VERSION "Version"

NS_ :

BS_:

BU_: IID IDC CCU Tester CCURT1 CCURT2 CCU3 CCU4 AVAS LCUFL LCUFR LCURL LCURR ZCUF ZCUL ZCUR ZCUT PADS MFS VDC ITS BCB IPS DCDC PCU EOP DCU BMC SRS EPS RBM IBCS AMP WHUD ADC RADARRR RADARRL RADARFR RADARFL RPC IFC RADARFRT RADARR HDMAP SBM WCM ETC TBOX DSM FLPDM FRPDM RLPDM RRPDM
VAL_TABLE_ BCS_FLWheelSpdEdgesSumVD 1 "Valid" 0 "Not valid" ;
VAL_TABLE_ UINM_PADS_CruSetSpeedRollerDir 3 "Not used" 2 "Backward" 1 "Forward" 0 "Not rotated" ;
VAL_TABLE_ UINM_PADS_CustomSWStVD 1 "valid" 0 "Not valid" ;
VAL_TABLE_ UINM_PADS_OKSWStuckSt 1 "stuck" 0 "Normal" ;
VAL_TABLE_ UINM_PADS_OKSWStVD 1 "valid" 0 "Not valid" ;
VAL_TABLE_ UINM_PADS_OKSWSt 1 "active" 0 "not active" ;
VAL_TABLE_ UINM_PADS_FolDistDecSWStuckSt 1 "stuck" 0 "Normal" ;
VAL_TABLE_ UINM_PADS_FolDistDecSWStVD 1 "valid" 0 "Not valid" ;
VAL_TABLE_ UINM_PADS_FolDistDecSWSt 1 "active" 0 "not active" ;
VAL_TABLE_ UINM_PADS_FolDistIncSWStuckSt 1 "stuck" 0 "Normal" ;
VAL_TABLE_ UINM_PADS_FolDistIncSWStVD 1 "Description for the value '0x1'" 0 "Not valid" ;
VAL_TABLE_ UINM_PADS_FolDistIncSWSt 1 "active" 0 "not active" ;
VAL_TABLE_ UINM_PADS_CruSetSpeedRollerSt 1 "-offset:0" 0 "-resolution: 1 per bit" ;
VAL_TABLE_ UINM_PADS_IDC_PlaySWStuckSt 1 "stuck" 0 "Normal" ;
VAL_TABLE_ UINM_PADS_IDC_PlaySWStVD 1 "valid" 0 "Not valid" ;
VAL_TABLE_ UINM_PADS_IDC_PlaySWSt 1 "active" 0 "not active" ;
VAL_TABLE_ UINM_PADS_IDC_SkipDecSWStuckSt 1 "stuck" 0 "Normal" ;
VAL_TABLE_ UINM_PADS_IDC_SkipDecSWStVD 1 "Description for the value '0x1'" 0 "Not valid" ;
VAL_TABLE_ UINM_PADS_IDC_SkipDecSWSt 1 "active" 0 "not active" ;
VAL_TABLE_ UINM_PADS_IDC_SkipIncSWStuckSt 1 "stuck" 0 "Normal" ;
VAL_TABLE_ UINM_PADS_IDC_SkipIncSWStVD 1 "valid" 0 "Not valid" ;
VAL_TABLE_ UINM_PADS_IDC_SkipIncSWSt 1 "active" 0 "not active" ;
VAL_TABLE_ UINM_PADS_VolRollerRotatedDir 3 "Not used" 2 "Backward" 1 "Forward" 0 "Not rotated" ;
VAL_TABLE_ UINM_PADS_VolRollerSt 1 "-offset:0" 0 "-resolution: 1 per bit" ;
VAL_TABLE_ UINM_PADS_CustomSWstuck 1 "stuck" 0 "Normal" ;
VAL_TABLE_ UINM_PADS_CustomSWSt 1 "active" 0 "not active" ;
VAL_TABLE_ UINM_PADS_IDC_PhoneStuckSt 1 "stuck" 0 "Normal" ;
VAL_TABLE_ UINM_PADS_IDC_PhoneSWStVD 1 "valid" 0 "Not valid" ;
VAL_TABLE_ UINM_PADS_IDC_PhoneSWSt 1 "active" 0 "not active" ;
VAL_TABLE_ UINM_PADS_IDC_VrSWStuckSt 1 "stuck" 0 "Normal" ;
VAL_TABLE_ UINM_PADS_IDC_VrSWStVD 1 "valid" 0 "Not valid" ;
VAL_TABLE_ UINM_PADS_IDC_VrSWSt 1 "active" 0 "not active" ;
VAL_TABLE_ UINM_PADS_IDC_ViewSWStuckSt 1 "stuck" 0 "Normal" ;
VAL_TABLE_ UINM_PADS_IDC_ViewSWVD 1 "Valid" 0 "Not valid" ;
VAL_TABLE_ UINM_PADS_IDC_ViewSWSt 1 "active" 0 "not active" ;

BO_ 3221225472 VECTOR__INDEPENDENT_SIG_MSG: 0 Vector__XXX
 SG_ CCU_1_Dummy6 : 0|8@1- (1,0) [0|0] "" Vector__XXX
 SG_ CCU_1_Dummy5 : 0|8@1- (1,0) [-128|127] "" Vector__XXX
 SG_ CCU_1_Dummy4 : 0|8@1- (1,0) [-128|127] "" Vector__XXX
 SG_ CCU_1_Dummy4 : 0|64@1- (1,0) [0|0] "" Vector__XXX
 SG_ CCU_1_Dummy3 : 0|10@0+ (1,0) [0|0] "" Vector__XXX
 SG_ CCU_1_Dummy2 : 0|48@0+ (1,0) [0|0] "" Vector__XXX
 SG_ CCU_1_Dummy1 : 0|64@0+ (1,0) [0|0] "" Vector__XXX
 SG_ PAA_VideoSt : 0|3@0+ (1,0) [0|7] "" Vector__XXX
 SG_ VCU_3_Dummy10 : 0|18@0+ (1,0) [0|262143] "" Vector__XXX
 SG_ VCU_3_Dummy9 : 0|51@0+ (1,0) [0|1.84467440737096E+019] "" Vector__XXX
 SG_ VCU_3_Dummy8 : 0|40@0+ (1,0) [0|0] "" Vector__XXX
 SG_ VCU_3_Dummy7 : 0|64@0+ (1,0) [0|0] "" Vector__XXX
 SG_ VCU_3_Dummy6 : 0|11@0+ (1,0) [0|0] "" Vector__XXX
 SG_ VCU_3_Dummy5 : 0|3@0+ (1,0) [0|0] "" Vector__XXX
 SG_ VCU_3_Dummy3 : 0|57@0+ (1,0) [0|0] "" Vector__XXX
 SG_ VCU_3_Dummy2 : 0|64@0+ (1,0) [0|0] "" Vector__XXX
 SG_ VCU_3_Dummy1 : 0|64@0+ (1,0) [0|0] "" Vector__XXX
 SG_ EPS_1_C_Dummy9 : 0|32@0+ (1,0) [0|0] "" Vector__XXX
 SG_ EPS_1_C_Dummy8 : 0|63@0+ (1,0) [0|0] "" Vector__XXX
 SG_ EPS_1_C_Dummy7 : 0|49@0+ (1,0) [0|0] "" Vector__XXX
 SG_ EPS_1_C_Dummy6 : 0|64@0+ (1,0) [0|0] "" Vector__XXX
 SG_ EPS_1_C_Dummy5 : 0|9@0+ (1,0) [0|0] "" Vector__XXX
 SG_ EPS_1_C_Dummy4 : 0|56@0+ (1,0) [0|0] "" Vector__XXX
 SG_ EPS_1_C_Dummy3 : 0|64@0+ (1,0) [0|0] "" Vector__XXX
 SG_ EPS_1_C_Dummy2 : 0|64@0+ (1,0) [0|0] "" Vector__XXX
 SG_ EPS_1_C_Dummy1 : 0|64@0+ (1,0) [0|0] "" Vector__XXX

BO_ 165 IDC_7: 64 IDC
 SG_ ACU_RecpLevelCfg : 345|3@0+ (1,0) [0|7] ""  VDC,CCU,CCURT1

BO_ 1045 IDC_6: 64 IDC
 SG_ ACU_NaviDestInformation : 348|3@0+ (1,0) [0|7] ""  CCU,CCURT1,VDC
 SG_ ACU_NaviViapoint_remainingSoc : 345|10@0+ (0.1,0) [0|100] "%"  CCU,CCURT1,VDC
 SG_ ACU_NaviViapointType : 434|3@0+ (1,0) [0|7] ""  CCU,CCURT1,VDC
 SG_ ACU_NaviViapointtime : 429|11@0+ (1,0) [0|2047] "min"  CCU,CCURT1,VDC
 SG_ ACU_NaviViapointDistance : 402|21@0+ (1,0) [0|2097151] "m"  CCU,CCURT1,VDC
 SG_ ACU_NaviDestTime : 399|12@0+ (1,0) [0|4095] "min"  CCU,CCURT1,VDC
 SG_ ACU_NaviDestDistance : 367|32@0+ (1,0) [0|4294967295] "m"  CCU,CCURT1,VDC

BO_ 742 CCU_ZCUT_MCM_1: 64 CCU
 SG_ SSW_RRMassageSt : 103|2@0+ (1,0) [0|3] ""  IDC
 SG_ SSW_RRLumbarModeSt : 101|3@0+ (1,0) [0|7] ""  IDC
 SG_ SSW_RRSPAMode : 98|2@0+ (1,0) [0|3] ""  IDC
 SG_ SSW_RRMassageModeSt : 95|4@0+ (1,0) [0|15] ""  IDC
 SG_ SSW_RRMassageForceSt : 91|4@0+ (1,0) [0|15] ""  IDC
 SG_ SSW_RLMassageSt : 39|2@0+ (1,0) [0|3] ""  IDC
 SG_ SSW_RLLumbarModeSt : 37|3@0+ (1,0) [0|7] ""  IDC
 SG_ SSW_RLSPAMode : 34|2@0+ (1,0) [0|3] ""  IDC
 SG_ SSW_RLMassageModeSt : 31|4@0+ (1,0) [0|15] ""  IDC
 SG_ SSW_RLMassageForceSt : 27|4@0+ (1,0) [0|15] ""  IDC

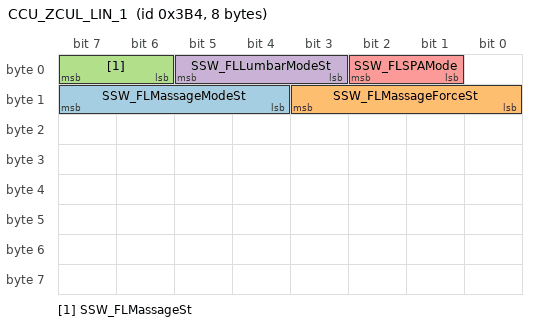
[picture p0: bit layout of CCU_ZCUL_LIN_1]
BO_ 948 CCU_ZCUL_LIN_1: 8 CCU
 SG_ SSW_FLMassageModeSt : 15|4@0+ (1,0) [0|15] ""  IDC
 SG_ SSW_FLMassageForceSt : 11|4@0+ (1,0) [0|15] ""  IDC
 SG_ SSW_FLMassageSt : 7|2@0+ (1,0) [0|3] ""  IDC
 SG_ SSW_FLLumbarModeSt : 5|3@0+ (1,0) [0|7] ""  IDC
 SG_ SSW_FLSPAMode : 2|2@0+ (1,0) [0|3] ""  IDC

BO_ 850 CCU_ZCUT_SCMRR_1: 24 CCU
 SG_ SSW_RRSeatHeatSt : 71|2@0+ (1,0) [0|3] ""  IDC
 SG_ SSW_RRSeatVentSt : 33|2@0+ (1,0) [0|3] ""  IDC

BO_ 849 CCU_ZCUT_SCMRL_1: 24 CCU
 SG_ SSW_RLSeatHeatSt : 71|2@0+ (1,0) [0|3] ""  IDC
 SG_ SSW_RLSeatVentSt : 33|2@0+ (1,0) [0|3] ""  IDC

BO_ 653 VCU_5: 64 CCU
 SG_ VCU_ShootLaunchSt : 34|2@0+ (1,0) [0|3] ""  IBCS,IDC
 SG_ VCU_BrkPedPst : 156|8@0+ (0.392,0) [0|99.96] "%"  ADC,CCURT2,IBCS,IDC,IFC,RBM,SRS
 SG_ VCU_CrntGearLvl : 143|3@0+ (1,0) [0|7] ""  ADC,AMP,CCURT2,EPS,IBCS,IDC,IFC,RBM,SRS,TBOX,ZCUF,ZCUL,ZCUR,ZCUT
 SG_ VCU_BrkPedPstVD : 128|1@0+ (1,0) [0|1] ""  ADC,CCURT2,IBCS,IDC,IFC,RBM,SRS
 SG_ VCU_EMS_BrkPedalSt : 63|1@0+ (1,0) [0|1] ""  ADC,CCURT2,IBCS,IDC,IFC,RBM,SBM,SRS,TBOX,ZCUR
 SG_ VCU_EMS_AccPedalActPst : 40|8@0+ (0.392,0) [0|99.96] "%"  ADC,AMP,CCURT2,IBCS,IDC,IFC,RBM,SRS,TBOX

BO_ 1031 CCU_TBOX_1: 64 CCU
 SG_ TEL_TelematicsModeActSt : 31|3@0+ (1,0) [0|7] ""  IDC
 SG_ TEL_PhoneCallSt : 28|3@0+ (1,0) [0|7] ""  IDC
 SG_ TEL_PhoneNumber : 39|48@0+ (1,0) [0|0] ""  IDC
 SG_ TEL_ResetFailReason : 87|8@0+ (1,0) [0|255] ""  IDC
 SG_ TEL_ModuleResetSt : 95|2@0+ (1,0) [0|3] ""  IDC

BO_ 189 AMP_2: 64 AMP
 SG_ AMP_GetAmpMcuVerInfo : 7|112@0+ (1,0) [0|0] ""  IDC
 SG_ AMP_GetAmpDspVerInfo : 119|112@0+ (1,0) [0|0] ""  IDC
 SG_ AMP_GetAmpHwVerInfo : 231|48@0+ (1,0) [0|0] ""  IDC
 SG_ AMP_GetAmpCfgInfo : 279|128@0+ (1,0) [0|0] ""  IDC

BO_ 363 CCU_EPS_1_C: 64 CCU
 SG_ EPS_1_C_Dummy10 : 247|5@0+ (1,0) [0|0] ""  ADC,CCURT1,CCURT2,IBCS,IDC,IFC,RBM,VDC
 SG_ EPS_1_C_Dummy9 : 31|24@0+ (1,0) [0|0] ""  IDC,ADC,CCU,CCURT1,CCURT2,IBCS,IFC,RBM,VDC
 SG_ EPS_1_C_Dummy8 : 70|63@0+ (1,0) [0|0] ""  IDC,ADC,CCU,CCURT1,CCURT2,IBCS,IFC,RBM,VDC
 SG_ EPS_1_C_Dummy7 : 131|49@0+ (1,0) [0|0] ""  IDC,ADC,CCU,CCURT1,CCURT2,IBCS,IFC,RBM,VDC
 SG_ EPS_1_C_Dummy6 : 178|59@0+ (1,0) [0|5.76460752303423E+017] ""  IDC,ADC,CCU,CCURT1,CCURT2,IBCS,IFC,RBM,VDC
 SG_ EPS_1_C_Dummy5 : 240|9@0+ (1,0) [0|0] ""  IDC,ADC,CCU,CCURT1,CCURT2,IBCS,IFC,RBM,VDC
 SG_ EPS_1_C_Dummy4 : 271|56@0+ (1,0) [0|0] ""  IDC,ADC,CCU,CCURT1,CCURT2,IBCS,IFC,RBM,VDC
 SG_ EPS_1_C_Dummy3 : 327|64@0+ (1,0) [0|0] ""  IDC,ADC,CCU,CCURT1,CCURT2,IBCS,IFC,RBM,VDC
 SG_ EPS_1_C_Dummy2 : 391|64@0+ (1,0) [0|0] ""  IDC,ADC,CCU,CCURT1,CCURT2,IBCS,IFC,RBM,VDC
 SG_ EPS_1_C_Dummy1 : 455|64@0+ (1,0) [0|0] ""  ADC,CCU,CCURT1,CCURT2,IBCS,IFC,RBM,VDC,IDC
 SG_ EPS_1_Counter : 23|8@0+ (1,0) [0|0] ""  IDC,ADC,CCU,CCURT1,CCURT2,IBCS,IFC,RBM,VDC
 SG_ EPS_AssistRatio : 263|8@0+ (1,0) [0|255] ""  IDC
 SG_ EPS_WarnLamp : 242|2@0+ (1,0) [0|3] ""  IDC
 SG_ EPS_SteeringModeSt : 133|2@0+ (1,0) [0|3] ""  IDC
 SG_ EPS_FunctionStyleSt : 135|2@0+ (1,0) [0|3] ""  IDC
 SG_ EPS_SteeringAngleVD : 71|1@0+ (1,0) [0|1] ""  IDC
 SG_ EPS_SteeringAngle : 55|16@0+ (0.1,-780) [-780|779.9] "deg"  IDC
 SG_ EPS_1_CRC : 7|16@0+ (1,0) [0|65535] ""  IDC,ADC,CCU,CCURT1,CCURT2,IBCS,IFC,RBM,VDC

BO_ 430 CCU_SRS_1: 64 CCU
 SG_ SRS_YawRate : 167|16@0+ (0.01,-180) [-180|180] "deg/s"  IDC
 SG_ SRS_VehLatrlAccel : 147|12@0+ (0.001,-2) [2|2] "g"  IDC
 SG_ SRS_VehLongAccel : 143|12@0+ (0.001,2) [2|2] "g"  IDC
 SG_ SRS_NearCrashOutputSt : 34|1@0+ (1,0) [0|1] ""  CCU,CCURT1,CCURT2,IDC,TBOX,VDC
 SG_ SRS_RolloverCrashOutpuSt : 35|1@0+ (1,0) [0|1] ""  CCU,CCURT2,IDC,TBOX
 SG_ SRS_Rear_CrashOutputSt : 36|1@0+ (1,0) [0|1] ""  CCU,CCURT2,IDC,TBOX
 SG_ SRS_RightSide_CrashOutputSt : 37|1@0+ (1,0) [0|1] ""  CCU,CCURT2,IDC,TBOX
 SG_ SRS_LeftSide_CrashOutputSt : 38|1@0+ (1,0) [0|1] ""  CCU,CCURT2,IDC,TBOX
 SG_ SRS_Front_CrashOutputSt : 39|1@0+ (1,0) [0|1] ""  CCU,CCURT2,IDC,TBOX
 SG_ SRS_CrashOutputSt : 31|8@0+ (1,0) [0|160] ""  IDC,CCU,CCURT1,CCURT2,TBOX,VDC

BO_ 334 CCU_15: 64 CCURT1
 SG_ CSM_RC_NextStartTimeCDS : 245|6@0+ (1,0) [0|60] ""  IDC
 SG_ CSM_RC_NextStartTimeCDMi : 235|6@0+ (1,0) [0|60] ""  IDC
 SG_ CSM_RC_NextStartTimeCDH : 224|5@0+ (1,0) [0|24] ""  IDC
 SG_ CSM_RC_NextStartTimeCDD : 229|5@0+ (1,0) [0|31] ""  IDC
 SG_ CSM_RC_NextStartTimeS : 309|6@0+ (1,0) [0|60] ""  IDC
 SG_ CSM_RC_NextStartTimeMi : 299|6@0+ (1,0) [0|60] ""  IDC
 SG_ CSM_RC_NextStartTimeH : 288|5@0+ (1,0) [0|24] ""  IDC
 SG_ CSM_RC_NextStartTimeD : 293|5@0+ (1,0) [0|31] ""  IDC
 SG_ CSM_RC_NextStartTimeMo : 283|4@0+ (1,0) [0|12] ""  IDC
 SG_ CSM_RC_NextStartTimeY : 279|8@0+ (1,2020) [0|2275] ""  IDC

BO_ 348 CCU_SECSYN: 16 CCU
 SG_ CCU_SecSynMAC_Check : 47|88@0+ (1,0) [0|1] ""  ADC,IDC,ZCUF,ZCUL,ZCUR,ZCUT
 SG_ CCU_SecSynResetCounter : 31|16@0+ (1,0) [0|1] ""  ADC,IDC,ZCUF,ZCUL,ZCUR,ZCUT
 SG_ CCU_SecSynCounter : 7|24@0+ (1,0) [0|1] ""  ADC,IDC,ZCUF,ZCUL,ZCUR,ZCUT

BO_ 944 CCU_BMC_3: 64 CCU
 SG_ BMC_3_Dummy8 : 31|48@0+ (1,0) [0|0] ""  DCU,BCB,IDC
 SG_ BMC_3_Dummy7 : 79|64@0+ (1,0) [0|0] ""  DCU,BCB,IDC
 SG_ BMC_3_Dummy6 : 143|64@0+ (1,0) [0|0] ""  DCU,BCB,IDC
 SG_ BMC_3_Dummy5 : 207|64@0+ (1,0) [0|0] ""  DCU,BCB,IDC
 SG_ BMC_3_Dummy4 : 271|64@0+ (1,0) [0|0] ""  DCU,BCB,IDC
 SG_ BMC_3_Dummy3 : 329|50@0+ (1,0) [0|0] ""  DCU,BCB,IDC
 SG_ BMC_3_Dummy2 : 391|64@0+ (1,0) [0|0] ""  DCU,BCB,IDC
 SG_ BMC_3_Dummy1 : 455|64@0+ (1,0) [0|0] ""  DCU,BCB,IDC
 SG_ BMC_LvPwrSysMsgOperationFlag : 330|1@0+ (1,0) [0|1] ""  IDC
 SG_ BMS_Err2NoticeFlag : 331|1@0+ (1,0) [0|1] ""  IDC
 SG_ BMS_ErrNoticeOperationFlag : 332|1@0+ (1,0) [0|1] ""  IDC
 SG_ BMS_ErrNotice : 335|3@0+ (1,0) [0|7] ""  IDC
 SG_ BMC_3_CRC : 7|16@0+ (1,0) [0|65535] ""  BCB,DCU,IDC
 SG_ BMC_3_Counter : 23|8@0+ (1,0) [0|255] ""  DCU,BCB,IDC

BO_ 188 ACU_AMP_1: 64 IDC
 SG_ ACU_MediaPathSet : 247|3@0+ (1,0) [0|7] ""  AMP
 SG_ ACU_NotificationDuckSet : 235|4@0+ (1,0) [0|15] ""  AMP
 SG_ ACU_RingtoneDuckSet : 239|4@0+ (1,0) [0|15] ""  AMP
 SG_ ACU_BTCallDuckSet : 227|4@0+ (1,0) [0|15] ""  AMP
 SG_ ACU_ECallBCallDuckSet : 231|4@0+ (1,0) [0|15] ""  AMP
 SG_ ACU_VRDuckSet : 219|4@0+ (1,0) [0|15] ""  AMP
 SG_ ACU_NaviDuckSet : 223|4@0+ (1,0) [0|15] ""  AMP
 SG_ ACU_AtmosphereMusicDuckSet : 211|4@0+ (1,0) [0|15] ""  AMP
 SG_ ACU_MediaDuckSet : 215|4@0+ (1,0) [0|15] ""  AMP
 SG_ ACU_FamilyCinemaSwitchSts : 201|2@0+ (1,0) [0|3] ""  AMP
 SG_ ACU_A2BSet : 203|2@0+ (1,0) [0|3] ""  AMP
 SG_ ACU_OutcarMediaSwitch : 205|2@0+ (1,0) [0|3] ""  AMP
 SG_ ACU_AVASSwitch : 207|2@0+ (1,0) [0|3] ""  AMP
 SG_ ACU_GetIntVoltReq : 194|2@0+ (1,0) [0|3] ""  AMP
 SG_ ACU_GetTempReq : 196|2@0+ (1,0) [0|3] ""  AMP
 SG_ ACU_AVASMode : 199|3@0+ (1,0) [0|7] ""  AMP
 SG_ ACU_ESEType : 186|3@0+ (1,0) [0|7] ""  AMP
 SG_ ACU_ESESwitchSts : 188|2@0+ (1,0) [0|3] ""  AMP
 SG_ ACU_ESEMode : 191|3@0+ (1,0) [0|7] ""  AMP
 SG_ ACU_AdigoVirtualLiveSetReq : 179|4@0+ (1,0) [0|15] ""  AMP
 SG_ ACU_StrSurSet : 183|4@0+ (1,0) [0|15] ""  AMP
 SG_ ACU_SeatsmodelSet : 170|3@0+ (1,0) [0|7] ""  AMP
 SG_ ACU_Headrest_Mode : 172|2@0+ (1,0) [0|3] ""  AMP
 SG_ ACU_Cabin_ambiencemodeSet : 175|3@0+ (1,0) [0|7] ""  AMP
 SG_ ACU_HeadrestCodriverVolumeSet : 167|8@0+ (1,0) [0|255] ""  AMP
 SG_ ACU_HeadrestDriverVolumeSet : 159|8@0+ (1,0) [0|255] ""  AMP
 SG_ ACU_Headrest_R_PrivateModeVolSet : 151|8@0+ (1,0) [0|255] ""  AMP
 SG_ ACU_Headrest_Left_PrivateModeVol : 143|8@0+ (1,0) [0|255] ""  AMP
 SG_ ACU_OutcarFrontMediaVolSet : 135|8@0+ (1,0) [0|255] ""  AMP
 SG_ ACU_OutcarFrontSPKVolSet : 127|8@0+ (1,0) [0|255] ""  AMP
 SG_ ACU_Cabin_ambienceVolSet : 119|8@0+ (1,0) [0|255] ""  AMP
 SG_ ACU_MainVolSet : 111|8@0+ (1,0) [0|255] ""  AMP
 SG_ ACU_PhoneRingVolSet : 103|8@0+ (1,0) [0|255] ""  AMP
 SG_ ACU_NaviVolSet : 95|8@0+ (1,0) [0|255] ""  AMP
 SG_ ACU_VRVolSet : 87|8@0+ (1,0) [0|255] ""  AMP
 SG_ ACU_TelVolSet : 79|8@0+ (1,0) [0|255] ""  AMP
 SG_ ACU_SpeakRR : 65|2@0+ (1,0) [0|3] ""  AMP
 SG_ ACU_SpeakRL : 67|2@0+ (1,0) [0|3] ""  AMP
 SG_ ACU_SpeakFR : 69|2@0+ (1,0) [0|3] ""  AMP
 SG_ ACU_SpeakFL : 71|2@0+ (1,0) [0|3] ""  AMP
 SG_ ACU_MuteSet : 57|2@0+ (1,0) [0|1] ""  AMP
 SG_ ACU_MuteRearSet : 59|2@0+ (1,0) [0|3] ""  AMP
 SG_ ACU_VSCModeReq : 48|3@0+ (1,0) [0|7] ""  AMP
 SG_ ACU_HighFrqSet : 53|5@0+ (1,0) [0|31] ""  AMP
 SG_ ACU_MidFrqSet : 42|5@0+ (1,0) [0|31] ""  AMP
 SG_ ACU_LowFrqSet : 47|5@0+ (1,0) [0|31] ""  AMP
 SG_ ACU_FaderSet : 36|5@0+ (1,0) [0|31] ""  AMP
 SG_ ACU_BlcSet : 25|5@0+ (1,0) [0|31] ""  AMP
 SG_ ACU_VRSourceSet : 28|3@0+ (1,0) [0|7] ""  AMP
 SG_ ACU_TelSourceSet : 31|3@0+ (1,0) [0|7] ""  AMP
 SG_ ACU_WarningSourceSet : 11|4@0+ (1,0) [0|15] ""  AMP
 SG_ ACU_MediaSourceSet : 15|4@0+ (1,0) [0|15] ""  AMP
 SG_ ACU_SpeakMid : 1|2@0+ (1,0) [0|3] ""  AMP
 SG_ ACU_NaviSourceSet : 4|3@0+ (1,0) [0|7] ""  AMP
 SG_ ACU_BeepSourceSet : 7|3@0+ (1,0) [0|7] ""  AMP

BO_ 767 AMP_1: 64 AMP
 SG_ AMP_MediaPathSt : 271|3@0+ (1,0) [0|7] ""  IDC
 SG_ AMP_NotificationDuckSet : 259|4@0+ (1,0) [0|15] ""  IDC
 SG_ AMP_RingtoneDuckSet : 263|4@0+ (1,0) [0|15] ""  IDC
 SG_ AMP_BTCallDuckSet : 251|4@0+ (1,0) [0|15] ""  IDC
 SG_ AMP_ECallBCallDuckSet : 255|4@0+ (1,0) [0|15] ""  IDC
 SG_ AMP_VRDuckSet : 243|4@0+ (1,0) [0|15] ""  IDC
 SG_ AMP_NaviDuckSet : 247|4@0+ (1,0) [0|15] ""  IDC
 SG_ AMP_AtmosphereMusicDuckSet : 235|4@0+ (1,0) [0|15] ""  IDC
 SG_ AMP_MediaDuckSet : 239|4@0+ (1,0) [0|15] ""  IDC
 SG_ AMP_BeepSourceSts : 7|3@0+ (1,0) [0|7] ""  IDC
 SG_ AMP_NaviSourceSt : 4|3@0+ (1,0) [0|7] ""  IDC
 SG_ AMP_SpeakMid : 1|2@0+ (1,0) [0|3] ""  IDC
 SG_ AMP_MediaSourceSt : 15|4@0+ (1,0) [0|15] ""  IDC
 SG_ AMP_WarningSourceSts : 11|4@0+ (1,0) [0|15] ""  IDC
 SG_ AMP_TelSourceSts : 31|3@0+ (1,0) [0|7] ""  IDC
 SG_ AMP_VRSourceSts : 28|3@0+ (1,0) [0|7] ""  IDC
 SG_ AMP_BlcSetSt : 25|5@0+ (1,0) [0|31] ""  IDC
 SG_ AMP_FadeSetSt : 36|5@0+ (1,0) [0|31] ""  IDC
 SG_ AMP_LowFrqSet : 47|5@0+ (1,0) [0|31] ""  IDC
 SG_ AMP_MidFrqSet : 42|5@0+ (1,0) [0|31] ""  IDC
 SG_ AMP_HighFrqSet : 53|5@0+ (1,0) [0|31] ""  IDC
 SG_ AMP_VSCModeSt : 48|3@0+ (1,0) [0|7] ""  IDC
 SG_ AMP_DriveSideSt : 61|2@0+ (1,0) [0|3] ""  IDC
 SG_ AMP_MuteRearSet : 59|2@0+ (1,0) [0|3] ""  IDC
 SG_ AMP_MuteSt : 57|2@0+ (1,0) [0|3] ""  IDC
 SG_ AMP_SpeakFL : 71|2@0+ (1,0) [0|3] ""  IDC
 SG_ AMP_SpeakrFR : 69|2@0+ (1,0) [0|3] ""  IDC
 SG_ AMP_SpeakrRL : 67|2@0+ (1,0) [0|3] ""  IDC
 SG_ AMP_SpeakrRR : 65|2@0+ (1,0) [0|3] ""  IDC
 SG_ AMP_TelVolSetSts : 79|8@0+ (1,0) [0|255] ""  IDC
 SG_ AMP_VRVolSetSts : 87|8@0+ (1,0) [0|255] ""  IDC
 SG_ AMP_NaviVolSetSts : 95|8@0+ (1,0) [0|255] ""  IDC
 SG_ AMP_PhoneRingVolSetSts : 103|8@0+ (1,0) [0|255] ""  IDC
 SG_ AMP_MainVolSetSts : 111|8@0+ (1,0) [0|255] ""  IDC
 SG_ AMP_Cabin_ambienceVolSetSts : 119|8@0+ (1,0) [0|255] ""  IDC
 SG_ AMP_OutcarFrontSPKVolSetSts : 127|8@0+ (1,0) [0|255] ""  IDC
 SG_ AMP_OutcarFrontMediaVolSetSts : 135|8@0+ (1,0) [0|255] ""  IDC
 SG_ AMP_Headrest_Left_PrivateModeVol : 143|8@0+ (1,0) [0|255] ""  IDC
 SG_ AMP_Headrest_Right_PrivateModeVo : 151|8@0+ (1,0) [0|255] ""  IDC
 SG_ AMP_HeadrestDriverVolumeSt : 159|8@0+ (1,0) [0|255] ""  IDC
 SG_ AMP_Cabin_ambiencemodeSet : 175|3@0+ (1,0) [0|7] ""  IDC
 SG_ AMP_Headrest_Mode : 172|2@0+ (1,0) [0|3] ""  IDC
 SG_ AMP_SeatsmodeSet : 170|3@0+ (1,0) [0|7] ""  IDC
 SG_ AMP_StrSurSet : 183|4@0+ (1,0) [0|15] ""  IDC
 SG_ AMP_AdigoVirtualLiveSeSts : 179|4@0+ (1,0) [0|15] ""  IDC
 SG_ AMP_ESEMode : 191|3@0+ (1,0) [0|7] ""  IDC
 SG_ AMP_ESESwitchSts : 188|2@0+ (1,0) [0|3] ""  IDC
 SG_ AMP_ESEType : 186|3@0+ (1,0) [0|7] ""  IDC
 SG_ AMP_AVASMode : 199|3@0+ (1,0) [0|7] ""  IDC
 SG_ AMP_AVASSwitch : 207|2@0+ (1,0) [0|3] ""  IDC
 SG_ AMP_OutcarMediaSwitch : 205|2@0+ (1,0) [0|3] ""  IDC
 SG_ AMP_A2BSet : 203|2@0+ (1,0) [0|3] ""  IDC
 SG_ AMP_FamilyCinemaSwitchSts : 201|2@0+ (1,0) [0|3] ""  IDC
 SG_ AMP_TempValue : 215|8@0+ (1,0) [0|255] ""  IDC
 SG_ AMP_VolValue : 223|8@0+ (1,0) [0|255] ""  IDC
 SG_ AMP_GetHUTInfoSts : 231|2@0+ (1,0) [0|3] ""  IDC
 SG_ AMP_HeadrestCodriverVolumeSt : 167|8@0+ (1,0) [0|255] ""  IDC

BO_ 873 CCU_DCDC_2: 32 CCU
 SG_ DCDC_FaultLampInd : 53|1@0+ (1,0) [0|1] ""  IDC
 SG_ DCDC_FaultLampIndOperationFlag : 48|1@0+ (1,0) [0|1] ""  IDC

BO_ 163 IDC_11: 64 IDC
 SG_ ACU_DPMessageSt : 79|3@0+ (1,0) [0|7] ""  CCU
 SG_ ACU_RAEBcfg : 2|2@0+ (1,0) [0|2] ""  ADC,CCU
 SG_ ACU_ParkingBoxAngle : 111|12@0+ (0.1,-180) [-180|180] ""  ADC,CCU
 SG_ ACU_ParkingBoxMidY : 91|12@0+ (1,0) [0|1079] ""  ADC,CCU
 SG_ ACU_ParkingBoxMidX : 87|12@0+ (1,0) [0|1919] ""  ADC,CCU
 SG_ ACU_AVPMessageSt : 52|3@0+ (1,0) [0|7] ""  ADC,CCU
 SG_ ACU_HPAMessageSt : 55|3@0+ (1,0) [0|7] ""  ADC,CCU
 SG_ ACU_APAMessageSt : 43|3@0+ (1,0) [0|7] ""  ADC,CCU
 SG_ ACU_NDAVoicePromptTypeCfg : 127|2@0+ (1,0) [0|3] ""  ADC,CCU
 SG_ ACU_LowPowerConfig : 114|3@0+ (1,0) [0|7] ""  ADC,CCU
 SG_ ACU_PCSModeSt : 115|1@0+ (1,0) [0|1] ""  ADC,CCU
 SG_ ACU_PCS_MirrorpagedownButtonST : 0|1@0+ (1,0) [0|1] ""  ADC,CCU
 SG_ ACU_DisplayReq : 71|2@0+ (1,0) [0|3] ""  ADC,CCU
 SG_ ACU_PCS_ScreenCoordX : 39|12@0+ (1,0) [0|2559] ""  ADC,CCU
 SG_ ACU_PCS_ScreenCoordY : 19|12@0+ (1,0) [0|1439] ""  ADC,CCU
 SG_ ACU_PCS_ScreenTouchSignal : 66|2@0+ (1,0) [0|3] ""  CCU
 SG_ ACU_PCS_ER_QuitConfirm : 56|1@0+ (1,0) [0|1] ""  ADC,CCU
 SG_ ACU_PCS_ER_EnterCmd : 67|1@0+ (1,0) [0|1] ""  ADC,CCU
 SG_ ACU_ER_FuncCfg : 69|2@0+ (1,0) [0|3] ""  ADC,CCU
 SG_ ACU_PCS_SVM_FunctionCmd : 23|4@0+ (1,0) [0|15] ""  ADC,CCU
 SG_ ACU_LanguageTypeSet : 13|6@0+ (1,0) [0|63] ""  ADC,CCU
 SG_ ACU_PCS_ScreenTouchSt : 15|2@0+ (1,0) [0|3] ""  ADC,CCU
 SG_ ACU_SVM_Button : 3|1@0+ (1,0) [0|1] ""  ADC,CCU
 SG_ ACU_PAAMode : 7|4@0+ (1,0) [0|15] ""  CCU,ADC

BO_ 739 IDC_IID_1: 64 IDC
 SG_ IDC_ICM_2_Dummy6 : 487|32@0+ (1,0) [0|4294967295] "" Vector__XXX
 SG_ IDC_ICM_2_Dummy5 : 423|64@0+ (1,0) [0|0] "" Vector__XXX
 SG_ IDC_ICM_2_Dummy4 : 359|64@0+ (1,0) [0|0] "" Vector__XXX
 SG_ IDC_ICM_2_Dummy3 : 295|64@0+ (1,0) [0|0] "" Vector__XXX
 SG_ IDC_ICM_2_Dummy2 : 231|64@0+ (1,0) [0|0] "" Vector__XXX
 SG_ Reserve : 63|24@0+ (1,0) [0|0] "" Vector__XXX
 SG_ ICM_VehicleSpeed : 55|8@0+ (1,0) [0|254] "km/h"  IID
 SG_ ICM_FS_Enable : 31|8@0+ (1,0) [0|255] ""  IID
 SG_ IDC_IID_1_CRC : 7|16@0+ (1,0) [0|65535] ""  IID
 SG_ ICM_ADAS4Lamp : 223|8@0+ (1,0) [0|255] ""  IID
 SG_ ICM_ADAS3Lamp : 215|8@0+ (1,0) [0|255] ""  IID
 SG_ ICM_ADAS2Lamp : 207|8@0+ (1,0) [0|255] ""  IID
 SG_ ICM_ADAS1Lamp : 199|8@0+ (1,0) [0|255] ""  IID
 SG_ ICM_HandsOffLamp : 191|8@0+ (1,0) [0|255] ""  IID
 SG_ ICM_BrakeLamp : 183|8@0+ (1,0) [0|255] ""  IID
 SG_ ICM_EPBLamp : 175|8@0+ (1,0) [0|255] ""  IID
 SG_ ICM_PlugConnectLamp : 167|8@0+ (1,0) [0|255] ""  IID
 SG_ ICM_DCDCFailLamp : 159|8@0+ (1,0) [0|255] ""  IID
 SG_ ICM_DynamicalsystemFailLamp : 151|8@0+ (1,0) [0|255] ""  IID
 SG_ ICM_SRSLamp : 143|8@0+ (1,0) [0|255] ""  IID
 SG_ ICM_EPSLamp : 135|8@0+ (1,0) [0|255] ""  IID
 SG_ ICM_EPBFailLamp : 127|8@0+ (1,0) [0|255] ""  IID
 SG_ ICM_ESPOFFLamp : 119|8@0+ (1,0) [0|255] ""  IID
 SG_ ICM_ESPLamp : 111|8@0+ (1,0) [0|255] ""  IID
 SG_ ICM_ABSLamp : 103|8@0+ (1,0) [0|255] ""  IID
 SG_ DataLength : 95|8@0+ (1,0) [0|255] ""  IID
 SG_ SID : 87|8@0+ (1,0) [0|255] ""  IID
 SG_ ICM_GearInfo : 47|8@0+ (1,0) [0|255] ""  IID
 SG_ ICM_Theme : 39|8@0+ (1,0) [0|255] ""  IID
 SG_ IDC_IID_1_Counter : 23|8@0+ (1,0) [0|255] ""  IID

BO_ 918 CCU_PADS_1: 32 CCU
 SG_ UINM_PADS_VolRollerVD : 62|1@0+ (1,0) [0|1] ""  IDC
 SG_ UINM_PADS_VolRollerSt : 37|6@0+ (1,0) [0|63] ""  IDC
 SG_ UINM_PADS_VolRollerRotatedDir : 29|2@0+ (1,0) [0|3] ""  IDC
 SG_ UINM_PADS_R_UpSWStVD : 167|1@0+ (1,0) [0|1] ""  IDC
 SG_ UINM_PADS_R_UpSWSt : 166|1@0+ (1,0) [0|1] ""  IDC
 SG_ UINM_PADS_R_UDRollerVD : 182|1@0+ (1,0) [0|1] ""  IDC
 SG_ UINM_PADS_R_UDRollerRSt : 181|6@0+ (1,0) [0|63] ""  IDC
 SG_ UINM_PADS_R_UDRollerRotatedDir : 175|2@0+ (1,0) [0|3] ""  IDC
 SG_ UINM_PADS_R_RightSWStVD : 173|1@0+ (1,0) [0|1] ""  IDC
 SG_ UINM_PADS_R_RightSWSt : 172|1@0+ (1,0) [0|1] ""  IDC
 SG_ UINM_PADS_R_LRRollerVD : 183|1@0+ (1,0) [0|1] ""  IDC
 SG_ UINM_PADS_R_LRRollerRSt : 191|6@0+ (1,0) [0|63] ""  IDC
 SG_ UINM_PADS_R_LRRollerRotatedDir : 185|2@0+ (1,0) [0|3] ""  IDC
 SG_ UINM_PADS_R_LeftSWStVD : 171|1@0+ (1,0) [0|1] ""  IDC
 SG_ UINM_PADS_R_leftSWSt : 170|1@0+ (1,0) [0|1] ""  IDC
 SG_ UINM_PADS_R_DownSWStVD : 169|1@0+ (1,0) [0|1] ""  IDC
 SG_ UINM_PADS_R_DownSWSt : 168|1@0+ (1,0) [0|1] ""  IDC
 SG_ UINM_PADS_L_UpSWStVD : 141|1@0+ (1,0) [0|1] ""  IDC
 SG_ UINM_PADS_L_UpSWSt : 140|1@0+ (1,0) [0|1] ""  IDC
 SG_ UINM_PADS_L_UDRollerRSt : 157|6@0+ (1,0) [0|63] ""  IDC
 SG_ UINM_PADS_L_UDRollerRotatedDir : 149|2@0+ (1,0) [0|3] ""  IDC
 SG_ UINM_PADS_L_RightSWStVD : 147|1@0+ (1,0) [0|1] ""  IDC
 SG_ UINM_PADS_L_RightSWSt : 146|1@0+ (1,0) [0|1] ""  IDC
 SG_ UINM_PADS_L_LRRollerVD : 159|1@0+ (1,0) [0|1] ""  IDC
 SG_ UINM_PADS_L_LRRollerRSt : 165|6@0+ (1,0) [0|63] ""  IDC
 SG_ UINM_PADS_L_LRRollerRotatedDir : 151|2@0+ (1,0) [0|3] ""  IDC
 SG_ UINM_PADS_L_LeftSWStVD : 145|1@0+ (1,0) [0|1] ""  IDC
 SG_ UINM_PADS_L_leftSWSt : 144|1@0+ (1,0) [0|1] ""  IDC
 SG_ UINM_PADS_L_DownSWStVD : 143|1@0+ (1,0) [0|1] ""  IDC
 SG_ UINM_PADS_L_DownSWSt : 142|1@0+ (1,0) [0|1] ""  IDC
 SG_ UINM_PADS_Custom2SWStVD : 110|1@0+ (1,0) [0|1] ""  IDC
 SG_ UINM_PADS_Custom2SWSt : 109|1@0+ (1,0) [0|1] ""  IDC
 SG_ UINM_PADS_CruSetSpeedRollerVD : 63|1@0+ (1,0) [0|1] ""  IDC
 SG_ UINM_PADS_Custom2SWStuckSt : 111|1@0+ (1,0) [0|1] ""  IDC
 SG_ UINM_PADS_CruSetSpeedRollerRotat : 46|2@0+ (1,0) [0|3] ""  ADC,IDC
 SG_ UINM_PADS_OKSWStuckSt : 61|1@0+ (1,0) [0|1] ""  ADC,IDC
 SG_ UINM_PADS_OKSWStVD : 60|1@0+ (1,0) [0|1] ""  ADC,IDC
 SG_ UINM_PADS_OKSWSt : 59|1@0+ (1,0) [0|1] ""  ADC,IDC
 SG_ UINM_PADS_FolDistDecSWStuckSt : 58|1@0+ (1,0) [0|1] ""  ADC,IDC
 SG_ UINM_PADS_FolDistDecSWStVD : 57|1@0+ (1,0) [0|1] ""  ADC,IDC
 SG_ UINM_PADS_FolDistDecSWSt : 56|1@0+ (1,0) [0|1] ""  ADC,IDC
 SG_ UINM_PADS_FolDistIncSWStuckSt : 55|1@0+ (1,0) [0|1] ""  ADC,IDC
 SG_ UINM_PADS_FolDistIncSWStVD : 54|1@0+ (1,0) [0|1] ""  ADC,IDC
 SG_ UINM_PADS_FolDistIncSWSt : 47|1@0+ (1,0) [0|1] ""  ADC,IDC
 SG_ UINM_PADS_CruSetSpeedRollerSt : 53|6@0+ (1,0) [0|63] ""  ADC,IDC
 SG_ UINM_PADS_IDC_PlaySWStuckSt : 44|1@0+ (1,0) [0|1] ""  ADC,IDC
 SG_ UINM_PADS_IDC_PlaySWStVD : 43|1@0+ (1,0) [0|1] ""  ADC,IDC
 SG_ UINM_PADS_IDC_PlaySWSt : 42|1@0+ (1,0) [0|1] ""  ADC,IDC
 SG_ UINM_PADS_IDC_SkipDecSWStuckSt : 41|1@0+ (1,0) [0|1] ""  ADC,IDC
 SG_ UINM_PADS_IDC_SkipDecSWStVD : 40|1@0+ (1,0) [0|1] ""  ADC,IDC
 SG_ UINM_PADS_IDC_SkipDecSWSt : 39|1@0+ (1,0) [0|1] ""  ADC,IDC
 SG_ UINM_PADS_IDC_SkipIncSWStuckSt : 38|1@0+ (1,0) [0|1] ""  ADC,IDC
 SG_ UINM_PADS_IDC_SkipIncSWStVD : 31|1@0+ (1,0) [0|1] ""  ADC,IDC
 SG_ UINM_PADS_IDC_SkipIncSWSt : 30|1@0+ (1,0) [0|1] ""  ADC,IDC
 SG_ UINM_PADS_CustomSWstuck : 27|1@0+ (1,0) [0|1] ""  ADC,IDC
 SG_ UINM_PADS_CustomSWStVD : 26|1@0+ (1,0) [0|1] ""  ADC,IDC
 SG_ UINM_PADS_CustomSWSt : 25|1@0+ (1,0) [0|1] ""  ADC,IDC
 SG_ UINM_PADS_IDC_PhoneStuckSt : 24|1@0+ (1,0) [0|1] ""  ADC,IDC
 SG_ UINM_PADS_IDC_PhoneSWStVD : 23|1@0+ (1,0) [0|1] ""  ADC,IDC
 SG_ UINM_PADS_IDC_PhoneSWSt : 22|1@0+ (1,0) [0|1] ""  ADC,IDC
 SG_ UINM_PADS_IDC_VrSWStuckSt : 21|1@0+ (1,0) [0|1] ""  ADC,IDC
 SG_ UINM_PADS_IDC_VrSWStVD : 20|1@0+ (1,0) [0|1] ""  ADC,IDC
 SG_ UINM_PADS_IDC_VrSWSt : 19|1@0+ (1,0) [0|1] ""  ADC,IDC
 SG_ UINM_PADS_IDC_ViewSWStuckSt : 18|1@0+ (1,0) [0|1] ""  ADC,IDC
 SG_ UINM_PADS_IDC_ViewSWVD : 17|1@0+ (1,0) [0|1] ""  ADC,IDC
 SG_ UINM_PADS_IDC_ViewSWSt : 16|1@0+ (1,0) [0|1] ""  ADC,IDC

BO_ 905 IDC_ICM_1: 64 IDC
 SG_ ICM_SoundWarnSilenceReq : 169|1@0+ (1,0) [0|1] ""  CCU,CCURT1,CCURT2
 SG_ ICM_DispTheme : 183|3@0+ (1,0) [0|7] ""  CCU,CCURT2
 SG_ ICM_DisplayID : 268|4@0+ (1,0) [0|15] ""  CCU
 SG_ ICM_VehInsSpd_accurate : 272|11@0+ (0.1,0) [0|204] "km/h"  CCURT1,VDC,CCU,CCURT2
 SG_ ICM_VehRunningOdometer : 356|17@0+ (1,0) [0|99999] "km"  CCU,CCURT2
 SG_ ICM_VehRunningOdometerTemp : 341|17@0+ (1,0) [0|9999] "km"  CCU,CCURT2
 SG_ ICM_VehRunningTimeTemp : 321|12@0+ (1,0) [0|4095] "min"  CCU,CCURT2
 SG_ ICM_TotalAvaibleDriveDistance : 316|11@0+ (1,0) [0|2047] "km"  CCU,CCURT2
 SG_ ICM_FuelAvaibleDriveDistance : 311|11@0+ (1,0) [0|2047] "km"  CCU,CCURT2
 SG_ ICM_FuelLevelValue : 303|8@0+ (0.3,0) [0|75] "L"  CCU,CCURT2
 SG_ ICM_BackLightLevel_accurate : 279|7@0+ (1,0) [0|100] "%"  CCU,CCURT2
 SG_ ICM_MFSButtonSt : 31|4@0+ (1,0) [0|15] ""  CCU,CCURT2
 SG_ ICM_SetIACCSt : 27|1@0+ (1,0) [0|1] ""  CCU,CCURT2
 SG_ ICM_VehicleBrakeSt : 26|1@0+ (1,0) [0|1] ""  CCU,CCURT2
 SG_ ICM_AirbagLampFaultSt : 25|1@0+ (1,0) [0|1] ""  CCU,CCURT2
 SG_ ICM_ChargingSt : 24|1@0+ (1,0) [0|1] ""  CCU,CCURT2
 SG_ ICM_BackLightLevel : 39|4@0+ (1,0) [0|15] ""  CCU,CCURT2
 SG_ ICM_TotalOdometer : 35|20@0+ (1,0) [0|999999] "km"  CCU,CCURT2
 SG_ ICM_VehAverageSpd : 63|8@0+ (1,0) [0|254] "km/h"  CCU,CCURT2
 SG_ ICM_BFLWarning : 71|1@0+ (1,0) [0|1] ""  CCU,CCURT2
 SG_ ICM_TripAVD : 70|1@0+ (1,0) [0|1] ""  CCU,CCURT2
 SG_ ICM_TripA : 69|14@0+ (0.1,0) [0|999.9] "km"  CCU,CCURT2
 SG_ ICM_ElcConspAccumAvgClnCmd : 87|1@0+ (1,0) [0|1] ""  CCU,CCURT2
 SG_ ICM_TripBVD : 86|1@0+ (1,0) [0|1] ""  CCU,CCURT2
 SG_ ICM_TripB : 85|14@0+ (1,0) [0|9999] "km"  CCU,CCURT2
 SG_ ICM_VehInsSpd : 103|8@0+ (1,0) [0|254] "km/h"  CCU,CCURT2
 SG_ ICM_BattVolt : 111|8@0+ (0.1,0) [0|25.4] "V"  CCU,CCURT2
 SG_ ICM_BattVoltVD : 119|1@0+ (1,0) [0|1] ""  CCU,CCURT2
 SG_ ICM_DisFail : 118|1@0+ (1,0) [0|1] ""  CCU,CCURT2
 SG_ ICM_QDashACCFail : 117|2@0+ (1,0) [0|3] ""  CCU,CCURT2
 SG_ ICM_TempUnitDisp : 115|1@0+ (1,0) [0|1] ""  CCU,CCURT2
 SG_ ICM_PrUnitDisp : 114|2@0+ (1,0) [0|3] ""  CCU,CCURT2
 SG_ ICM_TimeModeCfgSt : 112|1@0+ (1,0) [0|1] ""  CCU,CCURT2
 SG_ ICM_VehRunningTime : 127|16@0+ (1,0) [0|59999] "min"  CCU,CCURT2
 SG_ ICM_SpdWarnCfgSt : 143|5@0+ (10,0) [0|200] "km/h"  CCU,CCURT2
 SG_ ICM_LanguageCfgSt : 138|3@0+ (1,0) [0|7] ""  CCU,CCURT2
 SG_ ICM_TotalOdometer_accurate : 151|24@0+ (0.1,0) [0|999999.9] "km"  CCU,CCURT2
 SG_ ICM_WarnSoundVolCfgSt : 175|2@0+ (1,0) [0|3] ""  CCU,CCURT2
 SG_ IDC_ICM_1_FreshnessValue : 455|16@0+ (1,0) [0|255] ""  CCU,CCURT2
 SG_ IDC_ICM_1_MAC_Check : 471|48@0+ (1,0) [0|255] ""  CCU,CCURT2

BO_ 161 IDC_1: 64 IDC
 SG_ ACU_AccurHMIModeReq : 240|2@0+ (1,0) [0|3] ""  CCU,CCURT1,VDC
 SG_ ACU_RecpLevelCfgL : 254|7@0+ (1,0) [0|127] "%"  CCU,CCURT1,VDC
 SG_ ACU_BrkPedalModsetting : 78|7@0+ (1,0) [0|100] "%"  CCU,IBCS,TBOX
 SG_ ACU_AccPdlLvlCfg : 247|7@0+ (1,0) [0|101] "%"  CCU,CCURT1,VDC
 SG_ ACU_AccurRngReq : 233|2@0+ (1,0) [0|3] ""  CCU,CCURT1,VDC
 SG_ ACU_EPSSteeringassistRatio : 271|8@0+ (1,0) [0|255] ""  CCU,CCURT1
 SG_ ACU_RecpLevelCfg : 2|3@0+ (1,0) [0|7] ""  CCU,CCURT1,CCURT2,VDC
 SG_ ACU_IpedalCreepCfg : 5|3@0+ (1,0) [0|7] ""  CCU,CCURT1,CCURT2,VDC
 SG_ ACU_DischgSt : 7|2@0+ (1,0) [0|3] ""  CCU,CCURT1,CCURT2,VDC
 SG_ ACU_EpedalCfg : 10|3@0+ (1,0) [0|7] ""  CCU,CCURT1,CCURT2,VDC
 SG_ ACU_ESPST : 15|2@0+ (1,0) [0|3] ""  CCU,IBCS
 SG_ ACU_WarmTimeCfg : 19|4@0+ (1,0) [0|15] ""  CCU,CCURT1,CCURT2,VDC
 SG_ ACU_DrvModCfg : 22|3@0+ (1,0) [0|7] ""  CCU,CCURT1,CCURT2,VDC
 SG_ ACU_DischgSocCfg : 30|7@0+ (1,0) [0|100] "%"  CCU,CCURT1,CCURT2,VDC
 SG_ ACU_EcoPlusModeCfg : 37|2@0+ (1,0) [0|3] ""  CCU,CCURT1,CCURT2,VDC
 SG_ ACU_LongDistCfg : 39|2@0+ (1,0) [0|3] ""  CCU,CCURT1,CCURT2,VDC
 SG_ ACU_ChgSOCCfg : 45|4@0+ (1,0) [0|15] ""  CCU,CCURT1,CCURT2,VDC
 SG_ ACU_ChgPlugRelReq : 41|2@0+ (1,0) [0|3] ""  CCU,CCURT1,CCURT2,VDC
 SG_ ACU_EPBSwitchSt : 55|2@0+ (1,0) [0|3] ""  CCU,CCURT2
 SG_ ACU_DragModeReq : 53|2@0+ (1,0) [0|2] ""  CCU,CCURT2
 SG_ ACU_AVHSoftSwitchst : 51|2@0+ (1,0) [0|2] ""  CCU,CCURT2
 SG_ ACU_CST_OFFSwitch : 49|2@0+ (1,0) [0|3] ""  CCU,CCURT2
 SG_ ACU_EPSStyleCfg : 63|2@0+ (1,0) [0|3] ""  CCU,CCURT2
 SG_ ACU_EPSCoupleFunctionSt : 61|1@0+ (1,0) [0|1] ""  CCU
 SG_ ACU_ESPFuncSwCfg : 60|2@0+ (1,0) [0|3] ""  CCU,CCURT2
 SG_ ACU_BrkPedalModeCfg : 58|2@0+ (1,0) [0|3] ""  CCU
 SG_ IDC_DrvSwapModCfg : 71|2@0+ (1,0) [0|3] ""  CCU,CCURT1,VDC
 SG_ ACU_ChgmodeReq : 69|2@0+ (1,0) [0|3] ""  CCU,CCURT1,VDC
 SG_ ACU_TELInComingCallAnswerReq : 67|1@0+ (1,0) [0|1] "-"  CCU,CCURT2
 SG_ ACU_TELCallHangUpReq : 66|1@0+ (1,0) [0|1] "-"  CCU,CCURT2
 SG_ ACU_TELBcallReq : 65|1@0+ (1,0) [0|1] "-"  CCU,CCURT2
 SG_ ACU_TELEcallReq : 64|1@0+ (1,0) [0|1] "-"  CCU
 SG_ ACU_TelModuleResetReq : 79|1@0+ (1,0) [0|1] "-"  CCU,CCURT2
 SG_ ACU_AuthRand : 87|16@0+ (1,0) [0|65535] "-"  CCU,CCURT1,VDC
 SG_ ACU_AuthKey : 103|16@0+ (1,0) [0|65535] "-"  CCU,CCURT1,VDC

BO_ 351 IDC_2: 64 IDC
 SG_ IDC_2_Dummy17 : 61|2@0+ (1,0) [0|0] ""  CCU,CCURT2
 SG_ IDC_2_Dummy16 : 57|9@0+ (1,0) [0|0] ""  CCU,CCURT2
 SG_ IDC_2_Dummy15 : 103|2@0+ (1,0) [0|0] ""  CCU,CCURT2
 SG_ IDC_2_Dummy14 : 105|8@0+ (1,0) [0|0] ""  CCU,CCURT2
 SG_ IDC_2_Dummy13 : 121|23@0+ (1,0) [0|0] ""  CCU,CCURT2
 SG_ IDC_2_Dummy12 : 165|8@0+ (1,0) [0|0] ""  CCU,CCURT2
 SG_ IDC_2_Dummy11 : 217|2@0+ (1,0) [0|0] ""  CCU,CCURT2
 SG_ IDC_2_Dummy10 : 235|2@0+ (1,0) [0|0] ""  CCU,CCURT2
 SG_ IDC_2_Dummy9 : 255|1@0+ (1,0) [0|0] ""  CCU,CCURT2
 SG_ IDC_2_Dummy8 : 311|4@0+ (1,0) [0|0] ""  CCU,CCURT2
 SG_ IDC_2_Dummy7 : 343|2@0+ (1,0) [0|0] ""  CCU,CCURT2
 SG_ IDC_2_Dummy6 : 351|2@0+ (1,0) [0|0] ""  CCU,CCURT2
 SG_ IDC_2_Dummy5 : 359|56@0+ (1,0) [0|0] ""  CCU,CCURT2
 SG_ IDC_2_Dummy4 : 417|23@0+ (1,0) [0|0] ""  CCU,CCURT2
 SG_ IDC_2_Dummy3 : 455|3@0+ (1,0) [0|0] ""  CCU,CCURT2
 SG_ IDC_2_Dummy2 : 458|12@0+ (1,0) [0|0] ""  CCU,CCURT2
 SG_ IDC_2_Dummy1 : 472|33@0+ (1,0) [0|0] ""  CCU,CCURT2
 SG_ IDC_2_Counter : 23|8@0+ (1,0) [0|255] ""  CCU,CCURT2
 SG_ IDC_2_CRC : 7|16@0+ (1,0) [0|65535] ""  CCU,CCURT2
 SG_ ACU_RLSeatHeatLevelReq : 478|3@0+ (1,0) [0|7] ""  CCU,CCURT2
 SG_ ACU_RRSeatHeatLevelReq : 475|3@0+ (1,0) [0|7] ""  CCU,CCURT2
 SG_ ACU_RRSeatVentLevelReq : 346|3@0+ (0.5,0) [0|7] ""  CCU,CCURT2
 SG_ ACU_RLSeatVentLevelReq : 349|3@0+ (0.5,0) [0|7] ""  CCU,CCURT2
 SG_ ACU_RRSeatAutoModeCfgReq : 254|3@0+ (1,0) [0|7] ""  CCU,CCURT2
 SG_ ACU_RLSeatAutoModeCfgReq : 251|3@0+ (1,0) [0|7] ""  CCU,CCURT2
 SG_ ACU_RearCamWasherVRReq : 193|2@0+ (1,0) [0|3] ""  CCU,CCURT2
 SG_ ACU_RearCamWasherVKReq : 195|2@0+ (1,0) [0|3] ""  CCU,CCURT2
 SG_ ACU_Account_Uld : 171|4@0+ (1,0) [0|15] ""  CCU,CCURT2
 SG_ ACU_FRSeatSaveRecallReq : 261|3@0+ (1,0) [0|7] ""  CCU,CCURT2
 SG_ ACU_FRSeatSaveRecallPstReq : 258|3@0+ (1,0) [0|7] ""  CCU,CCURT2
 SG_ ACU_FLLumbarReq : 248|3@0+ (1,0) [0|7] ""  CCU,CCURT2
 SG_ ACU_HVACF_CO2LifeAlarmModeCfg : 59|2@0+ (1,0) [0|3] ""  CCU,CCURT2
 SG_ ACU_HVACFInCarAutoVentilationCfg : 63|2@0+ (1,0) [0|3] ""  CCU,CCURT2
 SG_ ACU_HVACF_CO2CleanReqFb : 49|2@0+ (1,0) [0|3] ""  CCURT2,CCU
 SG_ ACU_EEM_LoadControl : 113|2@0+ (1,0) [0|3] ""  CCU,CCURT1
 SG_ ACU_ETC_SysCfg : 127|2@0+ (1,0) [0|3] ""  CCU,CCURT2
 SG_ ACU_ETC_ICMDisplayCfg : 125|2@0+ (1,0) [0|3] ""  CCU,CCURT2
 SG_ ACU_ETC_BLEenableCfg : 123|2@0+ (1,0) [0|3] ""  CCU,CCURT2
 SG_ ACU_VirtualPowerOFFReq : 31|1@0+ (1,0) [0|1] ""  CCU,CCURT2
 SG_ ACU_VirtualPowerOFFReqVd : 30|1@0+ (1,0) [0|1] ""  CCU,CCURT2
 SG_ ACU_VirtualPowerKeepReq : 29|2@0+ (1,0) [0|3] ""  CCU,CCURT2
 SG_ ACU_VirtualPowerKeepReqVd : 27|1@0+ (1,0) [0|1] ""  CCU,CCURT2
 SG_ ACU_WALCfg : 26|2@0+ (1,0) [0|3] ""  CCU,CCURT2
 SG_ ACU_SeatNapPopUpReq : 24|1@0+ (1,0) [0|1] ""  CCU,CCURT2
 SG_ ACU_APUCfg : 39|2@0+ (1,0) [0|3] ""  CCU,CCURT2
 SG_ ACU_SATOCfg : 37|2@0+ (1,0) [0|3] ""  CCU,CCURT2
 SG_ ACU_HVAC_AirCirCfg : 35|2@0+ (1,0) [0|3] ""  CCU,CCURT2
 SG_ ACU_HVAC_ComfortCfg : 33|2@0+ (1,0) [0|3] ""  CCU,CCURT2
 SG_ ACU_HVACF_AQSCfg : 47|2@0+ (1,0) [0|3] ""  CCU,CCURT2
 SG_ ACU_HVACF_FanspeedCfg : 45|2@0+ (1,0) [0|3] ""  CCU,CCURT2
 SG_ ACU_HVACF_EvapratorSelfCleanCfg : 43|2@0+ (1,0) [0|3] ""  CCU,CCURT2
 SG_ ACU_HVACF_UnlockVentilationCfg : 41|2@0+ (1,0) [0|3] ""  CCU,CCURT2
 SG_ ACU_HVACF_PM25CleanReqFb : 55|2@0+ (1,0) [0|3] ""  CCU,CCURT2
 SG_ ACU_MultiIDManageReq : 53|4@0+ (1,0) [0|15] ""  CCU,CCURT2
 SG_ ACU_HVAC_FraganceConcentrationSt : 64|3@0+ (1,0) [0|7] ""  CCU,CCURT2
 SG_ ACU_HVACFR_DrTempSetting : 77|6@0+ (0.5,18) [0|32] "degC"  CCU,CCURT2
 SG_ ACU_HVAC_FraganceTasteSt : 87|2@0+ (1,0) [0|3] ""  CCU,CCURT2
 SG_ ACU_WCM_SwitchStCfg : 85|2@0+ (1,0) [0|3] ""  CCU,CCURT2,ZCUR,WCM
 SG_ ACU_HVACFR_ModeSetting : 83|3@0+ (1,0) [0|7] ""  CCU,CCURT2
 SG_ ACU_HVAC_RearMODESetting : 80|3@0+ (1,0) [0|7] ""  CCU,CCURT2
 SG_ ACU_HVACFR_PsnTempSetting : 93|6@0+ (0.5,18) [0|32] "degC"  CCU,CCURT2
 SG_ ACU_HVACFR_RrTempSetting : 101|6@0+ (0.5,18) [0|32] "degC"  CCU,CCURT2
 SG_ ACU_HVACF_VR_HVACONOFF : 111|2@0+ (1,0) [0|3] ""  CCU,CCURT2
 SG_ ACU_HVAC_RearWindSpdSet : 109|4@0+ (1,0) [0|15] ""  CCU,CCURT2
 SG_ ACU_VehicleSearchHornCfg : 146|3@0+ (1,0) [0|7] ""  CCU,CCURT2,ZCUL
 SG_ ACU_MirrorAutoFoldFuncCfg : 159|2@0+ (1,0) [0|3] ""  CCU,CCURT2,ZCUL
 SG_ ACU_MirrorAngleDipFuncCfg : 157|3@0+ (1,0) [0|7] ""  CCU,CCURT2,ZCUL
 SG_ ACU_EasyEntryExitFuncCfg : 154|2@0+ (1,0) [0|3] ""  CCU,CCURT2,ZCUL
 SG_ ACU_ShortcutMode : 152|3@0+ (1,0) [0|7] ""  CCU,CCURT2,ZCUL
 SG_ ACU_SeatNapSettingSaveCmd : 173|2@0+ (1,0) [0|3] ""  CCU,CCURT2
 SG_ ACU_Account_Delete : 183|8@0+ (1,0) [0|255] ""  CCU,CCURT2
 SG_ ACU_FrontWiperIntCfgVkReq : 191|4@0+ (1,0) [0|15] ""  CCU,CCURT2
 SG_ ACU_FrontWiperAutoCfgVkReq : 187|4@0+ (1,0) [0|15] ""  CCU,CCURT2
 SG_ ACU_FrontWasherVRReq : 199|2@0+ (1,0) [0|3] ""  CCU,CCURT2
 SG_ ACU_FrontWasherVKReq : 197|2@0+ (1,0) [0|3] ""  CCU,CCURT2
 SG_ ACU_FrontWiperVKReq : 207|3@0+ (1,0) [0|7] ""  CCU,CCURT2
 SG_ ACU_FrontWiperVRReq : 204|3@0+ (1,0) [0|7] ""  CCU,CCURT2
 SG_ ACU_RearWiperVRReq : 201|2@0+ (1,0) [0|3] ""  CCU,CCURT2
 SG_ ACU_RearWasherVRReq : 215|2@0+ (1,0) [0|2] ""  CCU,CCURT2
 SG_ ACU_RWPServiceModeVKReq : 213|2@0+ (1,0) [0|2] ""  CCU,CCURT2
 SG_ ACU_RWPServiceModeVRReq : 211|2@0+ (1,0) [0|2] ""  CCU,CCURT2
 SG_ ACU_RearWasherVKReq : 209|2@0+ (1,0) [0|2] ""  CCU,CCURT2
 SG_ ACU_FWPServiceModeVKReq : 223|2@0+ (1,0) [0|2] ""  CCU,CCURT2
 SG_ ACU_FWPServiceModeVRReq : 221|2@0+ (1,0) [0|2] ""  CCU,CCURT2
 SG_ ACU_FrontAutoWiperEnableCfg : 219|2@0+ (1,0) [0|3] ""  CCU,CCURT2
 SG_ ACU_HeadLightLevelingVirtualSwSt : 231|4@0+ (1,0) [0|15] ""  CCU,CCURT2
 SG_ ACU_WelcomeLightMode : 227|4@0+ (1,0) [0|15] ""  CCU,CCURT2
 SG_ ACU_LightShowMode : 239|4@0+ (1,0) [0|15] ""  CCU,CCURT2
 SG_ ACU_LightShowFunCmd : 233|2@0+ (1,0) [0|3] ""  CCU,CCURT2
 SG_ ACU_LightShowTimeFlag : 247|8@0+ (1,0) [0|255] "s"  CCU,CCURT2
 SG_ ACU_FLSeatVentModeReq : 271|2@0+ (1,0) [0|3] ""  CCU,CCURT2
 SG_ ACU_FLSeatHeatLevelReq : 269|3@0+ (1,0) [0|7] ""  CCU,CCURT2
 SG_ ACU_FLSeatVentLevelReq : 266|3@0+ (1,0) [0|7] ""  CCU,CCURT2
 SG_ ACU_FRSeatHeatVentModeReq : 279|2@0+ (1,0) [0|3] ""  CCU,CCURT2
 SG_ ACU_FRSeatHeatLevelReq : 277|3@0+ (1,0) [0|7] ""  CCU,CCURT2
 SG_ ACU_FRSeatVentLevelReq : 274|3@0+ (1,0) [0|7] ""  CCU,CCURT2
 SG_ ACU_PosSaveRecallCmd : 287|2@0+ (1,0) [0|3] ""  CCU,CCURT2
 SG_ ACU_FLSeatAutoModeCfgReq : 285|3@0+ (1,0) [0|7] ""  CCU,CCURT2
 SG_ ACU_FRSeatAutoModeCfgReq : 282|3@0+ (1,0) [0|7] ""  CCU,CCURT2
 SG_ ACU_FoldUnfoldCtlReq : 295|2@0+ (1,0) [0|3] ""  CCU,CCURT2,ZCUL
 SG_ ACU_LockAutoWinCloseFunCfgReq : 293|3@0+ (1,0) [0|7] ""  CCU,CCURT2
 SG_ ACU_VRPLGOpenReq : 290|1@0+ (1,0) [0|1] ""  CCU,CCURT2
 SG_ ACU_VRPLGOpenReqVD : 289|1@0+ (1,0) [0|1] ""  CCU,CCURT2
 SG_ ACU_ClearSetPositionReq : 288|1@0+ (1,0) [0|1] ""  CCU,CCURT2
 SG_ ACU_PLGControlReq : 303|4@0+ (1,0) [0|15] ""  CCU,CCURT2
 SG_ ACU_VRPLGCloseReq : 299|1@0+ (1,0) [0|1] ""  CCU,CCURT2
 SG_ ACU_VRPLGCloseReqVD : 298|1@0+ (1,0) [0|1] ""  CCU,CCURT2
 SG_ ACU_ALSCfg : 297|2@0+ (1,0) [0|3] ""  CCU,CCURT2
 SG_ ACU_HeadLightDelayCfg : 307|2@0+ (1,0) [0|3] ""  CCU,CCURT2
 SG_ ACU_IALFunctionCfg : 305|2@0+ (1,0) [0|3] ""  CCU,CCURT2
 SG_ ACU_IALColorSetReq : 319|8@0+ (1,0) [0|255] ""  CCU,CCURT2
 SG_ ACU_IALBrightnessSetReq : 327|4@0+ (1,0) [0|15] ""  CCU,CCURT2
 SG_ ACU_IALDriverModeCfg : 323|2@0+ (1,0) [0|3] ""  CCU,CCURT2
 SG_ ACU_IALMusicModeCfg : 321|2@0+ (1,0) [0|3] ""  CCU,CCURT2
 SG_ ACU_IALVoiceModeCfg : 335|2@0+ (1,0) [0|3] ""  CCU,CCURT2
 SG_ ACU_AutoDomeLightCfg : 333|2@0+ (1,0) [0|3] ""  CCU,CCURT2
 SG_ ACU_HVAC_SolarFeaturesCfg : 331|2@0+ (1,0) [0|3] ""  CCU,CCURT2
 SG_ ACU_DoorLookHornCfg : 329|2@0+ (1,0) [0|3] ""  CCU,CCURT2
 SG_ ACU_FLSeatHeatModeReq : 341|2@0+ (1,0) [0|3] ""  CCU,CCURT2
 SG_ ACU_FRSeatVentModeReq : 339|2@0+ (1,0) [0|3] ""  CCU,CCURT2
 SG_ ACU_FRSeatHeatModeReq : 337|2@0+ (1,0) [0|3] ""  CCU,CCURT2
 SG_ ACU_HVACF_CirculationChangeReqFb : 415|2@0+ (1,0) [0|3] ""  CCU,CCURT2
 SG_ ACU_HVACFR_WindSpeedSetting : 413|7@0+ (1,0) [0|100] "%"  CCU,CCURT2
 SG_ ACU_HVACF_AutoDefCfg : 422|3@0+ (1,0) [0|7] ""  CCU,CCURT2
 SG_ ACU_HVACF_TimedVentilationCfg : 419|2@0+ (1,0) [0|3] ""  CCU,CCURT2
 SG_ ACU_SteeringHeatReq : 442|3@0+ (1,0) [0|7] ""  CCU,CCURT2
 SG_ ACU_PLGCtrl : 452|1@0+ (1,0) [0|1] ""  CCU,CCURT2
 SG_ ACU_PLGOpenReq : 451|1@0+ (1,0) [0|1] ""  CCU,CCURT2
 SG_ ACU_PLGOpenReqVD : 450|1@0+ (1,0) [0|1] ""  CCU,CCURT2
 SG_ ACU_PLGCloseReq : 449|1@0+ (1,0) [0|1] ""  CCU,CCURT2
 SG_ ACU_PLGCloseReqVD : 448|1@0+ (1,0) [0|1] ""  CCU,CCURT2
 SG_ ACU_PLGSetPstClearReq : 463|1@0+ (1,0) [0|1] ""  CCU,CCURT2
 SG_ ACU_PLGMaxPstReq : 462|1@0+ (1,0) [0|1] ""  CCU,CCURT2
 SG_ ACU_PLGTrunkReleaseReq : 461|1@0+ (1,0) [0|1] ""  CCU,CCURT2
 SG_ ACU_PLGFuncCfg : 460|2@0+ (1,0) [0|3] ""  CCU,CCURT2

BO_ 879 IDC_3: 64 IDC
 SG_ ACU_SteeringPrkgButton : 371|4@0+ (1,0) [0|15] ""  ADC,CCU
 SG_ ACU_VR_APAControl : 343|4@0+ (1,0) [0|15] ""  ADC,CCU
 SG_ ACU_DVR_Switch : 398|1@0+ (1,0) [0|1] ""  ADC,CCU
 SG_ ACU_PCS_SVM_MODCmd : 38|1@0+ (1,0) [0|1] ""  ADC,CCU
 SG_ IDC_3_Dummy11 : 31|8@0+ (1,0) [0|0] ""  ADC,CCU,CCURT2
 SG_ ACU_PAS_ButtonPress : 39|1@0+ (1,0) [0|1] ""  CCU,CCURT2
 SG_ ACU_ThemeType : 337|1@0+ (1,0) [0|1] ""  ADC,CCU
 SG_ IDC_3_Dummy10 : 463|56@0+ (1,0) [0|7.20575940379279E+016] ""  ADC,CCU,CCURT2
 SG_ IDC_3_Dummy9 : 407|48@0+ (1,0) [0|281474976710655] ""  ADC,CCU,CCURT2
 SG_ IDC_3_Dummy7 : 361|2@0+ (1,0) [0|0] ""  ADC,CCU,CCURT2
 SG_ IDC_3_Dummy6 : 336|1@0+ (1,0) [0|1] ""  ADC,CCU,CCURT2
 SG_ IDC_3_Dummy5 : 391|8@0+ (1,0) [0|255] ""  ADC,CCU,CCURT2
 SG_ IDC_3_Dummy4 : 198|59@0+ (1,0) [0|5.76460752303423E+017] ""  ADC,CCU,CCURT2
 SG_ IDC_3_Dummy3 : 153|35@0+ (1,0) [0|0] ""  ADC,CCU,CCURT2
 SG_ IDC_3_Dummy2 : 95|64@0+ (1,0) [0|0] ""  ADC,CCU,CCURT2
 SG_ IDC_3_Dummy1 : 37|54@0+ (1,0) [0|1.8014398509482E+016] ""  ADC,CCU,CCURT2
 SG_ IDC_3_Checksum : 7|16@0+ (1,0) [0|65535] ""  CCU,CCURT2
 SG_ IDC_3_RollingCounter : 23|8@0+ (1,0) [0|255] ""  CCU,CCURT2
 SG_ ACU_HeadLightVirtualSwSt : 159|3@0+ (1,0) [0|7] ""  CCU,CCURT2
 SG_ ACU_FrontFogLightVirtualSwSt : 156|1@0+ (1,0) [0|1] ""  CCU,CCURT2
 SG_ ACU_RearFogLightVirtualSwSt : 155|1@0+ (1,0) [0|1] ""  CCU,CCURT2
 SG_ ACU_HighBeamVirtualSwSt : 154|1@0+ (1,0) [0|1] ""  CCU,CCURT2
 SG_ ACU_Account_Uid : 251|4@0+ (1,0) [0|15] ""  CCU,CCURT2
 SG_ ACU_FCWWarnDistanceCfg : 263|2@0+ (1,0) [0|3] ""  CCU,ADC
 SG_ ACU_FCWCfg : 261|2@0+ (1,0) [0|3] ""  CCU,ADC
 SG_ ACU_AEBOff : 259|2@0+ (1,0) [0|3] ""  CCU,ADC
 SG_ ACU_LDW_LKACfg : 257|2@0+ (1,0) [0|3] "" Vector__XXX
 SG_ ACU_TSR_SwitchReq : 271|2@0+ (1,0) [0|3] ""  CCU,ADC
 SG_ ACU_IHBC_SwitchReq : 269|2@0+ (1,0) [0|3] ""  CCU,ADC
 SG_ ACU_LDS_TypeReq : 267|2@0+ (1,0) [0|3] ""  CCU,ADC
 SG_ ACU_BSDCfg : 265|2@0+ (1,0) [0|3] ""  CCU,ADC
 SG_ ACU_RCTACfg : 279|2@0+ (1,0) [0|3] ""  CCU,ADC
 SG_ ACU_DOWCfg : 277|2@0+ (1,0) [0|3] ""  CCU,ADC
 SG_ ACU_iACC_SwitchReq : 275|2@0+ (1,0) [0|3] ""  CCU,ADC
 SG_ ACU_TSR_AudioWarnReq : 273|2@0+ (1,0) [0|3] ""  CCU,ADC
 SG_ ACU_HWAHFCfg : 287|2@0+ (1,0) [0|3] ""  CCU,ADC
 SG_ ACU_HWAHF_AudioWarningTypeCfg : 285|2@0+ (1,0) [0|3] ""  CCU,ADC
 SG_ ACU_HWA_SwitchReq : 283|2@0+ (1,0) [0|3] ""  CCU,ADC
 SG_ ACU_ELKCfg : 281|2@0+ (1,0) [0|3] ""  CCU,ADC
 SG_ ACU_FCTACfg : 295|2@0+ (1,0) [0|3] ""  CCU,ADC
 SG_ ACU_RAWCfg : 293|2@0+ (1,0) [0|3] ""  CCU,ADC
 SG_ ACU_RCTA_TypeReqCfg : 291|2@0+ (1,0) [0|3] ""  CCU,ADC
 SG_ ACU_FCTA_TypeReqCfg : 289|2@0+ (1,0) [0|3] ""  CCU,ADC
 SG_ ACU_NDASwitchReq : 303|2@0+ (1,0) [0|3] ""  CCU,ADC
 SG_ ACU_NDALCConSwitchReq : 301|2@0+ (1,0) [0|3] ""  CCU,ADC
 SG_ ACU_NDALCStySwitchReq : 299|2@0+ (1,0) [0|3] ""  CCU,ADC
 SG_ ACU_ADASWarnTypeSwitch : 297|2@0+ (1,0) [0|3] ""  CCU,ADC
 SG_ ACU_ESACfg : 311|2@0+ (1,0) [0|3] ""  CCU,ADC
 SG_ ACU_ILCCfg : 309|2@0+ (1,0) [0|3] ""  CCU,ADC
 SG_ ACU_AESCfg : 307|2@0+ (1,0) [0|3] ""  CCU,ADC
 SG_ ACU_ILOACfg : 305|2@0+ (1,0) [0|3] ""  CCU,ADC
 SG_ ACU_iACC_StyleConfirmSwitchReq : 319|2@0+ (1,0) [0|3] ""  CCU,ADC
 SG_ ACU_IFC_SpeedLimit : 327|8@0+ (1,0) [0|255] "km/h"  CCU,ADC
 SG_ ACU_IFC_ISDRestOfdis : 335|8@0+ (1,0) [0|70] "km"  CCU,ADC
 SG_ ACU_IFC_OfframpDis : 455|8@0+ (100,0) [0|25500] "m"  CCU,ADC
 SG_ ACU_IFC_SpeedLimitUnit : 339|2@0+ (1,0) [0|3] ""  CCU,ADC
 SG_ ACU_IFC_SpeedLimtType : 351|4@0+ (1,0) [0|15] ""  CCU,ADC
 SG_ ACU_IFC_RoadType : 347|4@0+ (1,0) [0|15] ""  CCU,ADC
 SG_ ACU_IFC_ZoneCode : 359|3@0+ (1,0) [0|7] ""  CCU,ADC
 SG_ ACU_IFC_NaviSt : 356|2@0+ (1,0) [0|3] ""  CCU,ADC
 SG_ ACU_IFC_NaviCorp : 354|3@0+ (1,0) [0|7] ""  CCU,ADC
 SG_ ACU_IFC_NaviNewIconDis : 367|5@0+ (0.1,0) [0|2] "km"  CCU,ADC
 SG_ ACU_IFC_OfframpSt : 362|1@0+ (1,0) [0|1] ""  CCU,ADC
 SG_ ACU_IFC_NaviNewIcon : 375|4@0+ (1,0) [0|15] ""  CCU,ADC
 SG_ ACU_IFC_SLCAheadDis : 383|8@0+ (5,0) [0|1250] "m"  CCU,ADC
 SG_ ACU_ActiveNDAMessageSt : 317|3@0+ (1,0) [0|7] ""  CCU,ADC
 SG_ ACU_ActiveAVPMessageSt : 314|3@0+ (1,0) [0|7] ""  CCU,ADC
 SG_ ACU_LeftLaneChangeMessageSt : 397|3@0+ (1,0) [0|7] ""  CCU,ADC
 SG_ ACU_RigthLaneChangeMessageSt : 394|3@0+ (1,0) [0|7] ""  CCU,ADC
 SG_ ACU_ICANDAIconMessageSt : 399|1@0+ (1,0) [0|1] ""  CCU,ADC

CM_ BU_ IID "Display";
CM_ BO_ 3221225472 "This is a message for not used signals, created by Vector CANdb++ DBC OLE DB Provider.";
CM_ SG_ 3221225472 PAA_VideoSt "FAPA video status";
CM_ SG_ 165 ACU_RecpLevelCfg "Recuperation level";
CM_ SG_ 1045 ACU_NaviDestInformation "the information about navigation destination";
CM_ SG_ 1045 ACU_NaviViapoint_remainingSoc "Navigation via nearest charging station remaining SOC";
CM_ SG_ 1045 ACU_NaviViapointType "the information about navigation via  nearest charging station point";
CM_ SG_ 1045 ACU_NaviViapointtime "Navigation via nearest charging station point  time";
CM_ SG_ 1045 ACU_NaviViapointDistance "Navigation via nearest charging station point distance";
CM_ SG_ 1045 ACU_NaviDestTime "Navigation destination time";
CM_ SG_ 1045 ACU_NaviDestDistance "Navigation destination distance";
CM_ SG_ 742 SSW_RRMassageSt "Rear Right massage status";
CM_ SG_ 742 SSW_RRLumbarModeSt "Rear Right lumbar mode";
CM_ SG_ 742 SSW_RRSPAMode "Rear Right SPA Mode status";
CM_ SG_ 742 SSW_RRMassageModeSt "Rear Right massage mode";
CM_ SG_ 742 SSW_RRMassageForceSt "Rear Right massage intensity";
CM_ SG_ 742 SSW_RLMassageSt "Rear left massage status";
CM_ SG_ 742 SSW_RLLumbarModeSt "Rear left lumbar mode";
CM_ SG_ 742 SSW_RLSPAMode "Rear Left SPA Mode status";
CM_ SG_ 742 SSW_RLMassageModeSt "Rear left massage mode";
CM_ SG_ 742 SSW_RLMassageForceSt "Rear left massage intensity";
CM_ SG_ 948 SSW_FLMassageModeSt "Front left massage mode";
CM_ SG_ 948 SSW_FLMassageForceSt "Front left massage intensity";
CM_ SG_ 948 SSW_FLMassageSt "Front left Massage status";
CM_ SG_ 948 SSW_FLLumbarModeSt "Front left lumbar mode";
CM_ SG_ 948 SSW_FLSPAMode "Front Left SPA Mode status";
CM_ SG_ 850 SSW_RRSeatHeatSt "Rear Right Seat Heat State";
CM_ SG_ 850 SSW_RRSeatVentSt "Rear Right Seat Vent State";
CM_ SG_ 849 SSW_RLSeatHeatSt "Rear Left Seat HeatState";
CM_ SG_ 849 SSW_RLSeatVentSt "Rear Left Seat Vent State";
CM_ SG_ 653 VCU_ShootLaunchSt "State of shoot launch";
CM_ SG_ 653 VCU_BrkPedPst "Current brake pedal position";
CM_ SG_ 653 VCU_CrntGearLvl "VCU current carry out gear level";
CM_ SG_ 653 VCU_BrkPedPstVD "Current brake pedal position valid data";
CM_ SG_ 653 VCU_EMS_BrkPedalSt "Brake pedal status";
CM_ SG_ 653 VCU_EMS_AccPedalActPst "Current accelerate pedal actual position";
CM_ SG_ 1031 TEL_TelematicsModeActSt "Telematics Mode Active Status";
CM_ SG_ 1031 TEL_PhoneCallSt "The phone call status of Ecall or Bcall or CallBack mode";
CM_ SG_ 1031 TEL_PhoneNumber "The phone number of InComing Call ";
CM_ SG_ 1031 TEL_ResetFailReason "TBOx Reset Fail Reason";
CM_ SG_ 1031 TEL_ModuleResetSt "TBOx Module Reset Status";
CM_ SG_ 363 EPS_AssistRatio "feedback to IDC the assist ratio ";
CM_ SG_ 363 EPS_WarnLamp "Streering Warning Lamp";
CM_ SG_ 363 EPS_SteeringModeSt "EPS steering mode status";
CM_ SG_ 363 EPS_FunctionStyleSt "EPS function style state";
CM_ SG_ 363 EPS_SteeringAngleVD "indicate that Angle VD";
CM_ SG_ 363 EPS_SteeringAngle "steering wheel angle";
CM_ SG_ 363 EPS_1_CRC "E2E Profile 5 CRC";
CM_ SG_ 430 SRS_YawRate "Indicates vehicle yaw rate";
CM_ SG_ 430 SRS_VehLatrlAccel "Indicates vehicle lateral acceleration";
CM_ SG_ 430 SRS_VehLongAccel "Indicates vehicle longitudinal acceleration";
CM_ SG_ 430 SRS_NearCrashOutputSt "To inform there's near crash event happen in last 2sec. After 2 sec, the signal will turn to 0 ";
CM_ SG_ 430 SRS_RolloverCrashOutpuSt "Rollover  CrashOutput Status. To inform there's crash event happen in last 2 sec. After 2 sec, the signal will turn to 0.";
CM_ SG_ 430 SRS_Rear_CrashOutputSt "Rear  CrashOutput Status. To inform there's crash event happen in last 2 sec. After 2 sec, the signal will turn to 0.";
CM_ SG_ 430 SRS_RightSide_CrashOutputSt "Right Side  CrashOutput Status. To inform there's crash event happen in last 2 sec. After 2 sec, the signal will turn to 0.";
CM_ SG_ 430 SRS_LeftSide_CrashOutputSt "Left Side  CrashOutput Status. To inform there's crash event happen in last 2 sec. After 2 sec, the signal will turn to 0.";
CM_ SG_ 430 SRS_Front_CrashOutputSt "Front  CrashOutput Status. To inform there's crash event happen in last 2 sec. After 2 sec, the signal will turn to 0.";
CM_ SG_ 430 SRS_CrashOutputSt "To inform there's crash event happen in last 2sec.
After 2 sec, the signal will turn to 0
£¨crash here means any one of the 5 status defined
below£©";
CM_ SG_ 334 CSM_RC_NextStartTimeCDS "ÏÂÒ»´Î³äµç¿ªÊ¼Ê±¼ä_Ãë(µ¹¼ÆÊ±)";
CM_ SG_ 334 CSM_RC_NextStartTimeCDMi "ÏÂÒ»´Î³äµç¿ªÊ¼Ê±¼ä_·Ö(µ¹¼ÆÊ±)";
CM_ SG_ 334 CSM_RC_NextStartTimeCDH "ÏÂÒ»´Î³äµç¿ªÊ¼Ê±¼ä_Ê±(µ¹¼ÆÊ±)";
CM_ SG_ 334 CSM_RC_NextStartTimeCDD "ÏÂÒ»´Î³äµç¿ªÊ¼Ê±¼ä_ÈÕ(µ¹¼ÆÊ±)";
CM_ SG_ 334 CSM_RC_NextStartTimeS "ÏÂÒ»´Î³äµç¿ªÊ¼Ê±¼ä_Ãë";
CM_ SG_ 334 CSM_RC_NextStartTimeMi "ÏÂÒ»´Î³äµç¿ªÊ¼Ê±¼ä_·Ö";
CM_ SG_ 334 CSM_RC_NextStartTimeH "ÏÂÒ»´Î³äµç¿ªÊ¼Ê±¼ä_Ê±";
CM_ SG_ 334 CSM_RC_NextStartTimeD "ÏÂÒ»´Î³äµç¿ªÊ¼Ê±¼ä_ÈÕ ";
CM_ SG_ 334 CSM_RC_NextStartTimeMo "ÏÂÒ»´Î³äµç¿ªÊ¼Ê±¼ä_ÔÂ";
CM_ SG_ 334 CSM_RC_NextStartTimeY "ÏÂÒ»´Î³äµç¿ªÊ¼Ê±¼ä_Äê";
CM_ SG_ 348 CCU_SecSynMAC_Check "nan";
CM_ SG_ 348 CCU_SecSynResetCounter "nan";
CM_ SG_ 348 CCU_SecSynCounter "nan";
CM_ SG_ 944 BMC_LvPwrSysMsgOperationFlag "Operation flag for  BMC_LvPwrSysMsg";
CM_ SG_ 944 BMS_Err2NoticeFlag "Lever2 Error for BMS Popup flag";
CM_ SG_ 944 BMS_ErrNoticeOperationFlag "Operation flag for BMS error notice";
CM_ SG_ 944 BMS_ErrNotice "BMS error notice";
CM_ SG_ 944 BMC_3_CRC "Message checksum CRC in accordance with J1850";
CM_ SG_ 944 BMC_3_Counter "The MessageCounter is a 0 ~ 15 counter, increased of one unit on every message transmission";
CM_ SG_ 188 ACU_MediaPathSet "Media Path Set";
CM_ SG_ 188 ACU_NotificationDuckSet "NotificationDuckSet";
CM_ SG_ 188 ACU_RingtoneDuckSet "RingtoneDuckSet";
CM_ SG_ 188 ACU_BTCallDuckSet "BTCallDuckSet";
CM_ SG_ 188 ACU_ECallBCallDuckSet "ECallBCallDuckSet";
CM_ SG_ 188 ACU_VRDuckSet "VRDuckSet";
CM_ SG_ 188 ACU_NaviDuckSet "NaviDuckSet";
CM_ SG_ 188 ACU_AtmosphereMusicDuckSet "AtmosphereMusicDuckSet";
CM_ SG_ 188 ACU_MediaDuckSet "MediaDuckSet";
CM_ SG_ 188 ACU_FamilyCinemaSwitchSts "FamilyCinema Switch Status ";
CM_ SG_ 188 ACU_A2BSet "ACU_A2BSet";
CM_ SG_ 188 ACU_OutcarMediaSwitch "OutcarMediaSwitch";
CM_ SG_ 188 ACU_AVASSwitch "AVAS_Switch";
CM_ SG_ 188 ACU_GetIntVoltReq "Get internal working voltage of AMP";
CM_ SG_ 188 ACU_GetTempReq "Get internal temperature of AMP ";
CM_ SG_ 188 ACU_AVASMode "AVASMode";
CM_ SG_ 188 ACU_ESEType "ESE Type";
CM_ SG_ 188 ACU_ESESwitchSts "ESE Switch Status";
CM_ SG_ 188 ACU_ESEMode "ESE Mode";
CM_ SG_ 188 ACU_AdigoVirtualLiveSetReq "Adigo_VirtualLiveSet_Request";
CM_ SG_ 188 ACU_StrSurSet "Stereo or surround set. ";
CM_ SG_ 188 ACU_SeatsmodelSet "SeatsmodeSet";
CM_ SG_ 188 ACU_Headrest_Mode "Headrest_Mode";
CM_ SG_ 188 ACU_Cabin_ambiencemodeSet "Cabin_ambiencemodeSet";
CM_ SG_ 188 ACU_HeadrestCodriverVolumeSet "Headrest Co-driver Private Mode Volume Status";
CM_ SG_ 188 ACU_HeadrestDriverVolumeSet "Headrest Driver Private Mode Volume Status";
CM_ SG_ 188 ACU_Headrest_R_PrivateModeVolSet "HeadrestRight_Volume_Request";
CM_ SG_ 188 ACU_Headrest_Left_PrivateModeVol "HeadrestLeft_Volume_Request";
CM_ SG_ 188 ACU_OutcarFrontMediaVolSet "Outcar Front media Volume Set";
CM_ SG_ 188 ACU_OutcarFrontSPKVolSet "Outcar Front SPK Volume Set";
CM_ SG_ 188 ACU_Cabin_ambienceVolSet "Cabin_ambience volume adjustment";
CM_ SG_ 188 ACU_MainVolSet "Main volume adjustment";
CM_ SG_ 188 ACU_PhoneRingVolSet "PhoneRing volume adjustment";
CM_ SG_ 188 ACU_NaviVolSet "Navi volume adjustment";
CM_ SG_ 188 ACU_VRVolSet "VR/TTS(text to sound).";
CM_ SG_ 188 ACU_TelVolSet "HFM(hand free mode), RT(ring tone) and Tbox-I/B call volume set.";
CM_ SG_ 188 ACU_SpeakRR "RR speaker";
CM_ SG_ 188 ACU_SpeakRL "RL speaker";
CM_ SG_ 188 ACU_SpeakFR "FR speaker";
CM_ SG_ 188 ACU_SpeakFL "FL speaker";
CM_ SG_ 188 ACU_MuteSet "Mute all speakers";
CM_ SG_ 188 ACU_MuteRearSet "Mute rear speakers";
CM_ SG_ 188 ACU_VSCModeReq "Vehicle Speed Compensation mode(on/off) request.";
CM_ SG_ 188 ACU_HighFrqSet "High frequency audio set";
CM_ SG_ 188 ACU_MidFrqSet "Mid frequency audio set";
CM_ SG_ 188 ACU_LowFrqSet "Low frequency audio set";
CM_ SG_ 188 ACU_FaderSet "Front/rear audio fader set";
CM_ SG_ 188 ACU_BlcSet "Left/Right Audio Balance set";
CM_ SG_ 188 ACU_VRSourceSet "VR source set.";
CM_ SG_ 188 ACU_TelSourceSet "Telephone source set.";
CM_ SG_ 188 ACU_WarningSourceSet "Warningsource set.";
CM_ SG_ 188 ACU_MediaSourceSet "Media Source Set";
CM_ SG_ 188 ACU_SpeakMid "Mid speaker";
CM_ SG_ 188 ACU_NaviSourceSet "Navi source set.";
CM_ SG_ 188 ACU_BeepSourceSet "Beep source set.";
CM_ SG_ 767 AMP_MediaPathSt "Media Path State";
CM_ SG_ 767 AMP_NotificationDuckSet "NotificationDuckSet";
CM_ SG_ 767 AMP_RingtoneDuckSet "RingtoneDuckSet";
CM_ SG_ 767 AMP_BTCallDuckSet "BTCallDuckSet";
CM_ SG_ 767 AMP_ECallBCallDuckSet "ECallBCallDuckSet";
CM_ SG_ 767 AMP_VRDuckSet "VRDuckSet";
CM_ SG_ 767 AMP_NaviDuckSet "NaviDuckSet";
CM_ SG_ 767 AMP_AtmosphereMusicDuckSet "AtmosphereMusicDuckSet";
CM_ SG_ 767 AMP_MediaDuckSet "MediaDuckSet";
CM_ SG_ 767 AMP_FamilyCinemaSwitchSts "FamilyCinema Switch Status";
CM_ SG_ 767 AMP_GetHUTInfoSts "Get HUT Information.";
CM_ SG_ 767 AMP_HeadrestCodriverVolumeSt "Headrest Co-driver Private Mode Volume Status 0x00-0x64= Navi volume step 0-100 0x65-0xFE= Reserved 0xFF= No Command";
CM_ SG_ 873 DCDC_FaultLampIndOperationFlag "Operation flag for DCDCFaultLampInd";
CM_ SG_ 163 ACU_DPMessageSt "The State of DP Message";
CM_ SG_ 163 ACU_RAEBcfg "RAEB Configuration";
CM_ SG_ 163 ACU_ParkingBoxAngle "Angle of parking space frame";
CM_ SG_ 163 ACU_ParkingBoxMidX "X coordinate pixel value of  parking space frame handle";
CM_ SG_ 163 ACU_AVPMessageSt "The State of AVP Message";
CM_ SG_ 163 ACU_HPAMessageSt "The State of HPA Message";
CM_ SG_ 163 ACU_APAMessageSt "The State of APA Message";
CM_ SG_ 163 ACU_NDAVoicePromptTypeCfg "NDA Voice mode switch";
CM_ SG_ 163 ACU_LowPowerConfig "ACU_LowPowerMode Config";
CM_ SG_ 163 ACU_PCSModeSt "The mode of the host request panorama display";
CM_ SG_ 163 ACU_PCS_MirrorpagedownButtonST "Mirror Pagedown Button Status";
CM_ SG_ 163 ACU_PCS_ScreenCoordX "Screen touched in ER coordinate X";
CM_ SG_ 163 ACU_PCS_ScreenCoordY "Screen touched in ER coordinate Y";
CM_ SG_ 163 ACU_PCS_ScreenTouchSignal "ACU screen touch status";
CM_ SG_ 163 ACU_PCS_ER_QuitConfirm "Event record quit confirm ";
CM_ SG_ 163 ACU_PCS_ER_EnterCmd "Event record enter command";
CM_ SG_ 163 ACU_ER_FuncCfg "Event record funtion configuration";
CM_ SG_ 163 ACU_LanguageTypeSet "language type set";
CM_ SG_ 163 ACU_PCS_ScreenTouchSt "ACU screen touch status";
CM_ SG_ 163 ACU_SVM_Button "SVM button press status";
CM_ SG_ 163 ACU_PAAMode "The Mode of PAA which ACU request for";
CM_ BO_ 739 " Send Funtion Safety  signals";
CM_ SG_ 739 ICM_VehicleSpeed "Vehicle speed display for Functional Safety";
CM_ SG_ 739 ICM_FS_Enable "Functional Safety status";
CM_ SG_ 739 IDC_IID_1_CRC "E2E Profile 5 CRC";
CM_ SG_ 739 ICM_ADAS4Lamp "ADAS3 Lamp  status for fusa";
CM_ SG_ 739 ICM_ADAS3Lamp "ADAS3 Lamp status for fusa";
CM_ SG_ 739 ICM_ADAS2Lamp "ADAS2 Lamp status for fusa";
CM_ SG_ 739 ICM_ADAS1Lamp "ADAS1 Lamp  status for fusa";
CM_ SG_ 739 ICM_HandsOffLamp "Hands Off Lamp status for fusa";
CM_ SG_ 739 ICM_BrakeLamp "Brake Lamp status for fusa";
CM_ SG_ 739 ICM_EPBLamp "EPB Lamp status for fusa";
CM_ SG_ 739 ICM_PlugConnectLamp "Plug Connect Lamp status for fusa";
CM_ SG_ 739 ICM_DCDCFailLamp "DCDC Fail Lamp status for fusa";
CM_ SG_ 739 ICM_DynamicalsystemFailLamp "Dynamical system Fail Lamp status for fusa";
CM_ SG_ 739 ICM_SRSLamp "SRS Lamp status for fusa";
CM_ SG_ 739 ICM_EPSLamp "EPS Lamp status for fusa";
CM_ SG_ 739 ICM_EPBFailLamp "EPB Fail Lamp status for fusa";
CM_ SG_ 739 ICM_ESPOFFLamp "ESP OFF Lamp status for fusa";
CM_ SG_ 739 ICM_ESPLamp "ESP Lamp status for fusa";
CM_ SG_ 739 ICM_ABSLamp "ABS Lamp status for fusa
";
CM_ SG_ 739 DataLength "Data Length status";
CM_ SG_ 739 SID "SID status";
CM_ SG_ 739 ICM_GearInfo "Gear Info for fusa";
CM_ SG_ 739 ICM_Theme "ICM Theme status";
CM_ SG_ 739 IDC_IID_1_Counter "E2E Profile 5 Counter";
CM_ BO_ 918 "CCU_PADS_1(0x396)";
CM_ SG_ 918 UINM_PADS_VolRollerVD "Indicates PADS's VolRoller singal  validity";
CM_ SG_ 918 UINM_PADS_VolRollerSt "indicate PADS volume  roller rotating steps";
CM_ SG_ 918 UINM_PADS_VolRollerRotatedDir "indicate PADS volume  roller rotating direction";
CM_ SG_ 918 UINM_PADS_R_UpSWStVD "Indicates PADS_R_UpSWSt validity";
CM_ SG_ 918 UINM_PADS_R_UpSWSt "Indicates Right PADS's Up swtich state";
CM_ SG_ 918 UINM_PADS_R_UDRollerVD "Indicates Right PADS's Up-Down Roller singal validity ";
CM_ SG_ 918 UINM_PADS_R_UDRollerRSt "Indicates Right PADS's Up-Down Roller steps";
CM_ SG_ 918 UINM_PADS_R_UDRollerRotatedDir "Indicates Right PADS's Up-Down Roller direction";
CM_ SG_ 918 UINM_PADS_R_RightSWStVD "Indicates PADS_R_RightSWSt validity";
CM_ SG_ 918 UINM_PADS_R_RightSWSt "Indicates Right PADS's Right swtich state";
CM_ SG_ 918 UINM_PADS_R_LRRollerVD "Indicates Right PADS's Left-Right Roller singal validity";
CM_ SG_ 918 UINM_PADS_R_LRRollerRSt "Indicates Right PADS's Left-Right Roller steps";
CM_ SG_ 918 UINM_PADS_R_LRRollerRotatedDir "Indicates Right PADS's Left-Right Roller direction";
CM_ SG_ 918 UINM_PADS_R_LeftSWStVD "Indicates PADS_R_leftSWSt validity";
CM_ SG_ 918 UINM_PADS_R_leftSWSt "Indicates Right PADS's Left swtich state";
CM_ SG_ 918 UINM_PADS_R_DownSWStVD "Indicates PADS_R_DownSWSt validity";
CM_ SG_ 918 UINM_PADS_R_DownSWSt "Indicates Right PADS's Down swtich state";
CM_ SG_ 918 UINM_PADS_L_UpSWStVD "Indicates PADS_L_UpSWSt validity";
CM_ SG_ 918 UINM_PADS_L_UpSWSt "Indicates left PADS's Up swtich state";
CM_ SG_ 918 UINM_PADS_L_UDRollerRSt "Indicates left PADS's Up-Down Roller steps";
CM_ SG_ 918 UINM_PADS_L_UDRollerRotatedDir "Indicates left PADS's Up-Down Roller direction";
CM_ SG_ 918 UINM_PADS_L_RightSWStVD "Indicates PADS_L_RightSWSt validity";
CM_ SG_ 918 UINM_PADS_L_RightSWSt "Indicates left PADS's Right swtich state";
CM_ SG_ 918 UINM_PADS_L_LRRollerVD "Indicates left PADS's Left-Right Roller singal validity ";
CM_ SG_ 918 UINM_PADS_L_LRRollerRSt "Indicates left PADS's Left-Right Roller steps";
CM_ SG_ 918 UINM_PADS_L_LRRollerRotatedDir "Indicates left PADS's Left-Right Roller direction";
CM_ SG_ 918 UINM_PADS_L_LeftSWStVD "Indicates PADS_L_leftSWSt validity";
CM_ SG_ 918 UINM_PADS_L_leftSWSt "Indicates left PADS's Left swtich state";
CM_ SG_ 918 UINM_PADS_L_DownSWStVD "Indicates PADS_L_DownSWSt validity";
CM_ SG_ 918 UINM_PADS_L_DownSWSt "Indicates left PADS's Down swtich state";
CM_ SG_ 918 UINM_PADS_Custom2SWStVD "PADS_Custom2SWSt validity";
CM_ SG_ 918 UINM_PADS_Custom2SWSt "PADS Custom2  swtich state";
CM_ SG_ 918 UINM_PADS_CruSetSpeedRollerVD "Indicates PADS's CruSetSpeed singal  validity";
CM_ SG_ 918 UINM_PADS_Custom2SWStuckSt "PADS Custom2  swtich stuck state";
CM_ SG_ 918 UINM_PADS_CruSetSpeedRollerRotat "indicate PADS curise roller rotating direction";
CM_ SG_ 918 UINM_PADS_OKSWStuckSt "PADS OK swtich Stuck state";
CM_ SG_ 918 UINM_PADS_OKSWStVD "Indicates PADS_OKSWSt validity";
CM_ SG_ 918 UINM_PADS_OKSWSt "PADS OK swtich state";
CM_ SG_ 918 UINM_PADS_FolDistDecSWStuckSt " Indicates PADS's distance level decrease swtich
stuck state";
CM_ SG_ 918 UINM_PADS_FolDistDecSWStVD " Indicates PADS_FolDistDecSWSt validity";
CM_ SG_ 918 UINM_PADS_FolDistDecSWSt " PADS Following distance level decrease swtich
state";
CM_ SG_ 918 UINM_PADS_FolDistIncSWStuckSt "Indicates PADS's distance level increase swtich
stuck state";
CM_ SG_ 918 UINM_PADS_FolDistIncSWStVD "Indicates PADS_FolDistIncSWSt validity";
CM_ SG_ 918 UINM_PADS_FolDistIncSWSt "PADS Following distance level increase swtich
state";
CM_ SG_ 918 UINM_PADS_CruSetSpeedRollerSt "indicate PADS curise roller rotating steps";
CM_ SG_ 918 UINM_PADS_IDC_PlaySWStuckSt "Indicates PADS's Play swtich stuck state";
CM_ SG_ 918 UINM_PADS_IDC_PlaySWStVD "Indicates PADS_IDC_PlaySWSt validity";
CM_ SG_ 918 UINM_PADS_IDC_PlaySWSt "Indicates PADS Play swtich state";
CM_ SG_ 918 UINM_PADS_IDC_SkipDecSWStuckSt "PADS Skip decrease swtich stuck state";
CM_ SG_ 918 UINM_PADS_IDC_SkipDecSWStVD "Indicates PADS_IDC_SkipDecSWSt validity";
CM_ SG_ 918 UINM_PADS_IDC_SkipDecSWSt "Indicates PADS's SKIP decrease swtich state";
CM_ SG_ 918 UINM_PADS_IDC_SkipIncSWStuckSt " PADS Skip increase swtich stuck state";
CM_ SG_ 918 UINM_PADS_IDC_SkipIncSWStVD "Indicates PADS_IDC_SkipIncSWSt validity";
CM_ SG_ 918 UINM_PADS_IDC_SkipIncSWSt "Indicates PADS SKIP increase swtich state";
CM_ SG_ 918 UINM_PADS_CustomSWstuck "PADS Custom swtich stuck state";
CM_ SG_ 918 UINM_PADS_CustomSWStVD "PADS_CustomSWSt validity";
CM_ SG_ 918 UINM_PADS_CustomSWSt "PADS Custom swtich state";
CM_ SG_ 918 UINM_PADS_IDC_PhoneStuckSt "PADS Phone swtich stuck state";
CM_ SG_ 918 UINM_PADS_IDC_PhoneSWStVD "PADS_IDC_PhoneSWSt validity";
CM_ SG_ 918 UINM_PADS_IDC_PhoneSWSt "PADS Phone swtich state";
CM_ SG_ 918 UINM_PADS_IDC_VrSWStuckSt "PADS Voice Recognition swtich stuck state";
CM_ SG_ 918 UINM_PADS_IDC_VrSWStVD "PADS_IDC_VrSWSt validity";
CM_ SG_ 918 UINM_PADS_IDC_VrSWSt "PADS Voice Recognition swtich state";
CM_ SG_ 918 UINM_PADS_IDC_ViewSWStuckSt " PADS VIEW swtich stuck state";
CM_ SG_ 918 UINM_PADS_IDC_ViewSWVD "PADS_IDC_ViewSWSt validity";
CM_ SG_ 918 UINM_PADS_IDC_ViewSWSt "PADS VIEW swtich state";
CM_ SG_ 905 ICM_SoundWarnSilenceReq "ICM have some important sound warning,need ACU keep mute";
CM_ SG_ 905 ICM_DispTheme "Theme of ICM's current display";
CM_ SG_ 905 ICM_DisplayID "Main interface of ICM's current display";
CM_ SG_ 905 ICM_VehInsSpd_accurate "Vehicle instantaneous speed";
CM_ SG_ 905 ICM_VehRunningOdometer "Vehicle running odometer";
CM_ SG_ 905 ICM_VehRunningOdometerTemp "Vehicle running odometer Temp";
CM_ SG_ 905 ICM_VehRunningTimeTemp "Vehicle running time Temp";
CM_ SG_ 905 ICM_TotalAvaibleDriveDistance "The available driving distance according to the total";
CM_ SG_ 905 ICM_FuelAvaibleDriveDistance "The available driving distance according to the fuel";
CM_ SG_ 905 ICM_FuelLevelValue "The ramaining amount of fuel (L)";
CM_ SG_ 905 ICM_BackLightLevel_accurate "Back light level for 100";
CM_ SG_ 905 ICM_MFSButtonSt "The button's status of ICM operated by user";
CM_ SG_ 905 ICM_SetIACCSt "ICM set IACC status";
CM_ SG_ 905 ICM_VehicleBrakeSt "Indicate the vehicle brake status,ICM judge from the Hand brake status or the EPB brake status";
CM_ SG_ 905 ICM_AirbagLampFaultSt "Airbag warning lamp fault status";
CM_ SG_ 905 ICM_ChargingSt "Battery charging status";
CM_ SG_ 905 ICM_BackLightLevel "Back light level";
CM_ SG_ 905 ICM_TotalOdometer "Total odometer";
CM_ SG_ 905 ICM_VehAverageSpd "Vehicle average speed";
CM_ SG_ 905 ICM_BFLWarning "Brake fluid level low warning";
CM_ SG_ 905 ICM_TripAVD "ICM_TripA valid value";
CM_ SG_ 905 ICM_TripA "Trip odometer one";
CM_ SG_ 905 ICM_ElcConspAccumAvgClnCmd "Accumulated average electric consumption clean command";
CM_ SG_ 905 ICM_TripBVD "ICM_TripB valid value";
CM_ SG_ 905 ICM_TripB "Trip odometer second";
CM_ SG_ 905 ICM_VehInsSpd "Vehicle instantaneous speed";
CM_ SG_ 905 ICM_BattVolt "Battery voltage";
CM_ SG_ 905 ICM_BattVoltVD "Battery voltage valid data";
CM_ SG_ 905 ICM_DisFail "Error in the display";
CM_ SG_ 905 ICM_QDashACCFail "Error in the ACC message detected by the ICM, like timeout or alivecounter error. The error should distinguish reversible and irreversible errors.";
CM_ SG_ 905 ICM_TempUnitDisp "Unit of temperature display";
CM_ SG_ 905 ICM_PrUnitDisp "Unit of pressure display";
CM_ SG_ 905 ICM_TimeModeCfgSt "ICM time mode configuration status";
CM_ SG_ 905 ICM_VehRunningTime "Vehicle running time";
CM_ SG_ 905 ICM_SpdWarnCfgSt "Speed warning configuration status";
CM_ SG_ 905 ICM_LanguageCfgSt "ICM language configuration status";
CM_ SG_ 905 ICM_TotalOdometer_accurate "ODO value as accuracy of 0.1 km";
CM_ SG_ 905 ICM_WarnSoundVolCfgSt "Warning sound volume configuration status";
CM_ SG_ 905 IDC_ICM_1_FreshnessValue "nan";
CM_ SG_ 905 IDC_ICM_1_MAC_Check "nan";
CM_ SG_ 161 ACU_AccurHMIModeReq "Accurate range HMI mode display request";
CM_ SG_ 161 ACU_RecpLevelCfgL "Recuperation level configurationRecuperation level configuration";
CM_ SG_ 161 ACU_BrkPedalModsetting "Brake Pedal feeling Mode configuration status10x01~0x64:?1%~100%?Linear:-?resolution:?1%?per?bit-?offset:0?0x65~0x7E=Reserved";
CM_ SG_ 161 ACU_AccPdlLvlCfg "Acceleration Pedal Level selected by driver";
CM_ SG_ 161 ACU_AccurRngReq "Accurate range  request";
CM_ SG_ 161 ACU_EPSSteeringassistRatio "driver¡®s adjust assist ratio";
CM_ SG_ 161 ACU_IpedalCreepCfg "Creep function configuration when Ipedal on";
CM_ SG_ 161 ACU_DischgSt "State of Discharge button(on av/avnt) request";
CM_ SG_ 161 ACU_EpedalCfg "Epadel configuration";
CM_ SG_ 161 ACU_ESPST "set the ESP mode";
CM_ SG_ 161 ACU_WarmTimeCfg "Warm time configuration";
CM_ SG_ 161 ACU_DrvModCfg "Driving mode function configuration on AVNT screen";
CM_ SG_ 161 ACU_DischgSocCfg "Discharge SOC configuration";
CM_ SG_ 161 ACU_EcoPlusModeCfg "ECO+ mode configuration";
CM_ SG_ 161 ACU_LongDistCfg "Long Distance configuration";
CM_ SG_ 161 ACU_ChgSOCCfg "Charge SOC setting of HV battery to VCU";
CM_ SG_ 161 ACU_ChgPlugRelReq "Send to VCU from ACU to request to unlock charge outlet";
CM_ SG_ 161 ACU_EPBSwitchSt "Indication the EPBswitch status";
CM_ SG_ 161 ACU_DragModeReq "ACU Drag Mode Reqest Status";
CM_ SG_ 161 ACU_AVHSoftSwitchst "Indication the AVHSoftSwitch status";
CM_ SG_ 161 ACU_CST_OFFSwitch "nan";
CM_ SG_ 161 ACU_EPSStyleCfg "Configurates the style of EPS";
CM_ SG_ 161 ACU_EPSCoupleFunctionSt "nan";
CM_ SG_ 161 ACU_ESPFuncSwCfg "ESP function switch configuration";
CM_ SG_ 161 ACU_BrkPedalModeCfg "Brake Pedal feeling Mode configuration";
CM_ SG_ 161 IDC_DrvSwapModCfg "Swap function configuration when vcu request";
CM_ SG_ 161 ACU_ChgmodeReq "nan";
CM_ SG_ 161 ACU_TELInComingCallAnswerReq "IDC InComing Call Answer Request";
CM_ SG_ 161 ACU_TELCallHangUpReq "IDC Call HangUp Request";
CM_ SG_ 161 ACU_TELBcallReq "TEL Bcall request";
CM_ SG_ 161 ACU_TELEcallReq "TEL Ecall request";
CM_ SG_ 161 ACU_TelModuleResetReq "TBOx Module Reset Request";
CM_ SG_ 161 ACU_AuthRand "ACU Authentication Random Number";
CM_ SG_ 161 ACU_AuthKey "ACU Authentication Key";
CM_ SG_ 351 IDC_2_Counter "E2E Profile 5 Counter";
CM_ SG_ 351 IDC_2_CRC "E2E Profile 5 CRC";
CM_ SG_ 351 ACU_RLSeatHeatLevelReq "Rear Left Seat Heat Level Request";
CM_ SG_ 351 ACU_RRSeatHeatLevelReq "Rear Right Seat Heat Level Request";
CM_ SG_ 351 ACU_RRSeatVentLevelReq "Rear Right Seat Vent Level Request";
CM_ SG_ 351 ACU_RLSeatVentLevelReq "Rear Left Seat Vent Level Request";
CM_ SG_ 351 ACU_RRSeatAutoModeCfgReq "Rear Right Seat Auto Mode Configuration Request";
CM_ SG_ 351 ACU_RLSeatAutoModeCfgReq "Rear Left Seat Auto Mode Configuration Request";
CM_ SG_ 351 ACU_RearCamWasherVRReq "Rear Camera Washer Request";
CM_ SG_ 351 ACU_RearCamWasherVKReq "Rear Camera Washer Request";
CM_ SG_ 351 ACU_Account_Uld "Account_Uid";
CM_ SG_ 351 ACU_FRSeatSaveRecallReq "Front Right Seat Position Save and Recall Request";
CM_ SG_ 351 ACU_FRSeatSaveRecallPstReq "Front Right Seat Save Recall Request";
CM_ SG_ 351 ACU_FLLumbarReq "Front Left Lumbar request";
CM_ SG_ 351 ACU_HVACF_CO2LifeAlarmModeCfg "ACU HVACF CO Life Alarm Mode Configure";
CM_ SG_ 351 ACU_HVACFInCarAutoVentilationCfg "Configurates In Car AutoVentilation function";
CM_ SG_ 351 ACU_HVACF_CO2CleanReqFb "CO2 Clean Req Feedback from the ACU";
CM_ SG_ 351 ACU_EEM_LoadControl "Electrical Energy Management LoadControll";
CM_ SG_ 351 ACU_ETC_SysCfg "configurates ETC System Enable & Disable ";
CM_ SG_ 351 ACU_ETC_ICMDisplayCfg "configurates ETC infomation display on ICM function Enable & Disable";
CM_ SG_ 351 ACU_ETC_BLEenableCfg "configurates ETC Bluetooth function Enable & Disable ";
CM_ SG_ 351 ACU_VirtualPowerOFFReq "Virtual Power OFF Request";
CM_ SG_ 351 ACU_VirtualPowerOFFReqVd "Virtual Power OFF Request Valid Status";
CM_ SG_ 351 ACU_VirtualPowerKeepReq "Virtual Power Keep Request";
CM_ SG_ 351 ACU_VirtualPowerKeepReqVd "Virtual Power Keep Request Valid Status";
CM_ SG_ 351 ACU_WALCfg "WAL Configuration";
CM_ SG_ 351 ACU_SeatNapPopUpReq "Seat Nap Mode Pop-Up Request";
CM_ SG_ 351 ACU_APUCfg "APU Configuration";
CM_ SG_ 351 ACU_SATOCfg "SATO Configuration";
CM_ SG_ 351 ACU_HVAC_AirCirCfg "Configurates the air circulation control mode when HVACF  in auto mode";
CM_ SG_ 351 ACU_HVAC_ComfortCfg "Configurates HVACF Comfort curve";
CM_ SG_ 351 ACU_HVACF_AQSCfg "Configurates AQS(Air Quality Sensor) sensitivity";
CM_ SG_ 351 ACU_HVACF_FanspeedCfg "Configurates HVAC Fan speed of AUTO  mode";
CM_ SG_ 351 ACU_HVACF_EvapratorSelfCleanCfg "Configurates Evaprator Self Clean function";
CM_ SG_ 351 ACU_HVACF_UnlockVentilationCfg "Configurates Unlock Ventilation function";
CM_ SG_ 351 ACU_HVACF_PM25CleanReqFb "PM2.5 Clean Req Feedback from the ACU";
CM_ SG_ 351 ACU_MultiIDManageReq "Multi_ID management request";
CM_ SG_ 351 ACU_HVAC_FraganceConcentrationSt "Air Fragance Concentration";
CM_ SG_ 351 ACU_HVACFR_DrTempSetting "Turn to DrTemp xxx Celsius to HVAC";
CM_ SG_ 351 ACU_HVAC_FraganceTasteSt "Air Fragance Taste choose";
CM_ SG_ 351 ACU_WCM_SwitchStCfg "Configurates WCM switch status";
CM_ SG_ 351 ACU_HVACFR_ModeSetting "The wind exit mode setting";
CM_ SG_ 351 ACU_HVAC_RearMODESetting "The Rear wind exit mode setting";
CM_ SG_ 351 ACU_HVACFR_PsnTempSetting "Turn to PaTemp xxx Celsius to HVAC";
CM_ SG_ 351 ACU_HVACFR_RrTempSetting "Turn to RrTemp xxx Celsius to HVAC";
CM_ SG_ 351 ACU_HVACF_VR_HVACONOFF "Turn on or turn off HVAC by VR";
CM_ SG_ 351 ACU_HVAC_RearWindSpdSet "Setting Rear Wind Speed to HVAC";
CM_ SG_ 351 ACU_VehicleSearchHornCfg "Horn Beep Enable when vehicle search";
CM_ SG_ 351 ACU_MirrorAutoFoldFuncCfg "Mirror Auto Fold Function Configuration";
CM_ SG_ 351 ACU_MirrorAngleDipFuncCfg "Mirror Angle Dip Function Configuration";
CM_ SG_ 351 ACU_EasyEntryExitFuncCfg "Easy Entry-Exit Function Configuration";
CM_ SG_ 351 ACU_ShortcutMode "Shortcut Mode";
CM_ SG_ 351 ACU_SeatNapSettingSaveCmd "Seat Nap Mode Setting And Save Command";
CM_ SG_ 351 ACU_Account_Delete "Account Delete";
CM_ SG_ 351 ACU_FrontWiperIntCfgVkReq "Front wiper interval Softkey status";
CM_ SG_ 351 ACU_FrontWiperAutoCfgVkReq "Front wiper RLS  sensitivity status";
CM_ SG_ 351 ACU_FrontWasherVRReq "Front washer speech control command";
CM_ SG_ 351 ACU_FrontWasherVKReq "Front washer softkey status";
CM_ SG_ 351 ACU_FrontWiperVKReq "Front wiper softkey status";
CM_ SG_ 351 ACU_FrontWiperVRReq "Front wiper speech control command";
CM_ SG_ 351 ACU_RearWiperVRReq "Rear wiper speech control command";
CM_ SG_ 351 ACU_RearWasherVRReq "Rear washer speech control command";
CM_ SG_ 351 ACU_RWPServiceModeVKReq "Rear wiper service mode softkey command";
CM_ SG_ 351 ACU_RWPServiceModeVRReq "Rear wiper service mode speech control command";
CM_ SG_ 351 ACU_RearWasherVKReq "Rear washer softkey status";
CM_ SG_ 351 ACU_FWPServiceModeVKReq "Front wiper service mode  softkey command";
CM_ SG_ 351 ACU_FWPServiceModeVRReq "Front wiper service mode speech control command";
CM_ SG_ 351 ACU_FrontAutoWiperEnableCfg "Front Wiper Auto Enable Configuration";
CM_ SG_ 351 ACU_HeadLightLevelingVirtualSwSt "Head light leveling manul adjust virtual switch status";
CM_ SG_ 351 ACU_WelcomeLightMode "welcome light mode configuration";
CM_ SG_ 351 ACU_LightShowMode "light show mode ";
CM_ SG_ 351 ACU_LightShowFunCmd "Light show function command";
CM_ SG_ 351 ACU_LightShowTimeFlag "Light show synchronizing signal";
CM_ SG_ 351 ACU_FLSeatVentModeReq "Front Left Seat Ventilation Mode Request";
CM_ SG_ 351 ACU_FLSeatHeatLevelReq "Front Left Seat Heat Level Request";
CM_ SG_ 351 ACU_FLSeatVentLevelReq "Front Left Seat Ventilation Level Request";
CM_ SG_ 351 ACU_FRSeatHeatVentModeReq "Front Right Seat Heating-Ventilation Mode Request";
CM_ SG_ 351 ACU_FRSeatHeatLevelReq "Front Right Seat Heat Level Request";
CM_ SG_ 351 ACU_FRSeatVentLevelReq "Front Right Seat Ventilation Level Request";
CM_ SG_ 351 ACU_PosSaveRecallCmd "Position Save And Recall Command ";
CM_ SG_ 351 ACU_FLSeatAutoModeCfgReq "Front Left Seat Auto mode configuration request";
CM_ SG_ 351 ACU_FRSeatAutoModeCfgReq "Front Right Seat Auto mode configuration request";
CM_ SG_ 351 ACU_FoldUnfoldCtlReq "Mirror Fold Unfold Control Request";
CM_ SG_ 351 ACU_LockAutoWinCloseFunCfgReq "Lock Auto Window Close Function Configuration Request";
CM_ SG_ 351 ACU_VRPLGOpenReq "nan";
CM_ SG_ 351 ACU_VRPLGOpenReqVD "nan";
CM_ SG_ 351 ACU_ClearSetPositionReq "nan";
CM_ SG_ 351 ACU_PLGControlReq "nan";
CM_ SG_ 351 ACU_VRPLGCloseReq "nan";
CM_ SG_ 351 ACU_VRPLGCloseReqVD "nan";
CM_ SG_ 351 ACU_ALSCfg "Head light leveling auto adjust configuration";
CM_ SG_ 351 ACU_HeadLightDelayCfg "Head light delay configuration";
CM_ SG_ 351 ACU_IALFunctionCfg "IALFunctionConfiguration";
CM_ SG_ 351 ACU_IALColorSetReq "IALColorSetRequest";
CM_ SG_ 351 ACU_IALBrightnessSetReq "IALBrightnessSetRequest";
CM_ SG_ 351 ACU_IALDriverModeCfg "IALDriverModeConfiguration";
CM_ SG_ 351 ACU_IALMusicModeCfg "IALMusicModeConfiguration";
CM_ SG_ 351 ACU_IALVoiceModeCfg "IALVoiceModeConfiguration";
CM_ SG_ 351 ACU_AutoDomeLightCfg "AutoDomeLightConfiguration";
CM_ SG_ 351 ACU_HVAC_SolarFeaturesCfg "Solar features configuration";
CM_ SG_ 351 ACU_DoorLookHornCfg "Horn Beep Enable when DoorLock";
CM_ SG_ 351 ACU_FLSeatHeatModeReq "Front Left Seat Heating Mode Request";
CM_ SG_ 351 ACU_FRSeatVentModeReq "Front Right Seat Ventilation Mode Request";
CM_ SG_ 351 ACU_FRSeatHeatModeReq "Front Right Seat Heating Mode Request";
CM_ SG_ 351 ACU_HVACF_CirculationChangeReqFb "Circulation Change Request Feedback From ACU";
CM_ SG_ 351 ACU_HVACFR_WindSpeedSetting "Setting FrW ind Speed to HVAC";
CM_ SG_ 351 ACU_HVACF_AutoDefCfg "Configurates auto deforst status";
CM_ SG_ 351 ACU_HVACF_TimedVentilationCfg "ConfiguratesTimed Ventilation status";
CM_ SG_ 351 ACU_SteeringHeatReq "Steering Wheel Heat Request";
CM_ SG_ 351 ACU_PLGCtrl "Power lift gate position control";
CM_ SG_ 351 ACU_PLGOpenReq "PLG open request";
CM_ SG_ 351 ACU_PLGOpenReqVD "AVNT_PLGOpenReq valid value";
CM_ SG_ 351 ACU_PLGCloseReq "PLG close request";
CM_ SG_ 351 ACU_PLGCloseReqVD "AVNT_PLGCloseReq valid value";
CM_ SG_ 351 ACU_PLGSetPstClearReq "PLG set position clear requset(clear = set to 100%)";
CM_ SG_ 351 ACU_PLGMaxPstReq "Power lift gate Maximum position setting request";
CM_ SG_ 351 ACU_PLGTrunkReleaseReq "Power lift gate release request";
CM_ SG_ 351 ACU_PLGFuncCfg "Configurates power lift gate function";
CM_ SG_ 879 ACU_SteeringPrkgButton "Steering Parking Button";
CM_ SG_ 879 ACU_VR_APAControl "Parking voice wake up";
CM_ SG_ 879 ACU_DVR_Switch "DVR Function Switch";
CM_ SG_ 879 ACU_PCS_SVM_MODCmd "Panorama function setting option MOD function switch";
CM_ SG_ 879 ACU_PAS_ButtonPress "PAS button press state";
CM_ SG_ 879 ACU_ThemeType "AVNT theme type";
CM_ SG_ 879 IDC_3_Checksum "E2E Profile 5 CRC";
CM_ SG_ 879 IDC_3_RollingCounter "E2E Profile 5 Counter";
CM_ SG_ 879 ACU_HeadLightVirtualSwSt "HeadLight virtual switch status";
CM_ SG_ 879 ACU_FrontFogLightVirtualSwSt "Front fog light virtual switch status";
CM_ SG_ 879 ACU_RearFogLightVirtualSwSt "Rear fog light virtual switch status";
CM_ SG_ 879 ACU_HighBeamVirtualSwSt "High beam virtual switch status";
CM_ SG_ 879 ACU_Account_Uid "Account_Uid";
CM_ SG_ 879 ACU_FCWWarnDistanceCfg "Configurates FCW(Front Collision Warning) warning distance";
CM_ SG_ 879 ACU_FCWCfg "Configurates FCW (front collision warning assist)";
CM_ SG_ 879 ACU_AEBOff "AEB is turned off";
CM_ SG_ 879 ACU_LDW_LKACfg "Configurates LDW lane keeping assist";
CM_ SG_ 879 ACU_TSR_SwitchReq "TSR(Traffic Sign Recognition) switch signal";
CM_ SG_ 879 ACU_IHBC_SwitchReq "IHBC(Intelligent High Beam Control) switch signal";
CM_ SG_ 879 ACU_LDS_TypeReq "LDS lane aid type request";
CM_ SG_ 879 ACU_BSDCfg "Configurates BSD Switch Signal";
CM_ SG_ 879 ACU_RCTACfg "Configurates RCTA Switch Signal";
CM_ SG_ 879 ACU_DOWCfg "Configurates DOW Switch Signal";
CM_ SG_ 879 ACU_iACC_SwitchReq "iACC(TSR information fusion with ACC) switch signal";
CM_ SG_ 879 ACU_TSR_AudioWarnReq "TSR(Traffic Sign Recognition) audio warning on off signal";
CM_ SG_ 879 ACU_HWAHFCfg "HWAHF on/off request";
CM_ SG_ 879 ACU_HWAHF_AudioWarningTypeCfg "HWAHF audio warning type request";
CM_ SG_ 879 ACU_HWA_SwitchReq "HWA(High Way Assist)  on/off switch";
CM_ SG_ 879 ACU_ELKCfg "Configurates ELKA function";
CM_ SG_ 879 ACU_FCTACfg "Configurates FCTA function";
CM_ SG_ 879 ACU_RAWCfg "Configurates RAW function";
CM_ SG_ 879 ACU_RCTA_TypeReqCfg "RCTA assist type request";
CM_ SG_ 879 ACU_FCTA_TypeReqCfg "FCTA assist type request";
CM_ SG_ 879 ACU_NDASwitchReq "NDA main switch request";
CM_ SG_ 879 ACU_NDALCConSwitchReq "NDA lane change driver confirm switch request";
CM_ SG_ 879 ACU_NDALCStySwitchReq "NDA lane change style switch request";
CM_ SG_ 879 ACU_ADASWarnTypeSwitch "ADAS warning type switch signal";
CM_ SG_ 879 ACU_ESACfg "Configurates ESA function";
CM_ SG_ 879 ACU_ILCCfg "Configurates ILC function";
CM_ SG_ 879 ACU_AESCfg "Configurates AES function";
CM_ SG_ 879 ACU_ILOACfg "Configurates ILOA function";
CM_ SG_ 879 ACU_iACC_StyleConfirmSwitchReq "iACC Style confirm switch";
CM_ SG_ 879 ACU_IFC_SpeedLimit "Speed limit value from navigation map data and GPS location.";
CM_ SG_ 879 ACU_IFC_ISDRestOfdis "Interval speed detection rest of distacne. Once navigation jduge vehicle run in an interval speed detection area of road, this signal begin to send specific value, otherwise keep sending 0x0.";
CM_ SG_ 879 ACU_IFC_OfframpDis "The distance to front off-ramp ";
CM_ SG_ 879 ACU_IFC_SpeedLimitUnit "Speed limit unit ";
CM_ SG_ 879 ACU_IFC_SpeedLimtType "speed limit type from navigation map data and GPS location.";
CM_ SG_ 879 ACU_IFC_RoadType "Road type from navigation map data and GPS location.";
CM_ SG_ 879 ACU_IFC_ZoneCode "Zone code ";
CM_ SG_ 879 ACU_IFC_NaviSt "Navigation state ";
CM_ SG_ 879 ACU_IFC_NaviCorp "the working navigation map corporation ";
CM_ SG_ 879 ACU_IFC_NaviNewIconDis "the remain distances of navigation newIcon ";
CM_ SG_ 879 ACU_IFC_OfframpSt "The front is off-ramp or not when navigation";
CM_ SG_ 879 ACU_IFC_NaviNewIcon "indication the navigation newIcon ";
CM_ SG_ 879 ACU_IFC_SLCAheadDis "speed limit camera ahead distacne. Once navigation jduge there is a speed limit camera ahead that the vehicle will pass by, this signal begin to send specific value, otherwise keep sending 0x0.";
CM_ SG_ 879 ACU_ActiveNDAMessageSt "'recommend switch to NDA' card state";
CM_ SG_ 879 ACU_ActiveAVPMessageSt "'recommend switch to AVP' card state";
CM_ SG_ 879 ACU_LeftLaneChangeMessageSt "'recommed LeftLane Change' card state";
CM_ SG_ 879 ACU_RigthLaneChangeMessageSt "'recommed RighLane Change' card state";
CM_ SG_ 879 ACU_ICANDAIconMessageSt "driver click ICON button state";
BA_DEF_ BO_  "E2EProfile" STRING ;
BA_DEF_  "E2EP05WindowSize" INT 0 255;
BA_DEF_  "E2EP05ProfileName" STRING ;
BA_DEF_  "E2EP05MinOkStateValid" INT 0 255;
BA_DEF_  "E2EP05MinOkStateInValid" INT 0 255;
BA_DEF_  "E2EP05MinOkStateInit" INT 0 255;
BA_DEF_  "E2EP05MaxErrorStateValid" INT 0 255;
BA_DEF_  "E2EP05MaxErrorStateInValid" INT 0 255;
BA_DEF_  "E2EP05MaxErrorStateInit" INT 0 255;
BA_DEF_  "E2EP05MaxDeltaCounter" INT 0 255;
BA_DEF_ BO_  "E2EDataLength" INT 0 65535;
BA_DEF_ BO_  "E2EDataId" INT 0 65535;
BA_DEF_ SG_  "Remark" STRING ;
BA_DEF_ SG_  "EventCommandSignal" ENUM  "No","Yes";
BA_DEF_ SG_  "GatewayedSignals" ENUM  "No","Yes";
BA_DEF_ SG_  "GenSigTimeoutValue" HEX 0 0;
BA_DEF_ SG_  "GenSigStartValue" HEX 0 0;
BA_DEF_ SG_  "GenSigInvalidValue" HEX 0 0;
BA_DEF_ SG_  "GenSigInactiveValue" HEX 0 0;
BA_DEF_ SG_  "GenSigSendType" ENUM  "Trigger","Passive","Cyclic","OnWrite","OnWriteWithRepetition","OnChange","OnChangeWithRepetition","IfActive","IfActiveWithRepetition","NoSigSendType";
BA_DEF_ BO_  "GenMsgCycleTimeFast" INT 0 0;
BA_DEF_ BO_  "GenMsgCycleTime" INT 0 0;
BA_DEF_ BO_  "GenMsgSendType" ENUM  "Periodic","Event","IfActive","POE","PA","FixedPeriodic","Event","EnabledPeriodic","NotUsed","NotUsed","EventPeriodic","NotUsed","NotUsed","NoMsgSendType";
BA_DEF_ BO_  "VFrameFormat" ENUM  "StandardCAN","ExtendedCAN","reserved","reserved","reserved","reserved","reserved","reserved","reserved","reserved","reserved","reserved","reserved","reserved","StandardCAN_FD","ExtendedCAN_FD";
BA_DEF_ BO_  "CANFD_BRS" ENUM  "0","1";
BA_DEF_  "Manufacturer" STRING ;
BA_DEF_  "Project" STRING ;
BA_DEF_  "Version" STRING ;
BA_DEF_  "Date" STRING ;
BA_DEF_  "Author" STRING ;
BA_DEF_  "DBName" STRING ;
BA_DEF_  "BusType" STRING ;
BA_DEF_  "Checker" STRING ;
BA_DEF_  "Approver" STRING ;
BA_DEF_ SG_  "SystemSignalLongSymbol" STRING ;
BA_DEF_DEF_  "E2EProfile" "";
BA_DEF_DEF_  "E2EP05WindowSize" 3;
BA_DEF_DEF_  "E2EP05ProfileName" "PROFILE_05";
BA_DEF_DEF_  "E2EP05MinOkStateValid" 1;
BA_DEF_DEF_  "E2EP05MinOkStateInValid" 1;
BA_DEF_DEF_  "E2EP05MinOkStateInit" 1;
BA_DEF_DEF_  "E2EP05MaxErrorStateValid" 1;
BA_DEF_DEF_  "E2EP05MaxErrorStateInValid" 1;
BA_DEF_DEF_  "E2EP05MaxErrorStateInit" 1;
BA_DEF_DEF_  "E2EP05MaxDeltaCounter" 5;
BA_DEF_DEF_  "E2EDataLength" 0;
BA_DEF_DEF_  "E2EDataId" 0;
BA_DEF_DEF_  "Remark" "";
BA_DEF_DEF_  "EventCommandSignal" "";
BA_DEF_DEF_  "GatewayedSignals" "";
BA_DEF_DEF_  "GenSigTimeoutValue" 0;
BA_DEF_DEF_  "GenSigStartValue" 0;
BA_DEF_DEF_  "GenSigInvalidValue" 0;
BA_DEF_DEF_  "GenSigInactiveValue" 0;
BA_DEF_DEF_  "GenSigSendType" "";
BA_DEF_DEF_  "GenMsgCycleTimeFast" 0;
BA_DEF_DEF_  "GenMsgCycleTime" 0;
BA_DEF_DEF_  "GenMsgSendType" "";
BA_DEF_DEF_  "VFrameFormat" "";
BA_DEF_DEF_  "CANFD_BRS" "";
BA_DEF_DEF_  "Manufacturer" "";
BA_DEF_DEF_  "Project" "";
BA_DEF_DEF_  "Version" "";
BA_DEF_DEF_  "Date" "";
BA_DEF_DEF_  "Author" "";
BA_DEF_DEF_  "DBName" "";
BA_DEF_DEF_  "BusType" "";
BA_DEF_DEF_  "Checker" "";
BA_DEF_DEF_  "Approver" "";
BA_DEF_DEF_  "SystemSignalLongSymbol" "";
BA_ "BusType" "CAN FD";
BA_ "Approver" "Approver";
BA_ "Checker" "Checker";
BA_ "Author" "Author";
BA_ "Date" "2022-07-27";
BA_ "Version" "Version";
BA_ "Project" "Project";
BA_ "Manufacturer" "GAC R&D";
BA_ "DBName" "Network";
BA_ "CANFD_BRS" BO_ 165 1;
BA_ "GenMsgSendType" BO_ 165 1;
BA_ "VFrameFormat" BO_ 165 14;
BA_ "CANFD_BRS" BO_ 1045 1;
BA_ "GenMsgSendType" BO_ 1045 0;
BA_ "GenMsgCycleTime" BO_ 1045 1000;
BA_ "VFrameFormat" BO_ 1045 14;
BA_ "GenMsgCycleTime" BO_ 742 90;
BA_ "GenMsgSendType" BO_ 742 0;
BA_ "CANFD_BRS" BO_ 742 1;
BA_ "VFrameFormat" BO_ 742 14;
BA_ "GenMsgCycleTime" BO_ 948 90;
BA_ "GenMsgSendType" BO_ 948 0;
BA_ "CANFD_BRS" BO_ 948 1;
BA_ "VFrameFormat" BO_ 948 14;
BA_ "GenMsgCycleTime" BO_ 850 100;
BA_ "GenMsgSendType" BO_ 850 0;
BA_ "CANFD_BRS" BO_ 850 1;
BA_ "VFrameFormat" BO_ 850 14;
BA_ "GenMsgCycleTime" BO_ 849 100;
BA_ "GenMsgSendType" BO_ 849 0;
BA_ "CANFD_BRS" BO_ 849 1;
BA_ "VFrameFormat" BO_ 849 14;
BA_ "CANFD_BRS" BO_ 653 1;
BA_ "GenMsgSendType" BO_ 653 0;
BA_ "GenMsgCycleTime" BO_ 653 20;
BA_ "VFrameFormat" BO_ 653 14;
BA_ "GenMsgCycleTime" BO_ 1031 100;
BA_ "GenMsgSendType" BO_ 1031 0;
BA_ "CANFD_BRS" BO_ 1031 1;
BA_ "VFrameFormat" BO_ 1031 14;
BA_ "GenMsgSendType" BO_ 189 1;
BA_ "CANFD_BRS" BO_ 189 1;
BA_ "VFrameFormat" BO_ 189 14;
BA_ "E2EProfile" BO_ 363 "P05";
BA_ "E2EDataLength" BO_ 363 448;
BA_ "E2EDataId" BO_ 363 1029;
BA_ "CANFD_BRS" BO_ 363 1;
BA_ "GenMsgSendType" BO_ 363 0;
BA_ "GenMsgCycleTime" BO_ 363 100;
BA_ "VFrameFormat" BO_ 363 14;
BA_ "CANFD_BRS" BO_ 430 1;
BA_ "GenMsgSendType" BO_ 430 0;
BA_ "GenMsgCycleTime" BO_ 430 100;
BA_ "VFrameFormat" BO_ 430 14;
BA_ "CANFD_BRS" BO_ 334 1;
BA_ "GenMsgSendType" BO_ 334 3;
BA_ "GenMsgCycleTime" BO_ 334 500;
BA_ "GenMsgCycleTimeFast" BO_ 334 40;
BA_ "VFrameFormat" BO_ 334 14;
BA_ "GenMsgCycleTimeFast" BO_ 348 40;
BA_ "GenMsgCycleTime" BO_ 348 30000;
BA_ "GenMsgSendType" BO_ 348 3;
BA_ "CANFD_BRS" BO_ 348 1;
BA_ "VFrameFormat" BO_ 348 14;
BA_ "E2EProfile" BO_ 944 "P05";
BA_ "E2EDataLength" BO_ 944 448;
BA_ "E2EDataId" BO_ 944 818;
BA_ "GenMsgCycleTime" BO_ 944 200;
BA_ "GenMsgSendType" BO_ 944 0;
BA_ "CANFD_BRS" BO_ 944 1;
BA_ "VFrameFormat" BO_ 944 14;
BA_ "GenMsgSendType" BO_ 188 1;
BA_ "CANFD_BRS" BO_ 188 1;
BA_ "VFrameFormat" BO_ 188 14;
BA_ "GenMsgCycleTime" BO_ 767 50;
BA_ "GenMsgSendType" BO_ 767 0;
BA_ "CANFD_BRS" BO_ 767 1;
BA_ "VFrameFormat" BO_ 767 14;
BA_ "GenMsgCycleTime" BO_ 873 100;
BA_ "GenMsgSendType" BO_ 873 0;
BA_ "CANFD_BRS" BO_ 873 1;
BA_ "VFrameFormat" BO_ 873 14;
BA_ "GenMsgSendType" BO_ 163 1;
BA_ "CANFD_BRS" BO_ 163 1;
BA_ "VFrameFormat" BO_ 163 14;
BA_ "GenMsgCycleTime" BO_ 739 20;
BA_ "GenMsgSendType" BO_ 739 0;
BA_ "E2EDataLength" BO_ 739 512;
BA_ "E2EDataId" BO_ 739 1794;
BA_ "E2EProfile" BO_ 739 "P05";
BA_ "VFrameFormat" BO_ 739 14;
BA_ "CANFD_BRS" BO_ 918 1;
BA_ "GenMsgCycleTime" BO_ 918 60;
BA_ "GenMsgSendType" BO_ 918 0;
BA_ "VFrameFormat" BO_ 918 14;
BA_ "CANFD_BRS" BO_ 905 1;
BA_ "GenMsgCycleTime" BO_ 905 100;
BA_ "GenMsgSendType" BO_ 905 0;
BA_ "VFrameFormat" BO_ 905 14;
BA_ "CANFD_BRS" BO_ 161 1;
BA_ "GenMsgSendType" BO_ 161 1;
BA_ "VFrameFormat" BO_ 161 14;
BA_ "CANFD_BRS" BO_ 351 1;
BA_ "GenMsgCycleTime" BO_ 351 200;
BA_ "GenMsgCycleTimeFast" BO_ 351 40;
BA_ "GenMsgSendType" BO_ 351 3;
BA_ "E2EProfile" BO_ 351 "P05";
BA_ "E2EDataLength" BO_ 351 512;
BA_ "E2EDataId" BO_ 351 1798;
BA_ "VFrameFormat" BO_ 351 14;
BA_ "E2EProfile" BO_ 879 "P05";
BA_ "E2EDataLength" BO_ 879 512;
BA_ "E2EDataId" BO_ 879 1796;
BA_ "CANFD_BRS" BO_ 879 1;
BA_ "GenMsgCycleTime" BO_ 879 50;
BA_ "GenMsgSendType" BO_ 879 0;
BA_ "VFrameFormat" BO_ 879 14;
BA_ "GenSigSendType" SG_ 165 ACU_RecpLevelCfg 0;
BA_ "GatewayedSignals" SG_ 165 ACU_RecpLevelCfg 0;
BA_ "EventCommandSignal" SG_ 165 ACU_RecpLevelCfg 1;
BA_ "GenSigSendType" SG_ 1045 ACU_NaviDestInformation 1;
BA_ "GatewayedSignals" SG_ 1045 ACU_NaviDestInformation 0;
BA_ "EventCommandSignal" SG_ 1045 ACU_NaviDestInformation 0;
BA_ "GenSigSendType" SG_ 1045 ACU_NaviViapoint_remainingSoc 1;
BA_ "GatewayedSignals" SG_ 1045 ACU_NaviViapoint_remainingSoc 0;
BA_ "EventCommandSignal" SG_ 1045 ACU_NaviViapoint_remainingSoc 0;
BA_ "Remark" SG_ 1045 ACU_NaviViapoint_remainingSoc "ÐÅºÅÖµÀ´Ô´´ýÈ·ÈÏ";
BA_ "GenSigSendType" SG_ 1045 ACU_NaviViapointType 1;
BA_ "GatewayedSignals" SG_ 1045 ACU_NaviViapointType 0;
BA_ "EventCommandSignal" SG_ 1045 ACU_NaviViapointType 0;
BA_ "GenSigSendType" SG_ 1045 ACU_NaviViapointtime 1;
BA_ "GatewayedSignals" SG_ 1045 ACU_NaviViapointtime 0;
BA_ "EventCommandSignal" SG_ 1045 ACU_NaviViapointtime 0;
BA_ "GenSigSendType" SG_ 1045 ACU_NaviViapointDistance 1;
BA_ "GatewayedSignals" SG_ 1045 ACU_NaviViapointDistance 0;
BA_ "EventCommandSignal" SG_ 1045 ACU_NaviViapointDistance 0;
BA_ "GenSigSendType" SG_ 1045 ACU_NaviDestTime 1;
BA_ "GatewayedSignals" SG_ 1045 ACU_NaviDestTime 0;
BA_ "EventCommandSignal" SG_ 1045 ACU_NaviDestTime 0;
BA_ "GenSigSendType" SG_ 1045 ACU_NaviDestDistance 1;
BA_ "GatewayedSignals" SG_ 1045 ACU_NaviDestDistance 0;
BA_ "EventCommandSignal" SG_ 1045 ACU_NaviDestDistance 0;
BA_ "EventCommandSignal" SG_ 742 SSW_RRMassageSt 0;
BA_ "GatewayedSignals" SG_ 742 SSW_RRMassageSt 0;
BA_ "GenSigSendType" SG_ 742 SSW_RRMassageSt 1;
BA_ "EventCommandSignal" SG_ 742 SSW_RRLumbarModeSt 0;
BA_ "GatewayedSignals" SG_ 742 SSW_RRLumbarModeSt 0;
BA_ "GenSigSendType" SG_ 742 SSW_RRLumbarModeSt 1;
BA_ "EventCommandSignal" SG_ 742 SSW_RRSPAMode 0;
BA_ "GatewayedSignals" SG_ 742 SSW_RRSPAMode 0;
BA_ "GenSigSendType" SG_ 742 SSW_RRSPAMode 1;
BA_ "EventCommandSignal" SG_ 742 SSW_RRMassageModeSt 0;
BA_ "GatewayedSignals" SG_ 742 SSW_RRMassageModeSt 0;
BA_ "GenSigSendType" SG_ 742 SSW_RRMassageModeSt 1;
BA_ "EventCommandSignal" SG_ 742 SSW_RRMassageForceSt 0;
BA_ "GatewayedSignals" SG_ 742 SSW_RRMassageForceSt 0;
BA_ "GenSigSendType" SG_ 742 SSW_RRMassageForceSt 1;
BA_ "EventCommandSignal" SG_ 742 SSW_RLMassageSt 0;
BA_ "GatewayedSignals" SG_ 742 SSW_RLMassageSt 0;
BA_ "GenSigSendType" SG_ 742 SSW_RLMassageSt 1;
BA_ "EventCommandSignal" SG_ 742 SSW_RLLumbarModeSt 0;
BA_ "GatewayedSignals" SG_ 742 SSW_RLLumbarModeSt 0;
BA_ "GenSigSendType" SG_ 742 SSW_RLLumbarModeSt 1;
BA_ "EventCommandSignal" SG_ 742 SSW_RLSPAMode 0;
BA_ "GatewayedSignals" SG_ 742 SSW_RLSPAMode 0;
BA_ "GenSigSendType" SG_ 742 SSW_RLSPAMode 1;
BA_ "EventCommandSignal" SG_ 742 SSW_RLMassageModeSt 0;
BA_ "GatewayedSignals" SG_ 742 SSW_RLMassageModeSt 0;
BA_ "GenSigSendType" SG_ 742 SSW_RLMassageModeSt 1;
BA_ "EventCommandSignal" SG_ 742 SSW_RLMassageForceSt 0;
BA_ "GatewayedSignals" SG_ 742 SSW_RLMassageForceSt 0;
BA_ "GenSigSendType" SG_ 742 SSW_RLMassageForceSt 1;
BA_ "EventCommandSignal" SG_ 948 SSW_FLMassageModeSt 0;
BA_ "GatewayedSignals" SG_ 948 SSW_FLMassageModeSt 0;
BA_ "GenSigSendType" SG_ 948 SSW_FLMassageModeSt 1;
BA_ "EventCommandSignal" SG_ 948 SSW_FLMassageForceSt 0;
BA_ "GatewayedSignals" SG_ 948 SSW_FLMassageForceSt 0;
BA_ "GenSigSendType" SG_ 948 SSW_FLMassageForceSt 1;
BA_ "EventCommandSignal" SG_ 948 SSW_FLMassageSt 0;
BA_ "GatewayedSignals" SG_ 948 SSW_FLMassageSt 0;
BA_ "GenSigSendType" SG_ 948 SSW_FLMassageSt 1;
BA_ "EventCommandSignal" SG_ 948 SSW_FLLumbarModeSt 0;
BA_ "GatewayedSignals" SG_ 948 SSW_FLLumbarModeSt 0;
BA_ "GenSigSendType" SG_ 948 SSW_FLLumbarModeSt 1;
BA_ "EventCommandSignal" SG_ 948 SSW_FLSPAMode 0;
BA_ "GatewayedSignals" SG_ 948 SSW_FLSPAMode 0;
BA_ "GenSigSendType" SG_ 948 SSW_FLSPAMode 1;
BA_ "Remark" SG_ 850 SSW_RRSeatHeatSt "A19";
BA_ "EventCommandSignal" SG_ 850 SSW_RRSeatHeatSt 0;
BA_ "GatewayedSignals" SG_ 850 SSW_RRSeatHeatSt 0;
BA_ "GenSigSendType" SG_ 850 SSW_RRSeatHeatSt 1;
BA_ "Remark" SG_ 850 SSW_RRSeatVentSt "A19";
BA_ "EventCommandSignal" SG_ 850 SSW_RRSeatVentSt 0;
BA_ "GatewayedSignals" SG_ 850 SSW_RRSeatVentSt 0;
BA_ "GenSigSendType" SG_ 850 SSW_RRSeatVentSt 1;
BA_ "Remark" SG_ 849 SSW_RLSeatHeatSt "A19";
BA_ "EventCommandSignal" SG_ 849 SSW_RLSeatHeatSt 0;
BA_ "GatewayedSignals" SG_ 849 SSW_RLSeatHeatSt 0;
BA_ "GenSigSendType" SG_ 849 SSW_RLSeatHeatSt 1;
BA_ "Remark" SG_ 849 SSW_RLSeatVentSt "A19";
BA_ "EventCommandSignal" SG_ 849 SSW_RLSeatVentSt 0;
BA_ "GatewayedSignals" SG_ 849 SSW_RLSeatVentSt 0;
BA_ "GenSigSendType" SG_ 849 SSW_RLSeatVentSt 1;
BA_ "GenSigSendType" SG_ 653 VCU_ShootLaunchSt 1;
BA_ "GatewayedSignals" SG_ 653 VCU_ShootLaunchSt 0;
BA_ "EventCommandSignal" SG_ 653 VCU_ShootLaunchSt 0;
BA_ "Remark" SG_ 653 VCU_ShootLaunchSt "<E2E_Group1>

[E2E_Trigger]";
BA_ "GenSigSendType" SG_ 653 VCU_BrkPedPst 1;
BA_ "GatewayedSignals" SG_ 653 VCU_BrkPedPst 0;
BA_ "EventCommandSignal" SG_ 653 VCU_BrkPedPst 0;
BA_ "Remark" SG_ 653 VCU_BrkPedPst "<E2E_Group1>

[E2E_Trigger]";
BA_ "GenSigSendType" SG_ 653 VCU_CrntGearLvl 1;
BA_ "GatewayedSignals" SG_ 653 VCU_CrntGearLvl 0;
BA_ "EventCommandSignal" SG_ 653 VCU_CrntGearLvl 0;
BA_ "Remark" SG_ 653 VCU_CrntGearLvl "<E2E_Group1>

[E2E_Trigger]";
BA_ "GenSigSendType" SG_ 653 VCU_BrkPedPstVD 1;
BA_ "GatewayedSignals" SG_ 653 VCU_BrkPedPstVD 0;
BA_ "EventCommandSignal" SG_ 653 VCU_BrkPedPstVD 0;
BA_ "Remark" SG_ 653 VCU_BrkPedPstVD "<E2E_Group1>

[E2E_Trigger]";
BA_ "GenSigSendType" SG_ 653 VCU_EMS_BrkPedalSt 1;
BA_ "GatewayedSignals" SG_ 653 VCU_EMS_BrkPedalSt 0;
BA_ "EventCommandSignal" SG_ 653 VCU_EMS_BrkPedalSt 0;
BA_ "Remark" SG_ 653 VCU_EMS_BrkPedalSt "<E2E_Group1>

[E2E_Trigger]";
BA_ "GenSigSendType" SG_ 653 VCU_EMS_AccPedalActPst 1;
BA_ "GatewayedSignals" SG_ 653 VCU_EMS_AccPedalActPst 0;
BA_ "EventCommandSignal" SG_ 653 VCU_EMS_AccPedalActPst 0;
BA_ "Remark" SG_ 653 VCU_EMS_AccPedalActPst "<E2E_Group1>

[E2E_Trigger]";
BA_ "EventCommandSignal" SG_ 189 AMP_GetAmpMcuVerInfo 0;
BA_ "GenSigSendType" SG_ 189 AMP_GetAmpMcuVerInfo 1;
BA_ "EventCommandSignal" SG_ 189 AMP_GetAmpDspVerInfo 0;
BA_ "GenSigSendType" SG_ 189 AMP_GetAmpDspVerInfo 1;
BA_ "EventCommandSignal" SG_ 189 AMP_GetAmpHwVerInfo 0;
BA_ "GenSigSendType" SG_ 189 AMP_GetAmpHwVerInfo 1;
BA_ "EventCommandSignal" SG_ 189 AMP_GetAmpCfgInfo 0;
BA_ "GenSigSendType" SG_ 189 AMP_GetAmpCfgInfo 1;
BA_ "EventCommandSignal" SG_ 430 SRS_YawRate 0;
BA_ "GatewayedSignals" SG_ 430 SRS_YawRate 0;
BA_ "GenSigTimeoutValue" SG_ 430 SRS_YawRate 18000;
BA_ "GenSigStartValue" SG_ 430 SRS_YawRate 18000;
BA_ "GenSigSendType" SG_ 430 SRS_YawRate 1;
BA_ "EventCommandSignal" SG_ 430 SRS_VehLatrlAccel 0;
BA_ "GatewayedSignals" SG_ 430 SRS_VehLatrlAccel 0;
BA_ "GenSigTimeoutValue" SG_ 430 SRS_VehLatrlAccel 2000;
BA_ "GenSigStartValue" SG_ 430 SRS_VehLatrlAccel 2000;
BA_ "GenSigSendType" SG_ 430 SRS_VehLatrlAccel 1;
BA_ "EventCommandSignal" SG_ 430 SRS_VehLongAccel 0;
BA_ "GatewayedSignals" SG_ 430 SRS_VehLongAccel 0;
BA_ "GenSigTimeoutValue" SG_ 430 SRS_VehLongAccel 2000;
BA_ "GenSigStartValue" SG_ 430 SRS_VehLongAccel 2000;
BA_ "GenSigSendType" SG_ 430 SRS_VehLongAccel 1;
BA_ "GenSigSendType" SG_ 334 CSM_RC_NextStartTimeCDS 1;
BA_ "GatewayedSignals" SG_ 334 CSM_RC_NextStartTimeCDS 0;
BA_ "EventCommandSignal" SG_ 334 CSM_RC_NextStartTimeCDS 0;
BA_ "GenSigSendType" SG_ 334 CSM_RC_NextStartTimeCDMi 1;
BA_ "GatewayedSignals" SG_ 334 CSM_RC_NextStartTimeCDMi 0;
BA_ "EventCommandSignal" SG_ 334 CSM_RC_NextStartTimeCDMi 0;
BA_ "GenSigSendType" SG_ 334 CSM_RC_NextStartTimeCDH 1;
BA_ "GatewayedSignals" SG_ 334 CSM_RC_NextStartTimeCDH 0;
BA_ "EventCommandSignal" SG_ 334 CSM_RC_NextStartTimeCDH 0;
BA_ "GenSigSendType" SG_ 334 CSM_RC_NextStartTimeCDD 1;
BA_ "GatewayedSignals" SG_ 334 CSM_RC_NextStartTimeCDD 0;
BA_ "EventCommandSignal" SG_ 334 CSM_RC_NextStartTimeCDD 0;
BA_ "GenSigSendType" SG_ 334 CSM_RC_NextStartTimeS 1;
BA_ "EventCommandSignal" SG_ 334 CSM_RC_NextStartTimeS 1;
BA_ "GenSigSendType" SG_ 334 CSM_RC_NextStartTimeMi 0;
BA_ "EventCommandSignal" SG_ 334 CSM_RC_NextStartTimeMi 1;
BA_ "GenSigSendType" SG_ 334 CSM_RC_NextStartTimeH 0;
BA_ "EventCommandSignal" SG_ 334 CSM_RC_NextStartTimeH 1;
BA_ "GenSigSendType" SG_ 334 CSM_RC_NextStartTimeD 0;
BA_ "EventCommandSignal" SG_ 334 CSM_RC_NextStartTimeD 1;
BA_ "GenSigSendType" SG_ 334 CSM_RC_NextStartTimeMo 0;
BA_ "EventCommandSignal" SG_ 334 CSM_RC_NextStartTimeMo 1;
BA_ "GenSigSendType" SG_ 334 CSM_RC_NextStartTimeY 0;
BA_ "GenSigStartValue" SG_ 334 CSM_RC_NextStartTimeY -2020;
BA_ "EventCommandSignal" SG_ 334 CSM_RC_NextStartTimeY 1;
BA_ "EventCommandSignal" SG_ 348 CCU_SecSynMAC_Check 1;
BA_ "GenSigSendType" SG_ 348 CCU_SecSynMAC_Check 0;
BA_ "EventCommandSignal" SG_ 348 CCU_SecSynResetCounter 1;
BA_ "GenSigSendType" SG_ 348 CCU_SecSynResetCounter 0;
BA_ "EventCommandSignal" SG_ 348 CCU_SecSynCounter 1;
BA_ "GenSigSendType" SG_ 348 CCU_SecSynCounter 0;
BA_ "EventCommandSignal" SG_ 944 BMC_LvPwrSysMsgOperationFlag 0;
BA_ "GatewayedSignals" SG_ 944 BMC_LvPwrSysMsgOperationFlag 1;
BA_ "GenSigSendType" SG_ 944 BMC_LvPwrSysMsgOperationFlag 1;
BA_ "EventCommandSignal" SG_ 944 BMS_Err2NoticeFlag 0;
BA_ "GatewayedSignals" SG_ 944 BMS_Err2NoticeFlag 1;
BA_ "GenSigSendType" SG_ 944 BMS_Err2NoticeFlag 1;
BA_ "EventCommandSignal" SG_ 944 BMS_ErrNoticeOperationFlag 0;
BA_ "GatewayedSignals" SG_ 944 BMS_ErrNoticeOperationFlag 1;
BA_ "GenSigSendType" SG_ 944 BMS_ErrNoticeOperationFlag 1;
BA_ "EventCommandSignal" SG_ 944 BMS_ErrNotice 0;
BA_ "GatewayedSignals" SG_ 944 BMS_ErrNotice 1;
BA_ "GenSigSendType" SG_ 944 BMS_ErrNotice 1;
BA_ "EventCommandSignal" SG_ 944 BMC_3_CRC 0;
BA_ "GatewayedSignals" SG_ 944 BMC_3_CRC 1;
BA_ "GenSigSendType" SG_ 944 BMC_3_CRC 1;
BA_ "EventCommandSignal" SG_ 944 BMC_3_Counter 0;
BA_ "GatewayedSignals" SG_ 944 BMC_3_Counter 1;
BA_ "GenSigSendType" SG_ 944 BMC_3_Counter 1;
BA_ "GenSigSendType" SG_ 188 ACU_MediaPathSet 0;
BA_ "GenSigStartValue" SG_ 188 ACU_MediaPathSet 7;
BA_ "GatewayedSignals" SG_ 188 ACU_MediaPathSet 0;
BA_ "EventCommandSignal" SG_ 188 ACU_MediaPathSet 1;
BA_ "GenSigSendType" SG_ 188 ACU_NotificationDuckSet 0;
BA_ "GatewayedSignals" SG_ 188 ACU_NotificationDuckSet 0;
BA_ "EventCommandSignal" SG_ 188 ACU_NotificationDuckSet 1;
BA_ "GenSigSendType" SG_ 188 ACU_RingtoneDuckSet 0;
BA_ "GatewayedSignals" SG_ 188 ACU_RingtoneDuckSet 0;
BA_ "EventCommandSignal" SG_ 188 ACU_RingtoneDuckSet 1;
BA_ "GenSigSendType" SG_ 188 ACU_BTCallDuckSet 0;
BA_ "GatewayedSignals" SG_ 188 ACU_BTCallDuckSet 0;
BA_ "EventCommandSignal" SG_ 188 ACU_BTCallDuckSet 1;
BA_ "GenSigSendType" SG_ 188 ACU_ECallBCallDuckSet 0;
BA_ "GatewayedSignals" SG_ 188 ACU_ECallBCallDuckSet 0;
BA_ "EventCommandSignal" SG_ 188 ACU_ECallBCallDuckSet 1;
BA_ "GenSigSendType" SG_ 188 ACU_VRDuckSet 0;
BA_ "GatewayedSignals" SG_ 188 ACU_VRDuckSet 0;
BA_ "EventCommandSignal" SG_ 188 ACU_VRDuckSet 1;
BA_ "GenSigSendType" SG_ 188 ACU_NaviDuckSet 0;
BA_ "GatewayedSignals" SG_ 188 ACU_NaviDuckSet 0;
BA_ "EventCommandSignal" SG_ 188 ACU_NaviDuckSet 1;
BA_ "GenSigSendType" SG_ 188 ACU_AtmosphereMusicDuckSet 0;
BA_ "GatewayedSignals" SG_ 188 ACU_AtmosphereMusicDuckSet 0;
BA_ "EventCommandSignal" SG_ 188 ACU_AtmosphereMusicDuckSet 1;
BA_ "GenSigSendType" SG_ 188 ACU_MediaDuckSet 0;
BA_ "GatewayedSignals" SG_ 188 ACU_MediaDuckSet 0;
BA_ "EventCommandSignal" SG_ 188 ACU_MediaDuckSet 1;
BA_ "GenSigSendType" SG_ 188 ACU_FamilyCinemaSwitchSts 0;
BA_ "GenSigStartValue" SG_ 188 ACU_FamilyCinemaSwitchSts 3;
BA_ "EventCommandSignal" SG_ 188 ACU_FamilyCinemaSwitchSts 1;
BA_ "GenSigSendType" SG_ 188 ACU_A2BSet 0;
BA_ "GenSigStartValue" SG_ 188 ACU_A2BSet 3;
BA_ "EventCommandSignal" SG_ 188 ACU_A2BSet 1;
BA_ "GenSigSendType" SG_ 188 ACU_OutcarMediaSwitch 0;
BA_ "GenSigStartValue" SG_ 188 ACU_OutcarMediaSwitch 3;
BA_ "EventCommandSignal" SG_ 188 ACU_OutcarMediaSwitch 1;
BA_ "GenSigSendType" SG_ 188 ACU_AVASSwitch 0;
BA_ "GenSigStartValue" SG_ 188 ACU_AVASSwitch 3;
BA_ "EventCommandSignal" SG_ 188 ACU_AVASSwitch 1;
BA_ "GenSigSendType" SG_ 188 ACU_GetIntVoltReq 0;
BA_ "GenSigStartValue" SG_ 188 ACU_GetIntVoltReq 3;
BA_ "EventCommandSignal" SG_ 188 ACU_GetIntVoltReq 1;
BA_ "GenSigSendType" SG_ 188 ACU_GetTempReq 0;
BA_ "GenSigStartValue" SG_ 188 ACU_GetTempReq 3;
BA_ "EventCommandSignal" SG_ 188 ACU_GetTempReq 1;
BA_ "GenSigSendType" SG_ 188 ACU_AVASMode 0;
BA_ "GenSigStartValue" SG_ 188 ACU_AVASMode 7;
BA_ "EventCommandSignal" SG_ 188 ACU_AVASMode 1;
BA_ "GenSigSendType" SG_ 188 ACU_ESEType 0;
BA_ "GenSigStartValue" SG_ 188 ACU_ESEType 7;
BA_ "EventCommandSignal" SG_ 188 ACU_ESEType 1;
BA_ "GenSigSendType" SG_ 188 ACU_ESESwitchSts 0;
BA_ "GenSigStartValue" SG_ 188 ACU_ESESwitchSts 3;
BA_ "EventCommandSignal" SG_ 188 ACU_ESESwitchSts 1;
BA_ "GenSigSendType" SG_ 188 ACU_ESEMode 0;
BA_ "GenSigStartValue" SG_ 188 ACU_ESEMode 7;
BA_ "EventCommandSignal" SG_ 188 ACU_ESEMode 1;
BA_ "GenSigSendType" SG_ 188 ACU_AdigoVirtualLiveSetReq 0;
BA_ "GenSigStartValue" SG_ 188 ACU_AdigoVirtualLiveSetReq 15;
BA_ "EventCommandSignal" SG_ 188 ACU_AdigoVirtualLiveSetReq 1;
BA_ "GenSigSendType" SG_ 188 ACU_StrSurSet 0;
BA_ "GenSigStartValue" SG_ 188 ACU_StrSurSet 15;
BA_ "EventCommandSignal" SG_ 188 ACU_StrSurSet 1;
BA_ "GenSigSendType" SG_ 188 ACU_SeatsmodelSet 0;
BA_ "GenSigStartValue" SG_ 188 ACU_SeatsmodelSet 7;
BA_ "EventCommandSignal" SG_ 188 ACU_SeatsmodelSet 1;
BA_ "GenSigSendType" SG_ 188 ACU_Headrest_Mode 0;
BA_ "GenSigStartValue" SG_ 188 ACU_Headrest_Mode 3;
BA_ "EventCommandSignal" SG_ 188 ACU_Headrest_Mode 1;
BA_ "GenSigSendType" SG_ 188 ACU_Cabin_ambiencemodeSet 0;
BA_ "GenSigStartValue" SG_ 188 ACU_Cabin_ambiencemodeSet 7;
BA_ "EventCommandSignal" SG_ 188 ACU_Cabin_ambiencemodeSet 1;
BA_ "GenSigSendType" SG_ 188 ACU_HeadrestCodriverVolumeSet 0;
BA_ "GenSigStartValue" SG_ 188 ACU_HeadrestCodriverVolumeSet 255;
BA_ "EventCommandSignal" SG_ 188 ACU_HeadrestCodriverVolumeSet 1;
BA_ "GenSigSendType" SG_ 188 ACU_HeadrestDriverVolumeSet 0;
BA_ "GenSigStartValue" SG_ 188 ACU_HeadrestDriverVolumeSet 255;
BA_ "EventCommandSignal" SG_ 188 ACU_HeadrestDriverVolumeSet 1;
BA_ "GenSigSendType" SG_ 188 ACU_Headrest_R_PrivateModeVolSet 0;
BA_ "GenSigStartValue" SG_ 188 ACU_Headrest_R_PrivateModeVolSet 255;
BA_ "EventCommandSignal" SG_ 188 ACU_Headrest_R_PrivateModeVolSet 1;
BA_ "GenSigSendType" SG_ 188 ACU_Headrest_Left_PrivateModeVol 0;
BA_ "GenSigStartValue" SG_ 188 ACU_Headrest_Left_PrivateModeVol 255;
BA_ "EventCommandSignal" SG_ 188 ACU_Headrest_Left_PrivateModeVol 1;
BA_ "SystemSignalLongSymbol" SG_ 188 ACU_Headrest_Left_PrivateModeVol "ACU_Headrest_Left_PrivateModeVolumeSet";
BA_ "GenSigSendType" SG_ 188 ACU_OutcarFrontMediaVolSet 0;
BA_ "GenSigStartValue" SG_ 188 ACU_OutcarFrontMediaVolSet 255;
BA_ "EventCommandSignal" SG_ 188 ACU_OutcarFrontMediaVolSet 1;
BA_ "GenSigSendType" SG_ 188 ACU_OutcarFrontSPKVolSet 0;
BA_ "GenSigStartValue" SG_ 188 ACU_OutcarFrontSPKVolSet 255;
BA_ "EventCommandSignal" SG_ 188 ACU_OutcarFrontSPKVolSet 1;
BA_ "GenSigSendType" SG_ 188 ACU_Cabin_ambienceVolSet 0;
BA_ "GenSigStartValue" SG_ 188 ACU_Cabin_ambienceVolSet 255;
BA_ "EventCommandSignal" SG_ 188 ACU_Cabin_ambienceVolSet 1;
BA_ "GenSigSendType" SG_ 188 ACU_MainVolSet 0;
BA_ "GenSigStartValue" SG_ 188 ACU_MainVolSet 255;
BA_ "EventCommandSignal" SG_ 188 ACU_MainVolSet 1;
BA_ "GenSigSendType" SG_ 188 ACU_PhoneRingVolSet 0;
BA_ "GenSigStartValue" SG_ 188 ACU_PhoneRingVolSet 255;
BA_ "EventCommandSignal" SG_ 188 ACU_PhoneRingVolSet 1;
BA_ "GenSigSendType" SG_ 188 ACU_NaviVolSet 0;
BA_ "GenSigStartValue" SG_ 188 ACU_NaviVolSet 255;
BA_ "EventCommandSignal" SG_ 188 ACU_NaviVolSet 1;
BA_ "GenSigSendType" SG_ 188 ACU_VRVolSet 0;
BA_ "GenSigStartValue" SG_ 188 ACU_VRVolSet 255;
BA_ "EventCommandSignal" SG_ 188 ACU_VRVolSet 1;
BA_ "GenSigSendType" SG_ 188 ACU_TelVolSet 0;
BA_ "GenSigStartValue" SG_ 188 ACU_TelVolSet 255;
BA_ "EventCommandSignal" SG_ 188 ACU_TelVolSet 1;
BA_ "GenSigSendType" SG_ 188 ACU_SpeakRR 0;
BA_ "GenSigStartValue" SG_ 188 ACU_SpeakRR 3;
BA_ "EventCommandSignal" SG_ 188 ACU_SpeakRR 1;
BA_ "GenSigSendType" SG_ 188 ACU_SpeakRL 0;
BA_ "GenSigStartValue" SG_ 188 ACU_SpeakRL 3;
BA_ "EventCommandSignal" SG_ 188 ACU_SpeakRL 1;
BA_ "GenSigSendType" SG_ 188 ACU_SpeakFR 0;
BA_ "GenSigStartValue" SG_ 188 ACU_SpeakFR 3;
BA_ "EventCommandSignal" SG_ 188 ACU_SpeakFR 1;
BA_ "GenSigSendType" SG_ 188 ACU_SpeakFL 0;
BA_ "GenSigStartValue" SG_ 188 ACU_SpeakFL 3;
BA_ "EventCommandSignal" SG_ 188 ACU_SpeakFL 1;
BA_ "GenSigSendType" SG_ 188 ACU_MuteSet 0;
BA_ "GenSigStartValue" SG_ 188 ACU_MuteSet 3;
BA_ "EventCommandSignal" SG_ 188 ACU_MuteSet 1;
BA_ "GenSigSendType" SG_ 188 ACU_MuteRearSet 0;
BA_ "GenSigStartValue" SG_ 188 ACU_MuteRearSet 3;
BA_ "EventCommandSignal" SG_ 188 ACU_MuteRearSet 1;
BA_ "GenSigSendType" SG_ 188 ACU_VSCModeReq 0;
BA_ "GenSigStartValue" SG_ 188 ACU_VSCModeReq 7;
BA_ "EventCommandSignal" SG_ 188 ACU_VSCModeReq 1;
BA_ "GenSigSendType" SG_ 188 ACU_HighFrqSet 0;
BA_ "GenSigStartValue" SG_ 188 ACU_HighFrqSet 31;
BA_ "EventCommandSignal" SG_ 188 ACU_HighFrqSet 1;
BA_ "GenSigSendType" SG_ 188 ACU_MidFrqSet 0;
BA_ "GenSigStartValue" SG_ 188 ACU_MidFrqSet 31;
BA_ "EventCommandSignal" SG_ 188 ACU_MidFrqSet 1;
BA_ "GenSigSendType" SG_ 188 ACU_LowFrqSet 0;
BA_ "GenSigStartValue" SG_ 188 ACU_LowFrqSet 31;
BA_ "EventCommandSignal" SG_ 188 ACU_LowFrqSet 1;
BA_ "GenSigSendType" SG_ 188 ACU_FaderSet 0;
BA_ "GenSigStartValue" SG_ 188 ACU_FaderSet 31;
BA_ "EventCommandSignal" SG_ 188 ACU_FaderSet 1;
BA_ "GenSigSendType" SG_ 188 ACU_BlcSet 0;
BA_ "GenSigStartValue" SG_ 188 ACU_BlcSet 31;
BA_ "EventCommandSignal" SG_ 188 ACU_BlcSet 1;
BA_ "GenSigSendType" SG_ 188 ACU_VRSourceSet 0;
BA_ "GenSigStartValue" SG_ 188 ACU_VRSourceSet 7;
BA_ "EventCommandSignal" SG_ 188 ACU_VRSourceSet 1;
BA_ "GenSigSendType" SG_ 188 ACU_TelSourceSet 0;
BA_ "GenSigStartValue" SG_ 188 ACU_TelSourceSet 7;
BA_ "EventCommandSignal" SG_ 188 ACU_TelSourceSet 1;
BA_ "GenSigSendType" SG_ 188 ACU_WarningSourceSet 0;
BA_ "GenSigStartValue" SG_ 188 ACU_WarningSourceSet 15;
BA_ "EventCommandSignal" SG_ 188 ACU_WarningSourceSet 1;
BA_ "EventCommandSignal" SG_ 188 ACU_MediaSourceSet 1;
BA_ "GenSigStartValue" SG_ 188 ACU_MediaSourceSet 15;
BA_ "GenSigSendType" SG_ 188 ACU_MediaSourceSet 0;
BA_ "EventCommandSignal" SG_ 188 ACU_SpeakMid 1;
BA_ "GenSigStartValue" SG_ 188 ACU_SpeakMid 3;
BA_ "GenSigSendType" SG_ 188 ACU_SpeakMid 0;
BA_ "EventCommandSignal" SG_ 188 ACU_NaviSourceSet 1;
BA_ "GenSigStartValue" SG_ 188 ACU_NaviSourceSet 7;
BA_ "GenSigSendType" SG_ 188 ACU_NaviSourceSet 0;
BA_ "EventCommandSignal" SG_ 188 ACU_BeepSourceSet 1;
BA_ "GenSigStartValue" SG_ 188 ACU_BeepSourceSet 7;
BA_ "GenSigSendType" SG_ 188 ACU_BeepSourceSet 0;
BA_ "GenSigSendType" SG_ 767 AMP_MediaPathSt 1;
BA_ "GenSigStartValue" SG_ 767 AMP_MediaPathSt 7;
BA_ "GatewayedSignals" SG_ 767 AMP_MediaPathSt 0;
BA_ "EventCommandSignal" SG_ 767 AMP_MediaPathSt 0;
BA_ "GenSigSendType" SG_ 767 AMP_NotificationDuckSet 0;
BA_ "GatewayedSignals" SG_ 767 AMP_NotificationDuckSet 0;
BA_ "EventCommandSignal" SG_ 767 AMP_NotificationDuckSet 1;
BA_ "GenSigSendType" SG_ 767 AMP_RingtoneDuckSet 0;
BA_ "GatewayedSignals" SG_ 767 AMP_RingtoneDuckSet 0;
BA_ "EventCommandSignal" SG_ 767 AMP_RingtoneDuckSet 1;
BA_ "GenSigSendType" SG_ 767 AMP_BTCallDuckSet 0;
BA_ "GatewayedSignals" SG_ 767 AMP_BTCallDuckSet 0;
BA_ "EventCommandSignal" SG_ 767 AMP_BTCallDuckSet 1;
BA_ "GenSigSendType" SG_ 767 AMP_ECallBCallDuckSet 0;
BA_ "GatewayedSignals" SG_ 767 AMP_ECallBCallDuckSet 0;
BA_ "EventCommandSignal" SG_ 767 AMP_ECallBCallDuckSet 1;
BA_ "GenSigSendType" SG_ 767 AMP_VRDuckSet 0;
BA_ "GatewayedSignals" SG_ 767 AMP_VRDuckSet 0;
BA_ "EventCommandSignal" SG_ 767 AMP_VRDuckSet 1;
BA_ "GenSigSendType" SG_ 767 AMP_NaviDuckSet 0;
BA_ "GatewayedSignals" SG_ 767 AMP_NaviDuckSet 0;
BA_ "EventCommandSignal" SG_ 767 AMP_NaviDuckSet 1;
BA_ "GenSigSendType" SG_ 767 AMP_AtmosphereMusicDuckSet 0;
BA_ "GatewayedSignals" SG_ 767 AMP_AtmosphereMusicDuckSet 0;
BA_ "EventCommandSignal" SG_ 767 AMP_AtmosphereMusicDuckSet 1;
BA_ "GenSigSendType" SG_ 767 AMP_MediaDuckSet 0;
BA_ "GatewayedSignals" SG_ 767 AMP_MediaDuckSet 0;
BA_ "EventCommandSignal" SG_ 767 AMP_MediaDuckSet 1;
BA_ "EventCommandSignal" SG_ 767 AMP_BeepSourceSts 0;
BA_ "GenSigSendType" SG_ 767 AMP_BeepSourceSts 1;
BA_ "EventCommandSignal" SG_ 767 AMP_NaviSourceSt 0;
BA_ "GenSigSendType" SG_ 767 AMP_NaviSourceSt 1;
BA_ "EventCommandSignal" SG_ 767 AMP_SpeakMid 0;
BA_ "GenSigSendType" SG_ 767 AMP_SpeakMid 1;
BA_ "EventCommandSignal" SG_ 767 AMP_MediaSourceSt 0;
BA_ "GenSigSendType" SG_ 767 AMP_MediaSourceSt 1;
BA_ "EventCommandSignal" SG_ 767 AMP_WarningSourceSts 0;
BA_ "GenSigSendType" SG_ 767 AMP_WarningSourceSts 1;
BA_ "EventCommandSignal" SG_ 767 AMP_TelSourceSts 0;
BA_ "GenSigSendType" SG_ 767 AMP_TelSourceSts 1;
BA_ "EventCommandSignal" SG_ 767 AMP_VRSourceSts 0;
BA_ "GenSigSendType" SG_ 767 AMP_VRSourceSts 1;
BA_ "EventCommandSignal" SG_ 767 AMP_BlcSetSt 0;
BA_ "GenSigSendType" SG_ 767 AMP_BlcSetSt 1;
BA_ "EventCommandSignal" SG_ 767 AMP_FadeSetSt 0;
BA_ "GenSigSendType" SG_ 767 AMP_FadeSetSt 1;
BA_ "EventCommandSignal" SG_ 767 AMP_LowFrqSet 0;
BA_ "GenSigSendType" SG_ 767 AMP_LowFrqSet 1;
BA_ "EventCommandSignal" SG_ 767 AMP_MidFrqSet 0;
BA_ "GenSigSendType" SG_ 767 AMP_MidFrqSet 1;
BA_ "EventCommandSignal" SG_ 767 AMP_HighFrqSet 0;
BA_ "GenSigSendType" SG_ 767 AMP_HighFrqSet 1;
BA_ "EventCommandSignal" SG_ 767 AMP_VSCModeSt 0;
BA_ "GenSigSendType" SG_ 767 AMP_VSCModeSt 1;
BA_ "EventCommandSignal" SG_ 767 AMP_DriveSideSt 0;
BA_ "GenSigSendType" SG_ 767 AMP_DriveSideSt 1;
BA_ "EventCommandSignal" SG_ 767 AMP_MuteRearSet 0;
BA_ "GenSigSendType" SG_ 767 AMP_MuteRearSet 1;
BA_ "EventCommandSignal" SG_ 767 AMP_MuteSt 0;
BA_ "GenSigSendType" SG_ 767 AMP_MuteSt 1;
BA_ "EventCommandSignal" SG_ 767 AMP_SpeakFL 0;
BA_ "GenSigSendType" SG_ 767 AMP_SpeakFL 1;
BA_ "EventCommandSignal" SG_ 767 AMP_SpeakrFR 0;
BA_ "GenSigSendType" SG_ 767 AMP_SpeakrFR 1;
BA_ "EventCommandSignal" SG_ 767 AMP_SpeakrRL 0;
BA_ "GenSigSendType" SG_ 767 AMP_SpeakrRL 1;
BA_ "EventCommandSignal" SG_ 767 AMP_SpeakrRR 0;
BA_ "GenSigSendType" SG_ 767 AMP_SpeakrRR 1;
BA_ "EventCommandSignal" SG_ 767 AMP_TelVolSetSts 0;
BA_ "GenSigSendType" SG_ 767 AMP_TelVolSetSts 1;
BA_ "EventCommandSignal" SG_ 767 AMP_VRVolSetSts 0;
BA_ "GenSigSendType" SG_ 767 AMP_VRVolSetSts 1;
BA_ "EventCommandSignal" SG_ 767 AMP_NaviVolSetSts 0;
BA_ "GenSigSendType" SG_ 767 AMP_NaviVolSetSts 1;
BA_ "EventCommandSignal" SG_ 767 AMP_PhoneRingVolSetSts 0;
BA_ "GenSigSendType" SG_ 767 AMP_PhoneRingVolSetSts 1;
BA_ "EventCommandSignal" SG_ 767 AMP_MainVolSetSts 0;
BA_ "GenSigSendType" SG_ 767 AMP_MainVolSetSts 1;
BA_ "EventCommandSignal" SG_ 767 AMP_Cabin_ambienceVolSetSts 0;
BA_ "GenSigSendType" SG_ 767 AMP_Cabin_ambienceVolSetSts 1;
BA_ "EventCommandSignal" SG_ 767 AMP_OutcarFrontSPKVolSetSts 0;
BA_ "GenSigSendType" SG_ 767 AMP_OutcarFrontSPKVolSetSts 1;
BA_ "EventCommandSignal" SG_ 767 AMP_OutcarFrontMediaVolSetSts 0;
BA_ "GenSigSendType" SG_ 767 AMP_OutcarFrontMediaVolSetSts 1;
BA_ "EventCommandSignal" SG_ 767 AMP_Headrest_Left_PrivateModeVol 0;
BA_ "GenSigSendType" SG_ 767 AMP_Headrest_Left_PrivateModeVol 1;
BA_ "SystemSignalLongSymbol" SG_ 767 AMP_Headrest_Left_PrivateModeVol "AMP_Headrest_Left_PrivateModeVolumeReq";
BA_ "EventCommandSignal" SG_ 767 AMP_Headrest_Right_PrivateModeVo 0;
BA_ "GenSigSendType" SG_ 767 AMP_Headrest_Right_PrivateModeVo 1;
BA_ "SystemSignalLongSymbol" SG_ 767 AMP_Headrest_Right_PrivateModeVo "AMP_Headrest_Right_PrivateModeVolumeReq";
BA_ "EventCommandSignal" SG_ 767 AMP_HeadrestDriverVolumeSt 0;
BA_ "GenSigSendType" SG_ 767 AMP_HeadrestDriverVolumeSt 1;
BA_ "EventCommandSignal" SG_ 767 AMP_Cabin_ambiencemodeSet 0;
BA_ "GenSigSendType" SG_ 767 AMP_Cabin_ambiencemodeSet 1;
BA_ "EventCommandSignal" SG_ 767 AMP_Headrest_Mode 0;
BA_ "GenSigSendType" SG_ 767 AMP_Headrest_Mode 1;
BA_ "EventCommandSignal" SG_ 767 AMP_SeatsmodeSet 0;
BA_ "GenSigSendType" SG_ 767 AMP_SeatsmodeSet 1;
BA_ "EventCommandSignal" SG_ 767 AMP_StrSurSet 0;
BA_ "GenSigSendType" SG_ 767 AMP_StrSurSet 1;
BA_ "EventCommandSignal" SG_ 767 AMP_AdigoVirtualLiveSeSts 0;
BA_ "GenSigSendType" SG_ 767 AMP_AdigoVirtualLiveSeSts 1;
BA_ "EventCommandSignal" SG_ 767 AMP_ESEMode 0;
BA_ "GenSigSendType" SG_ 767 AMP_ESEMode 1;
BA_ "EventCommandSignal" SG_ 767 AMP_ESESwitchSts 0;
BA_ "GenSigSendType" SG_ 767 AMP_ESESwitchSts 1;
BA_ "EventCommandSignal" SG_ 767 AMP_ESEType 0;
BA_ "GenSigSendType" SG_ 767 AMP_ESEType 1;
BA_ "EventCommandSignal" SG_ 767 AMP_AVASMode 0;
BA_ "GenSigSendType" SG_ 767 AMP_AVASMode 1;
BA_ "EventCommandSignal" SG_ 767 AMP_AVASSwitch 0;
BA_ "GenSigSendType" SG_ 767 AMP_AVASSwitch 1;
BA_ "EventCommandSignal" SG_ 767 AMP_OutcarMediaSwitch 0;
BA_ "GenSigSendType" SG_ 767 AMP_OutcarMediaSwitch 1;
BA_ "EventCommandSignal" SG_ 767 AMP_A2BSet 0;
BA_ "GenSigSendType" SG_ 767 AMP_A2BSet 1;
BA_ "EventCommandSignal" SG_ 767 AMP_FamilyCinemaSwitchSts 0;
BA_ "GenSigSendType" SG_ 767 AMP_FamilyCinemaSwitchSts 1;
BA_ "EventCommandSignal" SG_ 767 AMP_TempValue 0;
BA_ "GenSigSendType" SG_ 767 AMP_TempValue 1;
BA_ "EventCommandSignal" SG_ 767 AMP_VolValue 0;
BA_ "GenSigSendType" SG_ 767 AMP_VolValue 1;
BA_ "EventCommandSignal" SG_ 767 AMP_GetHUTInfoSts 0;
BA_ "GenSigSendType" SG_ 767 AMP_GetHUTInfoSts 1;
BA_ "EventCommandSignal" SG_ 873 DCDC_FaultLampInd 0;
BA_ "GatewayedSignals" SG_ 873 DCDC_FaultLampInd 1;
BA_ "GenSigSendType" SG_ 873 DCDC_FaultLampInd 1;
BA_ "EventCommandSignal" SG_ 873 DCDC_FaultLampIndOperationFlag 0;
BA_ "GatewayedSignals" SG_ 873 DCDC_FaultLampIndOperationFlag 1;
BA_ "GenSigSendType" SG_ 873 DCDC_FaultLampIndOperationFlag 1;
BA_ "EventCommandSignal" SG_ 163 ACU_DPMessageSt 1;
BA_ "GatewayedSignals" SG_ 163 ACU_DPMessageSt 0;
BA_ "GenSigSendType" SG_ 163 ACU_DPMessageSt 0;
BA_ "GenSigSendType" SG_ 163 ACU_RAEBcfg 0;
BA_ "GatewayedSignals" SG_ 163 ACU_RAEBcfg 0;
BA_ "EventCommandSignal" SG_ 163 ACU_RAEBcfg 0;
BA_ "EventCommandSignal" SG_ 163 ACU_ParkingBoxAngle 1;
BA_ "GatewayedSignals" SG_ 163 ACU_ParkingBoxAngle 0;
BA_ "GenSigSendType" SG_ 163 ACU_ParkingBoxAngle 0;
BA_ "EventCommandSignal" SG_ 163 ACU_ParkingBoxMidX 1;
BA_ "GatewayedSignals" SG_ 163 ACU_ParkingBoxMidX 0;
BA_ "GenSigSendType" SG_ 163 ACU_ParkingBoxMidX 0;
BA_ "EventCommandSignal" SG_ 163 ACU_AVPMessageSt 0;
BA_ "GatewayedSignals" SG_ 163 ACU_AVPMessageSt 0;
BA_ "GenSigSendType" SG_ 163 ACU_AVPMessageSt 0;
BA_ "EventCommandSignal" SG_ 163 ACU_HPAMessageSt 0;
BA_ "GatewayedSignals" SG_ 163 ACU_HPAMessageSt 0;
BA_ "GenSigSendType" SG_ 163 ACU_HPAMessageSt 0;
BA_ "EventCommandSignal" SG_ 163 ACU_APAMessageSt 1;
BA_ "GatewayedSignals" SG_ 163 ACU_APAMessageSt 0;
BA_ "GenSigSendType" SG_ 163 ACU_APAMessageSt 0;
BA_ "GenSigSendType" SG_ 163 ACU_NDAVoicePromptTypeCfg 0;
BA_ "GatewayedSignals" SG_ 163 ACU_NDAVoicePromptTypeCfg 0;
BA_ "EventCommandSignal" SG_ 163 ACU_NDAVoicePromptTypeCfg 1;
BA_ "GenSigSendType" SG_ 163 ACU_LowPowerConfig 0;
BA_ "GatewayedSignals" SG_ 163 ACU_LowPowerConfig 0;
BA_ "EventCommandSignal" SG_ 163 ACU_LowPowerConfig 1;
BA_ "GenSigSendType" SG_ 163 ACU_PCSModeSt 0;
BA_ "GatewayedSignals" SG_ 163 ACU_PCSModeSt 0;
BA_ "EventCommandSignal" SG_ 163 ACU_PCSModeSt 1;
BA_ "GenSigSendType" SG_ 163 ACU_PCS_MirrorpagedownButtonST 0;
BA_ "EventCommandSignal" SG_ 163 ACU_PCS_MirrorpagedownButtonST 0;
BA_ "GenSigSendType" SG_ 163 ACU_DisplayReq 0;
BA_ "EventCommandSignal" SG_ 163 ACU_DisplayReq 1;
BA_ "GenSigSendType" SG_ 163 ACU_PCS_ScreenCoordX 0;
BA_ "EventCommandSignal" SG_ 163 ACU_PCS_ScreenCoordX 1;
BA_ "GenSigSendType" SG_ 163 ACU_PCS_ScreenCoordY 0;
BA_ "EventCommandSignal" SG_ 163 ACU_PCS_ScreenCoordY 1;
BA_ "GenSigSendType" SG_ 163 ACU_PCS_ScreenTouchSignal 0;
BA_ "EventCommandSignal" SG_ 163 ACU_PCS_ScreenTouchSignal 1;
BA_ "GenSigSendType" SG_ 163 ACU_PCS_ER_QuitConfirm 0;
BA_ "EventCommandSignal" SG_ 163 ACU_PCS_ER_QuitConfirm 1;
BA_ "GenSigSendType" SG_ 163 ACU_PCS_ER_EnterCmd 0;
BA_ "EventCommandSignal" SG_ 163 ACU_PCS_ER_EnterCmd 1;
BA_ "GenSigSendType" SG_ 163 ACU_ER_FuncCfg 0;
BA_ "EventCommandSignal" SG_ 163 ACU_ER_FuncCfg 1;
BA_ "GenSigSendType" SG_ 163 ACU_PCS_SVM_FunctionCmd 0;
BA_ "EventCommandSignal" SG_ 163 ACU_PCS_SVM_FunctionCmd 1;
BA_ "GenSigSendType" SG_ 163 ACU_LanguageTypeSet 1;
BA_ "GenSigStartValue" SG_ 163 ACU_LanguageTypeSet 1;
BA_ "EventCommandSignal" SG_ 163 ACU_LanguageTypeSet 0;
BA_ "GenSigSendType" SG_ 163 ACU_PCS_ScreenTouchSt 0;
BA_ "EventCommandSignal" SG_ 163 ACU_PCS_ScreenTouchSt 1;
BA_ "GenSigSendType" SG_ 163 ACU_SVM_Button 0;
BA_ "EventCommandSignal" SG_ 163 ACU_SVM_Button 1;
BA_ "EventCommandSignal" SG_ 163 ACU_PAAMode 1;
BA_ "GenSigSendType" SG_ 163 ACU_PAAMode 0;
BA_ "GenSigSendType" SG_ 739 ICM_VehicleSpeed 1;
BA_ "GenSigInvalidValue" SG_ 739 ICM_VehicleSpeed 255;
BA_ "EventCommandSignal" SG_ 739 ICM_VehicleSpeed 0;
BA_ "GenSigSendType" SG_ 739 ICM_FS_Enable 1;
BA_ "EventCommandSignal" SG_ 739 ICM_FS_Enable 0;
BA_ "EventCommandSignal" SG_ 739 IDC_IID_1_CRC 0;
BA_ "GenSigSendType" SG_ 739 IDC_IID_1_CRC 1;
BA_ "EventCommandSignal" SG_ 739 ICM_ADAS4Lamp 0;
BA_ "GenSigSendType" SG_ 739 ICM_ADAS4Lamp 1;
BA_ "EventCommandSignal" SG_ 739 ICM_ADAS3Lamp 0;
BA_ "GenSigSendType" SG_ 739 ICM_ADAS3Lamp 1;
BA_ "EventCommandSignal" SG_ 739 ICM_ADAS2Lamp 0;
BA_ "GenSigSendType" SG_ 739 ICM_ADAS2Lamp 1;
BA_ "EventCommandSignal" SG_ 739 ICM_ADAS1Lamp 0;
BA_ "GenSigSendType" SG_ 739 ICM_ADAS1Lamp 1;
BA_ "EventCommandSignal" SG_ 739 ICM_HandsOffLamp 0;
BA_ "GenSigSendType" SG_ 739 ICM_HandsOffLamp 1;
BA_ "EventCommandSignal" SG_ 739 ICM_BrakeLamp 0;
BA_ "GenSigSendType" SG_ 739 ICM_BrakeLamp 1;
BA_ "EventCommandSignal" SG_ 739 ICM_EPBLamp 0;
BA_ "GenSigSendType" SG_ 739 ICM_EPBLamp 1;
BA_ "EventCommandSignal" SG_ 739 ICM_PlugConnectLamp 0;
BA_ "GenSigSendType" SG_ 739 ICM_PlugConnectLamp 1;
BA_ "GenSigSendType" SG_ 739 ICM_DCDCFailLamp 1;
BA_ "EventCommandSignal" SG_ 739 ICM_DCDCFailLamp 0;
BA_ "GenSigSendType" SG_ 739 ICM_DynamicalsystemFailLamp 1;
BA_ "EventCommandSignal" SG_ 739 ICM_DynamicalsystemFailLamp 0;
BA_ "GenSigSendType" SG_ 739 ICM_SRSLamp 1;
BA_ "EventCommandSignal" SG_ 739 ICM_SRSLamp 0;
BA_ "GenSigSendType" SG_ 739 ICM_EPSLamp 1;
BA_ "EventCommandSignal" SG_ 739 ICM_EPSLamp 0;
BA_ "GenSigSendType" SG_ 739 ICM_EPBFailLamp 1;
BA_ "EventCommandSignal" SG_ 739 ICM_EPBFailLamp 0;
BA_ "GenSigSendType" SG_ 739 ICM_ESPOFFLamp 1;
BA_ "EventCommandSignal" SG_ 739 ICM_ESPOFFLamp 0;
BA_ "GenSigSendType" SG_ 739 ICM_ESPLamp 1;
BA_ "EventCommandSignal" SG_ 739 ICM_ESPLamp 0;
BA_ "GenSigSendType" SG_ 739 ICM_ABSLamp 1;
BA_ "EventCommandSignal" SG_ 739 ICM_ABSLamp 0;
BA_ "GenSigSendType" SG_ 739 DataLength 1;
BA_ "EventCommandSignal" SG_ 739 DataLength 0;
BA_ "GenSigSendType" SG_ 739 SID 1;
BA_ "EventCommandSignal" SG_ 739 SID 0;
BA_ "GenSigSendType" SG_ 739 ICM_GearInfo 1;
BA_ "EventCommandSignal" SG_ 739 ICM_GearInfo 0;
BA_ "GenSigSendType" SG_ 739 ICM_Theme 1;
BA_ "EventCommandSignal" SG_ 739 ICM_Theme 0;
BA_ "GenSigSendType" SG_ 739 IDC_IID_1_Counter 1;
BA_ "EventCommandSignal" SG_ 739 IDC_IID_1_Counter 0;
BA_ "EventCommandSignal" SG_ 918 UINM_PADS_VolRollerVD 0;
BA_ "GenSigSendType" SG_ 918 UINM_PADS_VolRollerVD 1;
BA_ "EventCommandSignal" SG_ 918 UINM_PADS_VolRollerSt 0;
BA_ "GenSigSendType" SG_ 918 UINM_PADS_VolRollerSt 1;
BA_ "EventCommandSignal" SG_ 918 UINM_PADS_VolRollerRotatedDir 0;
BA_ "GenSigSendType" SG_ 918 UINM_PADS_VolRollerRotatedDir 1;
BA_ "EventCommandSignal" SG_ 918 UINM_PADS_R_UpSWStVD 0;
BA_ "GenSigSendType" SG_ 918 UINM_PADS_R_UpSWStVD 1;
BA_ "EventCommandSignal" SG_ 918 UINM_PADS_R_UpSWSt 0;
BA_ "GenSigSendType" SG_ 918 UINM_PADS_R_UpSWSt 1;
BA_ "EventCommandSignal" SG_ 918 UINM_PADS_R_UDRollerRSt 0;
BA_ "GenSigSendType" SG_ 918 UINM_PADS_R_UDRollerRSt 1;
BA_ "EventCommandSignal" SG_ 918 UINM_PADS_R_UDRollerRotatedDir 0;
BA_ "GenSigSendType" SG_ 918 UINM_PADS_R_UDRollerRotatedDir 1;
BA_ "EventCommandSignal" SG_ 918 UINM_PADS_R_RightSWStVD 0;
BA_ "GenSigSendType" SG_ 918 UINM_PADS_R_RightSWStVD 1;
BA_ "EventCommandSignal" SG_ 918 UINM_PADS_R_RightSWSt 0;
BA_ "GenSigSendType" SG_ 918 UINM_PADS_R_RightSWSt 1;
BA_ "EventCommandSignal" SG_ 918 UINM_PADS_R_LRRollerVD 0;
BA_ "GenSigSendType" SG_ 918 UINM_PADS_R_LRRollerVD 1;
BA_ "EventCommandSignal" SG_ 918 UINM_PADS_R_LRRollerRSt 0;
BA_ "GenSigSendType" SG_ 918 UINM_PADS_R_LRRollerRSt 1;
BA_ "EventCommandSignal" SG_ 918 UINM_PADS_R_LRRollerRotatedDir 0;
BA_ "GenSigSendType" SG_ 918 UINM_PADS_R_LRRollerRotatedDir 1;
BA_ "EventCommandSignal" SG_ 918 UINM_PADS_R_LeftSWStVD 0;
BA_ "GenSigSendType" SG_ 918 UINM_PADS_R_LeftSWStVD 1;
BA_ "EventCommandSignal" SG_ 918 UINM_PADS_R_leftSWSt 0;
BA_ "GenSigSendType" SG_ 918 UINM_PADS_R_leftSWSt 1;
BA_ "EventCommandSignal" SG_ 918 UINM_PADS_R_DownSWStVD 0;
BA_ "GenSigSendType" SG_ 918 UINM_PADS_R_DownSWStVD 1;
BA_ "EventCommandSignal" SG_ 918 UINM_PADS_R_DownSWSt 0;
BA_ "GenSigSendType" SG_ 918 UINM_PADS_R_DownSWSt 1;
BA_ "EventCommandSignal" SG_ 918 UINM_PADS_L_UpSWStVD 0;
BA_ "GenSigSendType" SG_ 918 UINM_PADS_L_UpSWStVD 1;
BA_ "EventCommandSignal" SG_ 918 UINM_PADS_L_UpSWSt 0;
BA_ "GenSigSendType" SG_ 918 UINM_PADS_L_UpSWSt 1;
BA_ "EventCommandSignal" SG_ 918 UINM_PADS_L_UDRollerRSt 0;
BA_ "GenSigSendType" SG_ 918 UINM_PADS_L_UDRollerRSt 1;
BA_ "EventCommandSignal" SG_ 918 UINM_PADS_L_UDRollerRotatedDir 0;
BA_ "GenSigSendType" SG_ 918 UINM_PADS_L_UDRollerRotatedDir 1;
BA_ "EventCommandSignal" SG_ 918 UINM_PADS_L_RightSWStVD 0;
BA_ "GenSigSendType" SG_ 918 UINM_PADS_L_RightSWStVD 1;
BA_ "GenSigSendType" SG_ 918 UINM_PADS_L_RightSWSt 1;
BA_ "EventCommandSignal" SG_ 918 UINM_PADS_L_RightSWSt 0;
BA_ "GenSigSendType" SG_ 918 UINM_PADS_L_LRRollerVD 1;
BA_ "EventCommandSignal" SG_ 918 UINM_PADS_L_LRRollerVD 0;
BA_ "GenSigSendType" SG_ 918 UINM_PADS_L_LRRollerRSt 1;
BA_ "EventCommandSignal" SG_ 918 UINM_PADS_L_LRRollerRSt 0;
BA_ "GenSigSendType" SG_ 918 UINM_PADS_L_LRRollerRotatedDir 1;
BA_ "EventCommandSignal" SG_ 918 UINM_PADS_L_LRRollerRotatedDir 0;
BA_ "GenSigSendType" SG_ 918 UINM_PADS_L_LeftSWStVD 1;
BA_ "EventCommandSignal" SG_ 918 UINM_PADS_L_LeftSWStVD 0;
BA_ "GenSigSendType" SG_ 918 UINM_PADS_L_leftSWSt 1;
BA_ "EventCommandSignal" SG_ 918 UINM_PADS_L_leftSWSt 0;
BA_ "GenSigSendType" SG_ 918 UINM_PADS_L_DownSWStVD 1;
BA_ "EventCommandSignal" SG_ 918 UINM_PADS_L_DownSWStVD 0;
BA_ "GenSigSendType" SG_ 918 UINM_PADS_L_DownSWSt 1;
BA_ "EventCommandSignal" SG_ 918 UINM_PADS_L_DownSWSt 0;
BA_ "GenSigSendType" SG_ 918 UINM_PADS_Custom2SWStVD 1;
BA_ "EventCommandSignal" SG_ 918 UINM_PADS_Custom2SWStVD 0;
BA_ "GenSigSendType" SG_ 918 UINM_PADS_Custom2SWSt 1;
BA_ "EventCommandSignal" SG_ 918 UINM_PADS_Custom2SWSt 0;
BA_ "GenSigSendType" SG_ 918 UINM_PADS_CruSetSpeedRollerVD 1;
BA_ "EventCommandSignal" SG_ 918 UINM_PADS_CruSetSpeedRollerVD 0;
BA_ "EventCommandSignal" SG_ 918 UINM_PADS_Custom2SWStuckSt 0;
BA_ "GenSigSendType" SG_ 918 UINM_PADS_Custom2SWStuckSt 1;
BA_ "GenSigSendType" SG_ 918 UINM_PADS_CruSetSpeedRollerRotat 1;
BA_ "EventCommandSignal" SG_ 918 UINM_PADS_CruSetSpeedRollerRotat 0;
BA_ "SystemSignalLongSymbol" SG_ 918 UINM_PADS_CruSetSpeedRollerRotat "UINM_PADS_CruSetSpeedRollerRotatedDir";
BA_ "EventCommandSignal" SG_ 918 UINM_PADS_OKSWStuckSt 0;
BA_ "GenSigSendType" SG_ 918 UINM_PADS_OKSWStuckSt 1;
BA_ "EventCommandSignal" SG_ 918 UINM_PADS_OKSWStVD 0;
BA_ "GenSigSendType" SG_ 918 UINM_PADS_OKSWStVD 1;
BA_ "EventCommandSignal" SG_ 918 UINM_PADS_OKSWSt 0;
BA_ "GenSigSendType" SG_ 918 UINM_PADS_OKSWSt 1;
BA_ "EventCommandSignal" SG_ 918 UINM_PADS_FolDistDecSWStuckSt 0;
BA_ "GenSigSendType" SG_ 918 UINM_PADS_FolDistDecSWStuckSt 1;
BA_ "EventCommandSignal" SG_ 918 UINM_PADS_FolDistDecSWStVD 0;
BA_ "GenSigSendType" SG_ 918 UINM_PADS_FolDistDecSWStVD 1;
BA_ "EventCommandSignal" SG_ 918 UINM_PADS_FolDistDecSWSt 0;
BA_ "GenSigSendType" SG_ 918 UINM_PADS_FolDistDecSWSt 1;
BA_ "EventCommandSignal" SG_ 918 UINM_PADS_FolDistIncSWStuckSt 0;
BA_ "GenSigSendType" SG_ 918 UINM_PADS_FolDistIncSWStuckSt 1;
BA_ "EventCommandSignal" SG_ 918 UINM_PADS_FolDistIncSWStVD 0;
BA_ "GenSigSendType" SG_ 918 UINM_PADS_FolDistIncSWStVD 1;
BA_ "EventCommandSignal" SG_ 918 UINM_PADS_FolDistIncSWSt 0;
BA_ "GenSigSendType" SG_ 918 UINM_PADS_FolDistIncSWSt 1;
BA_ "EventCommandSignal" SG_ 918 UINM_PADS_CruSetSpeedRollerSt 0;
BA_ "GenSigSendType" SG_ 918 UINM_PADS_CruSetSpeedRollerSt 1;
BA_ "GenSigSendType" SG_ 918 UINM_PADS_IDC_PlaySWStuckSt 1;
BA_ "EventCommandSignal" SG_ 918 UINM_PADS_IDC_PlaySWStuckSt 0;
BA_ "GenSigSendType" SG_ 918 UINM_PADS_IDC_PlaySWStVD 1;
BA_ "EventCommandSignal" SG_ 918 UINM_PADS_IDC_PlaySWStVD 0;
BA_ "EventCommandSignal" SG_ 918 UINM_PADS_IDC_PlaySWSt 0;
BA_ "GenSigSendType" SG_ 918 UINM_PADS_IDC_PlaySWSt 1;
BA_ "EventCommandSignal" SG_ 918 UINM_PADS_IDC_SkipDecSWStuckSt 0;
BA_ "GenSigSendType" SG_ 918 UINM_PADS_IDC_SkipDecSWStuckSt 1;
BA_ "EventCommandSignal" SG_ 918 UINM_PADS_IDC_SkipDecSWStVD 0;
BA_ "GenSigSendType" SG_ 918 UINM_PADS_IDC_SkipDecSWStVD 1;
BA_ "EventCommandSignal" SG_ 918 UINM_PADS_IDC_SkipDecSWSt 0;
BA_ "GenSigSendType" SG_ 918 UINM_PADS_IDC_SkipDecSWSt 1;
BA_ "EventCommandSignal" SG_ 918 UINM_PADS_IDC_SkipIncSWStuckSt 0;
BA_ "GenSigSendType" SG_ 918 UINM_PADS_IDC_SkipIncSWStuckSt 1;
BA_ "EventCommandSignal" SG_ 918 UINM_PADS_IDC_SkipIncSWStVD 0;
BA_ "GenSigSendType" SG_ 918 UINM_PADS_IDC_SkipIncSWStVD 1;
BA_ "EventCommandSignal" SG_ 918 UINM_PADS_IDC_SkipIncSWSt 0;
BA_ "GenSigSendType" SG_ 918 UINM_PADS_IDC_SkipIncSWSt 1;
BA_ "EventCommandSignal" SG_ 918 UINM_PADS_CustomSWstuck 0;
BA_ "GenSigSendType" SG_ 918 UINM_PADS_CustomSWstuck 1;
BA_ "EventCommandSignal" SG_ 918 UINM_PADS_CustomSWStVD 0;
BA_ "GenSigSendType" SG_ 918 UINM_PADS_CustomSWStVD 1;
BA_ "EventCommandSignal" SG_ 918 UINM_PADS_CustomSWSt 0;
BA_ "GenSigSendType" SG_ 918 UINM_PADS_CustomSWSt 1;
BA_ "EventCommandSignal" SG_ 918 UINM_PADS_IDC_PhoneStuckSt 0;
BA_ "GenSigSendType" SG_ 918 UINM_PADS_IDC_PhoneStuckSt 1;
BA_ "GenSigSendType" SG_ 918 UINM_PADS_IDC_PhoneSWStVD 1;
BA_ "EventCommandSignal" SG_ 918 UINM_PADS_IDC_PhoneSWStVD 0;
BA_ "GenSigSendType" SG_ 918 UINM_PADS_IDC_PhoneSWSt 1;
BA_ "EventCommandSignal" SG_ 918 UINM_PADS_IDC_PhoneSWSt 0;
BA_ "GenSigSendType" SG_ 918 UINM_PADS_IDC_VrSWStuckSt 1;
BA_ "EventCommandSignal" SG_ 918 UINM_PADS_IDC_VrSWStuckSt 0;
BA_ "GenSigSendType" SG_ 918 UINM_PADS_IDC_VrSWStVD 1;
BA_ "EventCommandSignal" SG_ 918 UINM_PADS_IDC_VrSWStVD 0;
BA_ "GenSigSendType" SG_ 918 UINM_PADS_IDC_VrSWSt 1;
BA_ "EventCommandSignal" SG_ 918 UINM_PADS_IDC_VrSWSt 0;
BA_ "GenSigSendType" SG_ 918 UINM_PADS_IDC_ViewSWStuckSt 1;
BA_ "EventCommandSignal" SG_ 918 UINM_PADS_IDC_ViewSWStuckSt 0;
BA_ "EventCommandSignal" SG_ 918 UINM_PADS_IDC_ViewSWVD 0;
BA_ "GenSigSendType" SG_ 918 UINM_PADS_IDC_ViewSWVD 1;
BA_ "EventCommandSignal" SG_ 918 UINM_PADS_IDC_ViewSWSt 0;
BA_ "GenSigSendType" SG_ 918 UINM_PADS_IDC_ViewSWSt 1;
BA_ "GenSigSendType" SG_ 905 ICM_SoundWarnSilenceReq 1;
BA_ "GatewayedSignals" SG_ 905 ICM_SoundWarnSilenceReq 0;
BA_ "EventCommandSignal" SG_ 905 ICM_SoundWarnSilenceReq 0;
BA_ "GenSigSendType" SG_ 905 ICM_DispTheme 1;
BA_ "GatewayedSignals" SG_ 905 ICM_DispTheme 0;
BA_ "EventCommandSignal" SG_ 905 ICM_DispTheme 0;
BA_ "EventCommandSignal" SG_ 905 ICM_DisplayID 0;
BA_ "GatewayedSignals" SG_ 905 ICM_DisplayID 0;
BA_ "GenSigSendType" SG_ 905 ICM_DisplayID 1;
BA_ "EventCommandSignal" SG_ 905 ICM_VehInsSpd_accurate 0;
BA_ "GatewayedSignals" SG_ 905 ICM_VehInsSpd_accurate 0;
BA_ "GenSigInvalidValue" SG_ 905 ICM_VehInsSpd_accurate 2047;
BA_ "GenSigSendType" SG_ 905 ICM_VehInsSpd_accurate 1;
BA_ "GenSigSendType" SG_ 905 ICM_VehRunningOdometer 1;
BA_ "GenSigInvalidValue" SG_ 905 ICM_VehRunningOdometer 131071;
BA_ "GatewayedSignals" SG_ 905 ICM_VehRunningOdometer 0;
BA_ "EventCommandSignal" SG_ 905 ICM_VehRunningOdometer 0;
BA_ "GenSigSendType" SG_ 905 ICM_VehRunningOdometerTemp 1;
BA_ "GenSigInvalidValue" SG_ 905 ICM_VehRunningOdometerTemp 12287;
BA_ "GatewayedSignals" SG_ 905 ICM_VehRunningOdometerTemp 0;
BA_ "EventCommandSignal" SG_ 905 ICM_VehRunningOdometerTemp 0;
BA_ "GenSigSendType" SG_ 905 ICM_VehRunningTimeTemp 1;
BA_ "GenSigInvalidValue" SG_ 905 ICM_VehRunningTimeTemp 8191;
BA_ "GatewayedSignals" SG_ 905 ICM_VehRunningTimeTemp 0;
BA_ "EventCommandSignal" SG_ 905 ICM_VehRunningTimeTemp 0;
BA_ "GenSigSendType" SG_ 905 ICM_TotalAvaibleDriveDistance 1;
BA_ "GenSigInvalidValue" SG_ 905 ICM_TotalAvaibleDriveDistance 2047;
BA_ "GatewayedSignals" SG_ 905 ICM_TotalAvaibleDriveDistance 0;
BA_ "EventCommandSignal" SG_ 905 ICM_TotalAvaibleDriveDistance 0;
BA_ "GenSigSendType" SG_ 905 ICM_FuelAvaibleDriveDistance 1;
BA_ "GenSigInvalidValue" SG_ 905 ICM_FuelAvaibleDriveDistance 2047;
BA_ "GatewayedSignals" SG_ 905 ICM_FuelAvaibleDriveDistance 0;
BA_ "EventCommandSignal" SG_ 905 ICM_FuelAvaibleDriveDistance 0;
BA_ "GenSigSendType" SG_ 905 ICM_FuelLevelValue 1;
BA_ "GenSigInvalidValue" SG_ 905 ICM_FuelLevelValue 250;
BA_ "GatewayedSignals" SG_ 905 ICM_FuelLevelValue 0;
BA_ "EventCommandSignal" SG_ 905 ICM_FuelLevelValue 0;
BA_ "GenSigSendType" SG_ 905 ICM_BackLightLevel_accurate 1;
BA_ "GatewayedSignals" SG_ 905 ICM_BackLightLevel_accurate 0;
BA_ "EventCommandSignal" SG_ 905 ICM_BackLightLevel_accurate 0;
BA_ "GenSigSendType" SG_ 905 ICM_MFSButtonSt 1;
BA_ "EventCommandSignal" SG_ 905 ICM_MFSButtonSt 0;
BA_ "GenSigSendType" SG_ 905 ICM_SetIACCSt 1;
BA_ "EventCommandSignal" SG_ 905 ICM_SetIACCSt 0;
BA_ "GenSigStartValue" SG_ 905 ICM_VehicleBrakeSt 1;
BA_ "GenSigSendType" SG_ 905 ICM_VehicleBrakeSt 1;
BA_ "EventCommandSignal" SG_ 905 ICM_VehicleBrakeSt 0;
BA_ "GenSigStartValue" SG_ 905 ICM_AirbagLampFaultSt 1;
BA_ "GenSigSendType" SG_ 905 ICM_AirbagLampFaultSt 1;
BA_ "EventCommandSignal" SG_ 905 ICM_AirbagLampFaultSt 0;
BA_ "GenSigSendType" SG_ 905 ICM_ChargingSt 1;
BA_ "EventCommandSignal" SG_ 905 ICM_ChargingSt 0;
BA_ "GenSigSendType" SG_ 905 ICM_BackLightLevel 1;
BA_ "EventCommandSignal" SG_ 905 ICM_BackLightLevel 0;
BA_ "GenSigSendType" SG_ 905 ICM_TotalOdometer 1;
BA_ "EventCommandSignal" SG_ 905 ICM_TotalOdometer 0;
BA_ "GenSigInvalidValue" SG_ 905 ICM_VehAverageSpd 255;
BA_ "GenSigSendType" SG_ 905 ICM_VehAverageSpd 1;
BA_ "EventCommandSignal" SG_ 905 ICM_VehAverageSpd 0;
BA_ "GenSigSendType" SG_ 905 ICM_BFLWarning 1;
BA_ "EventCommandSignal" SG_ 905 ICM_BFLWarning 0;
BA_ "GenSigSendType" SG_ 905 ICM_TripAVD 1;
BA_ "EventCommandSignal" SG_ 905 ICM_TripAVD 0;
BA_ "GenSigSendType" SG_ 905 ICM_TripA 1;
BA_ "EventCommandSignal" SG_ 905 ICM_TripA 0;
BA_ "GenSigSendType" SG_ 905 ICM_ElcConspAccumAvgClnCmd 1;
BA_ "EventCommandSignal" SG_ 905 ICM_ElcConspAccumAvgClnCmd 0;
BA_ "GenSigSendType" SG_ 905 ICM_TripBVD 1;
BA_ "EventCommandSignal" SG_ 905 ICM_TripBVD 0;
BA_ "GenSigSendType" SG_ 905 ICM_TripB 1;
BA_ "EventCommandSignal" SG_ 905 ICM_TripB 0;
BA_ "GenSigInvalidValue" SG_ 905 ICM_VehInsSpd 255;
BA_ "GenSigSendType" SG_ 905 ICM_VehInsSpd 1;
BA_ "EventCommandSignal" SG_ 905 ICM_VehInsSpd 0;
BA_ "GenSigStartValue" SG_ 905 ICM_BattVolt 128;
BA_ "GenSigInvalidValue" SG_ 905 ICM_BattVolt 255;
BA_ "GenSigSendType" SG_ 905 ICM_BattVolt 1;
BA_ "EventCommandSignal" SG_ 905 ICM_BattVolt 0;
BA_ "GenSigSendType" SG_ 905 ICM_BattVoltVD 1;
BA_ "EventCommandSignal" SG_ 905 ICM_BattVoltVD 0;
BA_ "GenSigSendType" SG_ 905 ICM_DisFail 1;
BA_ "EventCommandSignal" SG_ 905 ICM_DisFail 0;
BA_ "GenSigTimeoutValue" SG_ 905 ICM_DisFail 1;
BA_ "GenSigSendType" SG_ 905 ICM_QDashACCFail 1;
BA_ "EventCommandSignal" SG_ 905 ICM_QDashACCFail 0;
BA_ "GenSigTimeoutValue" SG_ 905 ICM_QDashACCFail 1;
BA_ "GenSigSendType" SG_ 905 ICM_TempUnitDisp 1;
BA_ "EventCommandSignal" SG_ 905 ICM_TempUnitDisp 0;
BA_ "GenSigSendType" SG_ 905 ICM_PrUnitDisp 1;
BA_ "EventCommandSignal" SG_ 905 ICM_PrUnitDisp 0;
BA_ "GenSigSendType" SG_ 905 ICM_TimeModeCfgSt 1;
BA_ "EventCommandSignal" SG_ 905 ICM_TimeModeCfgSt 0;
BA_ "GenSigInvalidValue" SG_ 905 ICM_VehRunningTime 65535;
BA_ "GenSigSendType" SG_ 905 ICM_VehRunningTime 1;
BA_ "EventCommandSignal" SG_ 905 ICM_VehRunningTime 0;
BA_ "GenSigSendType" SG_ 905 ICM_SpdWarnCfgSt 1;
BA_ "EventCommandSignal" SG_ 905 ICM_SpdWarnCfgSt 0;
BA_ "GenSigSendType" SG_ 905 ICM_LanguageCfgSt 1;
BA_ "EventCommandSignal" SG_ 905 ICM_LanguageCfgSt 0;
BA_ "GenSigSendType" SG_ 905 ICM_TotalOdometer_accurate 1;
BA_ "EventCommandSignal" SG_ 905 ICM_TotalOdometer_accurate 0;
BA_ "GenSigStartValue" SG_ 905 ICM_WarnSoundVolCfgSt 1;
BA_ "GenSigSendType" SG_ 905 ICM_WarnSoundVolCfgSt 1;
BA_ "EventCommandSignal" SG_ 905 ICM_WarnSoundVolCfgSt 0;
BA_ "GenSigSendType" SG_ 905 IDC_ICM_1_FreshnessValue 1;
BA_ "EventCommandSignal" SG_ 905 IDC_ICM_1_FreshnessValue 0;
BA_ "GenSigSendType" SG_ 905 IDC_ICM_1_MAC_Check 1;
BA_ "EventCommandSignal" SG_ 905 IDC_ICM_1_MAC_Check 0;
BA_ "GenSigSendType" SG_ 161 ACU_AccurHMIModeReq 0;
BA_ "GatewayedSignals" SG_ 161 ACU_AccurHMIModeReq 0;
BA_ "EventCommandSignal" SG_ 161 ACU_AccurHMIModeReq 1;
BA_ "GenSigStartValue" SG_ 161 ACU_RecpLevelCfgL 2;
BA_ "EventCommandSignal" SG_ 161 ACU_RecpLevelCfgL 0;
BA_ "GatewayedSignals" SG_ 161 ACU_RecpLevelCfgL 0;
BA_ "GenSigSendType" SG_ 161 ACU_RecpLevelCfgL 0;
BA_ "GenSigSendType" SG_ 161 ACU_BrkPedalModsetting 0;
BA_ "GenSigInvalidValue" SG_ 161 ACU_BrkPedalModsetting 127;
BA_ "GatewayedSignals" SG_ 161 ACU_BrkPedalModsetting 0;
BA_ "EventCommandSignal" SG_ 161 ACU_BrkPedalModsetting 1;
BA_ "GenSigSendType" SG_ 161 ACU_AccPdlLvlCfg 0;
BA_ "EventCommandSignal" SG_ 161 ACU_AccPdlLvlCfg 1;
BA_ "GenSigSendType" SG_ 161 ACU_AccurRngReq 0;
BA_ "EventCommandSignal" SG_ 161 ACU_AccurRngReq 1;
BA_ "EventCommandSignal" SG_ 161 ACU_EPSSteeringassistRatio 1;
BA_ "GenSigSendType" SG_ 161 ACU_EPSSteeringassistRatio 0;
BA_ "GenSigSendType" SG_ 161 ACU_IpedalCreepCfg 0;
BA_ "EventCommandSignal" SG_ 161 ACU_IpedalCreepCfg 0;
BA_ "GenSigSendType" SG_ 161 ACU_DischgSt 0;
BA_ "EventCommandSignal" SG_ 161 ACU_DischgSt 1;
BA_ "GenSigSendType" SG_ 161 ACU_EpedalCfg 0;
BA_ "EventCommandSignal" SG_ 161 ACU_EpedalCfg 0;
BA_ "GenSigSendType" SG_ 161 ACU_ESPST 0;
BA_ "EventCommandSignal" SG_ 161 ACU_ESPST 1;
BA_ "GenSigSendType" SG_ 161 ACU_WarmTimeCfg 0;
BA_ "EventCommandSignal" SG_ 161 ACU_WarmTimeCfg 0;
BA_ "GenSigStartValue" SG_ 161 ACU_DrvModCfg 3;
BA_ "GenSigSendType" SG_ 161 ACU_DrvModCfg 0;
BA_ "EventCommandSignal" SG_ 161 ACU_DrvModCfg 0;
BA_ "GenSigStartValue" SG_ 161 ACU_DischgSocCfg 20;
BA_ "GenSigSendType" SG_ 161 ACU_DischgSocCfg 0;
BA_ "EventCommandSignal" SG_ 161 ACU_DischgSocCfg 0;
BA_ "GenSigSendType" SG_ 161 ACU_EcoPlusModeCfg 0;
BA_ "EventCommandSignal" SG_ 161 ACU_EcoPlusModeCfg 0;
BA_ "GenSigSendType" SG_ 161 ACU_LongDistCfg 0;
BA_ "EventCommandSignal" SG_ 161 ACU_LongDistCfg 0;
BA_ "GenSigSendType" SG_ 161 ACU_ChgSOCCfg 0;
BA_ "EventCommandSignal" SG_ 161 ACU_ChgSOCCfg 0;
BA_ "GenSigSendType" SG_ 161 ACU_ChgPlugRelReq 0;
BA_ "EventCommandSignal" SG_ 161 ACU_ChgPlugRelReq 0;
BA_ "GenSigSendType" SG_ 161 ACU_EPBSwitchSt 0;
BA_ "EventCommandSignal" SG_ 161 ACU_EPBSwitchSt 1;
BA_ "GenSigSendType" SG_ 161 ACU_DragModeReq 0;
BA_ "EventCommandSignal" SG_ 161 ACU_DragModeReq 1;
BA_ "GenSigSendType" SG_ 161 ACU_AVHSoftSwitchst 0;
BA_ "EventCommandSignal" SG_ 161 ACU_AVHSoftSwitchst 1;
BA_ "GenSigSendType" SG_ 161 ACU_CST_OFFSwitch 0;
BA_ "EventCommandSignal" SG_ 161 ACU_CST_OFFSwitch 1;
BA_ "GenSigSendType" SG_ 161 ACU_EPSStyleCfg 0;
BA_ "EventCommandSignal" SG_ 161 ACU_EPSStyleCfg 1;
BA_ "GenSigSendType" SG_ 161 ACU_EPSCoupleFunctionSt 0;
BA_ "EventCommandSignal" SG_ 161 ACU_EPSCoupleFunctionSt 1;
BA_ "GenSigSendType" SG_ 161 ACU_ESPFuncSwCfg 0;
BA_ "EventCommandSignal" SG_ 161 ACU_ESPFuncSwCfg 1;
BA_ "GenSigSendType" SG_ 161 ACU_BrkPedalModeCfg 0;
BA_ "EventCommandSignal" SG_ 161 ACU_BrkPedalModeCfg 1;
BA_ "GenSigSendType" SG_ 161 IDC_DrvSwapModCfg 0;
BA_ "EventCommandSignal" SG_ 161 IDC_DrvSwapModCfg 0;
BA_ "GenSigSendType" SG_ 161 ACU_ChgmodeReq 0;
BA_ "EventCommandSignal" SG_ 161 ACU_ChgmodeReq 0;
BA_ "GenSigSendType" SG_ 161 ACU_TELInComingCallAnswerReq 0;
BA_ "EventCommandSignal" SG_ 161 ACU_TELInComingCallAnswerReq 1;
BA_ "GenSigSendType" SG_ 161 ACU_TELCallHangUpReq 0;
BA_ "EventCommandSignal" SG_ 161 ACU_TELCallHangUpReq 1;
BA_ "GenSigSendType" SG_ 161 ACU_TELBcallReq 0;
BA_ "EventCommandSignal" SG_ 161 ACU_TELBcallReq 1;
BA_ "GenSigSendType" SG_ 161 ACU_TELEcallReq 0;
BA_ "EventCommandSignal" SG_ 161 ACU_TELEcallReq 1;
BA_ "GenSigSendType" SG_ 161 ACU_TelModuleResetReq 0;
BA_ "EventCommandSignal" SG_ 161 ACU_TelModuleResetReq 1;
BA_ "GenSigSendType" SG_ 161 ACU_AuthRand 0;
BA_ "EventCommandSignal" SG_ 161 ACU_AuthRand 1;
BA_ "GenSigSendType" SG_ 161 ACU_AuthKey 0;
BA_ "EventCommandSignal" SG_ 161 ACU_AuthKey 1;
BA_ "EventCommandSignal" SG_ 351 IDC_2_Counter 0;
BA_ "GatewayedSignals" SG_ 351 IDC_2_Counter 0;
BA_ "GenSigSendType" SG_ 351 IDC_2_Counter 1;
BA_ "EventCommandSignal" SG_ 351 IDC_2_CRC 0;
BA_ "GatewayedSignals" SG_ 351 IDC_2_CRC 0;
BA_ "GenSigSendType" SG_ 351 IDC_2_CRC 1;
BA_ "GenSigSendType" SG_ 351 ACU_RLSeatHeatLevelReq 0;
BA_ "GenSigStartValue" SG_ 351 ACU_RLSeatHeatLevelReq 4;
BA_ "GatewayedSignals" SG_ 351 ACU_RLSeatHeatLevelReq 0;
BA_ "EventCommandSignal" SG_ 351 ACU_RLSeatHeatLevelReq 0;
BA_ "GenSigSendType" SG_ 351 ACU_RRSeatHeatLevelReq 0;
BA_ "GenSigStartValue" SG_ 351 ACU_RRSeatHeatLevelReq 4;
BA_ "GatewayedSignals" SG_ 351 ACU_RRSeatHeatLevelReq 0;
BA_ "EventCommandSignal" SG_ 351 ACU_RRSeatHeatLevelReq 0;
BA_ "GenSigSendType" SG_ 351 ACU_RRSeatVentLevelReq 0;
BA_ "GenSigStartValue" SG_ 351 ACU_RRSeatVentLevelReq 4;
BA_ "GatewayedSignals" SG_ 351 ACU_RRSeatVentLevelReq 0;
BA_ "EventCommandSignal" SG_ 351 ACU_RRSeatVentLevelReq 1;
BA_ "GenSigSendType" SG_ 351 ACU_RLSeatVentLevelReq 0;
BA_ "GenSigStartValue" SG_ 351 ACU_RLSeatVentLevelReq 4;
BA_ "GatewayedSignals" SG_ 351 ACU_RLSeatVentLevelReq 0;
BA_ "EventCommandSignal" SG_ 351 ACU_RLSeatVentLevelReq 1;
BA_ "GenSigSendType" SG_ 351 ACU_RRSeatAutoModeCfgReq 0;
BA_ "GatewayedSignals" SG_ 351 ACU_RRSeatAutoModeCfgReq 0;
BA_ "EventCommandSignal" SG_ 351 ACU_RRSeatAutoModeCfgReq 1;
BA_ "GenSigSendType" SG_ 351 ACU_RLSeatAutoModeCfgReq 0;
BA_ "GatewayedSignals" SG_ 351 ACU_RLSeatAutoModeCfgReq 0;
BA_ "EventCommandSignal" SG_ 351 ACU_RLSeatAutoModeCfgReq 1;
BA_ "GenSigSendType" SG_ 351 ACU_RearCamWasherVRReq 0;
BA_ "GenSigInvalidValue" SG_ 351 ACU_RearCamWasherVRReq 3;
BA_ "GatewayedSignals" SG_ 351 ACU_RearCamWasherVRReq 0;
BA_ "EventCommandSignal" SG_ 351 ACU_RearCamWasherVRReq 1;
BA_ "GenSigSendType" SG_ 351 ACU_RearCamWasherVKReq 0;
BA_ "GenSigInvalidValue" SG_ 351 ACU_RearCamWasherVKReq 3;
BA_ "GatewayedSignals" SG_ 351 ACU_RearCamWasherVKReq 0;
BA_ "EventCommandSignal" SG_ 351 ACU_RearCamWasherVKReq 1;
BA_ "GenSigSendType" SG_ 351 ACU_Account_Uld 0;
BA_ "GatewayedSignals" SG_ 351 ACU_Account_Uld 0;
BA_ "EventCommandSignal" SG_ 351 ACU_Account_Uld 1;
BA_ "GenSigSendType" SG_ 351 ACU_FRSeatSaveRecallReq 0;
BA_ "EventCommandSignal" SG_ 351 ACU_FRSeatSaveRecallReq 1;
BA_ "GenSigSendType" SG_ 351 ACU_FRSeatSaveRecallPstReq 0;
BA_ "EventCommandSignal" SG_ 351 ACU_FRSeatSaveRecallPstReq 1;
BA_ "GenSigSendType" SG_ 351 ACU_FLLumbarReq 0;
BA_ "EventCommandSignal" SG_ 351 ACU_FLLumbarReq 1;
BA_ "GenSigSendType" SG_ 351 ACU_HVACF_CO2LifeAlarmModeCfg 0;
BA_ "EventCommandSignal" SG_ 351 ACU_HVACF_CO2LifeAlarmModeCfg 1;
BA_ "EventCommandSignal" SG_ 351 ACU_HVACFInCarAutoVentilationCfg 1;
BA_ "GenSigSendType" SG_ 351 ACU_HVACFInCarAutoVentilationCfg 0;
BA_ "EventCommandSignal" SG_ 351 ACU_HVACF_CO2CleanReqFb 1;
BA_ "GenSigSendType" SG_ 351 ACU_HVACF_CO2CleanReqFb 0;
BA_ "GenSigSendType" SG_ 351 ACU_EEM_LoadControl 0;
BA_ "EventCommandSignal" SG_ 351 ACU_EEM_LoadControl 1;
BA_ "GenSigSendType" SG_ 351 ACU_ETC_SysCfg 0;
BA_ "EventCommandSignal" SG_ 351 ACU_ETC_SysCfg 1;
BA_ "GenSigSendType" SG_ 351 ACU_ETC_ICMDisplayCfg 0;
BA_ "EventCommandSignal" SG_ 351 ACU_ETC_ICMDisplayCfg 1;
BA_ "GenSigSendType" SG_ 351 ACU_ETC_BLEenableCfg 0;
BA_ "EventCommandSignal" SG_ 351 ACU_ETC_BLEenableCfg 1;
BA_ "GenSigSendType" SG_ 351 ACU_VirtualPowerOFFReq 0;
BA_ "EventCommandSignal" SG_ 351 ACU_VirtualPowerOFFReq 1;
BA_ "GenSigSendType" SG_ 351 ACU_VirtualPowerOFFReqVd 1;
BA_ "EventCommandSignal" SG_ 351 ACU_VirtualPowerOFFReqVd 0;
BA_ "GenSigSendType" SG_ 351 ACU_VirtualPowerKeepReq 0;
BA_ "EventCommandSignal" SG_ 351 ACU_VirtualPowerKeepReq 1;
BA_ "GenSigSendType" SG_ 351 ACU_VirtualPowerKeepReqVd 1;
BA_ "EventCommandSignal" SG_ 351 ACU_VirtualPowerKeepReqVd 1;
BA_ "GenSigSendType" SG_ 351 ACU_WALCfg 0;
BA_ "EventCommandSignal" SG_ 351 ACU_WALCfg 1;
BA_ "GenSigSendType" SG_ 351 ACU_SeatNapPopUpReq 0;
BA_ "EventCommandSignal" SG_ 351 ACU_SeatNapPopUpReq 1;
BA_ "GenSigSendType" SG_ 351 ACU_APUCfg 0;
BA_ "EventCommandSignal" SG_ 351 ACU_APUCfg 1;
BA_ "GenSigSendType" SG_ 351 ACU_SATOCfg 0;
BA_ "EventCommandSignal" SG_ 351 ACU_SATOCfg 1;
BA_ "GenSigSendType" SG_ 351 ACU_HVAC_AirCirCfg 0;
BA_ "EventCommandSignal" SG_ 351 ACU_HVAC_AirCirCfg 1;
BA_ "GenSigSendType" SG_ 351 ACU_HVAC_ComfortCfg 0;
BA_ "EventCommandSignal" SG_ 351 ACU_HVAC_ComfortCfg 1;
BA_ "GenSigSendType" SG_ 351 ACU_HVACF_AQSCfg 0;
BA_ "EventCommandSignal" SG_ 351 ACU_HVACF_AQSCfg 1;
BA_ "GenSigSendType" SG_ 351 ACU_HVACF_FanspeedCfg 0;
BA_ "EventCommandSignal" SG_ 351 ACU_HVACF_FanspeedCfg 1;
BA_ "GenSigSendType" SG_ 351 ACU_HVACF_EvapratorSelfCleanCfg 0;
BA_ "EventCommandSignal" SG_ 351 ACU_HVACF_EvapratorSelfCleanCfg 1;
BA_ "GenSigSendType" SG_ 351 ACU_HVACF_UnlockVentilationCfg 0;
BA_ "EventCommandSignal" SG_ 351 ACU_HVACF_UnlockVentilationCfg 1;
BA_ "GenSigSendType" SG_ 351 ACU_HVACF_PM25CleanReqFb 0;
BA_ "EventCommandSignal" SG_ 351 ACU_HVACF_PM25CleanReqFb 1;
BA_ "GenSigSendType" SG_ 351 ACU_MultiIDManageReq 0;
BA_ "EventCommandSignal" SG_ 351 ACU_MultiIDManageReq 1;
BA_ "GenSigSendType" SG_ 351 ACU_HVAC_FraganceConcentrationSt 0;
BA_ "EventCommandSignal" SG_ 351 ACU_HVAC_FraganceConcentrationSt 1;
BA_ "GenSigStartValue" SG_ 351 ACU_HVACFR_DrTempSetting 29;
BA_ "GenSigSendType" SG_ 351 ACU_HVACFR_DrTempSetting 0;
BA_ "EventCommandSignal" SG_ 351 ACU_HVACFR_DrTempSetting 1;
BA_ "GenSigSendType" SG_ 351 ACU_HVAC_FraganceTasteSt 0;
BA_ "EventCommandSignal" SG_ 351 ACU_HVAC_FraganceTasteSt 1;
BA_ "GenSigSendType" SG_ 351 ACU_WCM_SwitchStCfg 0;
BA_ "EventCommandSignal" SG_ 351 ACU_WCM_SwitchStCfg 1;
BA_ "GenSigSendType" SG_ 351 ACU_HVACFR_ModeSetting 0;
BA_ "EventCommandSignal" SG_ 351 ACU_HVACFR_ModeSetting 1;
BA_ "GenSigSendType" SG_ 351 ACU_HVAC_RearMODESetting 0;
BA_ "EventCommandSignal" SG_ 351 ACU_HVAC_RearMODESetting 1;
BA_ "GenSigStartValue" SG_ 351 ACU_HVACFR_PsnTempSetting 29;
BA_ "GenSigSendType" SG_ 351 ACU_HVACFR_PsnTempSetting 0;
BA_ "EventCommandSignal" SG_ 351 ACU_HVACFR_PsnTempSetting 1;
BA_ "GenSigStartValue" SG_ 351 ACU_HVACFR_RrTempSetting 29;
BA_ "GenSigSendType" SG_ 351 ACU_HVACFR_RrTempSetting 0;
BA_ "EventCommandSignal" SG_ 351 ACU_HVACFR_RrTempSetting 1;
BA_ "GenSigSendType" SG_ 351 ACU_HVACF_VR_HVACONOFF 0;
BA_ "EventCommandSignal" SG_ 351 ACU_HVACF_VR_HVACONOFF 1;
BA_ "GenSigSendType" SG_ 351 ACU_HVAC_RearWindSpdSet 0;
BA_ "EventCommandSignal" SG_ 351 ACU_HVAC_RearWindSpdSet 1;
BA_ "GenSigSendType" SG_ 351 ACU_VehicleSearchHornCfg 0;
BA_ "EventCommandSignal" SG_ 351 ACU_VehicleSearchHornCfg 1;
BA_ "GenSigSendType" SG_ 351 ACU_MirrorAutoFoldFuncCfg 0;
BA_ "EventCommandSignal" SG_ 351 ACU_MirrorAutoFoldFuncCfg 1;
BA_ "GenSigSendType" SG_ 351 ACU_MirrorAngleDipFuncCfg 0;
BA_ "EventCommandSignal" SG_ 351 ACU_MirrorAngleDipFuncCfg 1;
BA_ "GenSigSendType" SG_ 351 ACU_EasyEntryExitFuncCfg 0;
BA_ "EventCommandSignal" SG_ 351 ACU_EasyEntryExitFuncCfg 1;
BA_ "GenSigSendType" SG_ 351 ACU_ShortcutMode 0;
BA_ "EventCommandSignal" SG_ 351 ACU_ShortcutMode 1;
BA_ "GenSigSendType" SG_ 351 ACU_SeatNapSettingSaveCmd 0;
BA_ "EventCommandSignal" SG_ 351 ACU_SeatNapSettingSaveCmd 1;
BA_ "GenSigStartValue" SG_ 351 ACU_Account_Delete 255;
BA_ "GenSigSendType" SG_ 351 ACU_Account_Delete 0;
BA_ "EventCommandSignal" SG_ 351 ACU_Account_Delete 1;
BA_ "GenSigSendType" SG_ 351 ACU_FrontWiperIntCfgVkReq 0;
BA_ "EventCommandSignal" SG_ 351 ACU_FrontWiperIntCfgVkReq 1;
BA_ "GenSigSendType" SG_ 351 ACU_FrontWiperAutoCfgVkReq 0;
BA_ "EventCommandSignal" SG_ 351 ACU_FrontWiperAutoCfgVkReq 1;
BA_ "GenSigSendType" SG_ 351 ACU_FrontWasherVRReq 0;
BA_ "EventCommandSignal" SG_ 351 ACU_FrontWasherVRReq 1;
BA_ "GenSigSendType" SG_ 351 ACU_FrontWasherVKReq 0;
BA_ "EventCommandSignal" SG_ 351 ACU_FrontWasherVKReq 1;
BA_ "GenSigSendType" SG_ 351 ACU_FrontWiperVKReq 0;
BA_ "EventCommandSignal" SG_ 351 ACU_FrontWiperVKReq 1;
BA_ "GenSigSendType" SG_ 351 ACU_FrontWiperVRReq 0;
BA_ "EventCommandSignal" SG_ 351 ACU_FrontWiperVRReq 1;
BA_ "GenSigSendType" SG_ 351 ACU_RearWiperVRReq 0;
BA_ "EventCommandSignal" SG_ 351 ACU_RearWiperVRReq 1;
BA_ "GenSigSendType" SG_ 351 ACU_RearWasherVRReq 0;
BA_ "EventCommandSignal" SG_ 351 ACU_RearWasherVRReq 1;
BA_ "GenSigSendType" SG_ 351 ACU_RWPServiceModeVKReq 0;
BA_ "EventCommandSignal" SG_ 351 ACU_RWPServiceModeVKReq 1;
BA_ "GenSigSendType" SG_ 351 ACU_RWPServiceModeVRReq 0;
BA_ "EventCommandSignal" SG_ 351 ACU_RWPServiceModeVRReq 1;
BA_ "GenSigSendType" SG_ 351 ACU_RearWasherVKReq 0;
BA_ "EventCommandSignal" SG_ 351 ACU_RearWasherVKReq 1;
BA_ "GenSigSendType" SG_ 351 ACU_FWPServiceModeVKReq 0;
BA_ "EventCommandSignal" SG_ 351 ACU_FWPServiceModeVKReq 1;
BA_ "GenSigSendType" SG_ 351 ACU_FWPServiceModeVRReq 0;
BA_ "EventCommandSignal" SG_ 351 ACU_FWPServiceModeVRReq 1;
BA_ "GenSigSendType" SG_ 351 ACU_FrontAutoWiperEnableCfg 0;
BA_ "EventCommandSignal" SG_ 351 ACU_FrontAutoWiperEnableCfg 1;
BA_ "GenSigSendType" SG_ 351 ACU_HeadLightLevelingVirtualSwSt 0;
BA_ "EventCommandSignal" SG_ 351 ACU_HeadLightLevelingVirtualSwSt 1;
BA_ "GenSigSendType" SG_ 351 ACU_WelcomeLightMode 0;
BA_ "EventCommandSignal" SG_ 351 ACU_WelcomeLightMode 1;
BA_ "GenSigSendType" SG_ 351 ACU_LightShowMode 0;
BA_ "EventCommandSignal" SG_ 351 ACU_LightShowMode 1;
BA_ "GenSigSendType" SG_ 351 ACU_LightShowFunCmd 0;
BA_ "EventCommandSignal" SG_ 351 ACU_LightShowFunCmd 1;
BA_ "GenSigSendType" SG_ 351 ACU_LightShowTimeFlag 1;
BA_ "EventCommandSignal" SG_ 351 ACU_LightShowTimeFlag 0;
BA_ "GenSigStartValue" SG_ 351 ACU_FLSeatVentModeReq 3;
BA_ "GenSigSendType" SG_ 351 ACU_FLSeatVentModeReq 0;
BA_ "EventCommandSignal" SG_ 351 ACU_FLSeatVentModeReq 1;
BA_ "GenSigStartValue" SG_ 351 ACU_FLSeatHeatLevelReq 4;
BA_ "GenSigSendType" SG_ 351 ACU_FLSeatHeatLevelReq 0;
BA_ "EventCommandSignal" SG_ 351 ACU_FLSeatHeatLevelReq 1;
BA_ "GenSigStartValue" SG_ 351 ACU_FLSeatVentLevelReq 4;
BA_ "GenSigSendType" SG_ 351 ACU_FLSeatVentLevelReq 0;
BA_ "EventCommandSignal" SG_ 351 ACU_FLSeatVentLevelReq 1;
BA_ "GenSigStartValue" SG_ 351 ACU_FRSeatHeatVentModeReq 3;
BA_ "GenSigSendType" SG_ 351 ACU_FRSeatHeatVentModeReq 0;
BA_ "EventCommandSignal" SG_ 351 ACU_FRSeatHeatVentModeReq 1;
BA_ "GenSigStartValue" SG_ 351 ACU_FRSeatHeatLevelReq 4;
BA_ "GenSigSendType" SG_ 351 ACU_FRSeatHeatLevelReq 0;
BA_ "EventCommandSignal" SG_ 351 ACU_FRSeatHeatLevelReq 1;
BA_ "GenSigStartValue" SG_ 351 ACU_FRSeatVentLevelReq 4;
BA_ "GenSigSendType" SG_ 351 ACU_FRSeatVentLevelReq 0;
BA_ "EventCommandSignal" SG_ 351 ACU_FRSeatVentLevelReq 1;
BA_ "GenSigSendType" SG_ 351 ACU_PosSaveRecallCmd 0;
BA_ "EventCommandSignal" SG_ 351 ACU_PosSaveRecallCmd 1;
BA_ "GenSigSendType" SG_ 351 ACU_FLSeatAutoModeCfgReq 0;
BA_ "EventCommandSignal" SG_ 351 ACU_FLSeatAutoModeCfgReq 1;
BA_ "GenSigSendType" SG_ 351 ACU_FRSeatAutoModeCfgReq 0;
BA_ "EventCommandSignal" SG_ 351 ACU_FRSeatAutoModeCfgReq 1;
BA_ "GenSigSendType" SG_ 351 ACU_FoldUnfoldCtlReq 0;
BA_ "EventCommandSignal" SG_ 351 ACU_FoldUnfoldCtlReq 1;
BA_ "GenSigSendType" SG_ 351 ACU_LockAutoWinCloseFunCfgReq 0;
BA_ "EventCommandSignal" SG_ 351 ACU_LockAutoWinCloseFunCfgReq 1;
BA_ "GenSigSendType" SG_ 351 ACU_VRPLGOpenReq 0;
BA_ "EventCommandSignal" SG_ 351 ACU_VRPLGOpenReq 1;
BA_ "GenSigSendType" SG_ 351 ACU_VRPLGOpenReqVD 1;
BA_ "EventCommandSignal" SG_ 351 ACU_VRPLGOpenReqVD 0;
BA_ "GenSigSendType" SG_ 351 ACU_ClearSetPositionReq 0;
BA_ "EventCommandSignal" SG_ 351 ACU_ClearSetPositionReq 1;
BA_ "GenSigSendType" SG_ 351 ACU_PLGControlReq 0;
BA_ "EventCommandSignal" SG_ 351 ACU_PLGControlReq 1;
BA_ "GenSigSendType" SG_ 351 ACU_VRPLGCloseReq 0;
BA_ "EventCommandSignal" SG_ 351 ACU_VRPLGCloseReq 1;
BA_ "GenSigSendType" SG_ 351 ACU_VRPLGCloseReqVD 1;
BA_ "EventCommandSignal" SG_ 351 ACU_VRPLGCloseReqVD 0;
BA_ "GenSigSendType" SG_ 351 ACU_ALSCfg 0;
BA_ "EventCommandSignal" SG_ 351 ACU_ALSCfg 1;
BA_ "GenSigSendType" SG_ 351 ACU_HeadLightDelayCfg 0;
BA_ "EventCommandSignal" SG_ 351 ACU_HeadLightDelayCfg 1;
BA_ "GenSigSendType" SG_ 351 ACU_IALFunctionCfg 0;
BA_ "EventCommandSignal" SG_ 351 ACU_IALFunctionCfg 1;
BA_ "GenSigSendType" SG_ 351 ACU_IALColorSetReq 0;
BA_ "EventCommandSignal" SG_ 351 ACU_IALColorSetReq 1;
BA_ "GenSigSendType" SG_ 351 ACU_IALBrightnessSetReq 0;
BA_ "EventCommandSignal" SG_ 351 ACU_IALBrightnessSetReq 1;
BA_ "GenSigSendType" SG_ 351 ACU_IALDriverModeCfg 0;
BA_ "EventCommandSignal" SG_ 351 ACU_IALDriverModeCfg 1;
BA_ "GenSigSendType" SG_ 351 ACU_IALMusicModeCfg 0;
BA_ "EventCommandSignal" SG_ 351 ACU_IALMusicModeCfg 1;
BA_ "GenSigSendType" SG_ 351 ACU_IALVoiceModeCfg 0;
BA_ "EventCommandSignal" SG_ 351 ACU_IALVoiceModeCfg 1;
BA_ "GenSigSendType" SG_ 351 ACU_AutoDomeLightCfg 0;
BA_ "EventCommandSignal" SG_ 351 ACU_AutoDomeLightCfg 1;
BA_ "GenSigSendType" SG_ 351 ACU_HVAC_SolarFeaturesCfg 0;
BA_ "EventCommandSignal" SG_ 351 ACU_HVAC_SolarFeaturesCfg 1;
BA_ "GenSigSendType" SG_ 351 ACU_DoorLookHornCfg 0;
BA_ "EventCommandSignal" SG_ 351 ACU_DoorLookHornCfg 1;
BA_ "GenSigStartValue" SG_ 351 ACU_FLSeatHeatModeReq 3;
BA_ "GenSigSendType" SG_ 351 ACU_FLSeatHeatModeReq 0;
BA_ "EventCommandSignal" SG_ 351 ACU_FLSeatHeatModeReq 1;
BA_ "GenSigStartValue" SG_ 351 ACU_FRSeatVentModeReq 3;
BA_ "GenSigSendType" SG_ 351 ACU_FRSeatVentModeReq 0;
BA_ "EventCommandSignal" SG_ 351 ACU_FRSeatVentModeReq 1;
BA_ "GenSigStartValue" SG_ 351 ACU_FRSeatHeatModeReq 3;
BA_ "GenSigSendType" SG_ 351 ACU_FRSeatHeatModeReq 0;
BA_ "EventCommandSignal" SG_ 351 ACU_FRSeatHeatModeReq 1;
BA_ "GenSigSendType" SG_ 351 ACU_HVACF_CirculationChangeReqFb 0;
BA_ "EventCommandSignal" SG_ 351 ACU_HVACF_CirculationChangeReqFb 1;
BA_ "GenSigInvalidValue" SG_ 351 ACU_HVACFR_WindSpeedSetting 127;
BA_ "GenSigSendType" SG_ 351 ACU_HVACFR_WindSpeedSetting 0;
BA_ "EventCommandSignal" SG_ 351 ACU_HVACFR_WindSpeedSetting 1;
BA_ "GenSigSendType" SG_ 351 ACU_HVACF_AutoDefCfg 0;
BA_ "EventCommandSignal" SG_ 351 ACU_HVACF_AutoDefCfg 1;
BA_ "GenSigSendType" SG_ 351 ACU_HVACF_TimedVentilationCfg 0;
BA_ "EventCommandSignal" SG_ 351 ACU_HVACF_TimedVentilationCfg 1;
BA_ "GenSigStartValue" SG_ 351 ACU_SteeringHeatReq 2;
BA_ "GenSigSendType" SG_ 351 ACU_SteeringHeatReq 0;
BA_ "EventCommandSignal" SG_ 351 ACU_SteeringHeatReq 1;
BA_ "GenSigSendType" SG_ 351 ACU_PLGCtrl 0;
BA_ "EventCommandSignal" SG_ 351 ACU_PLGCtrl 1;
BA_ "GenSigSendType" SG_ 351 ACU_PLGOpenReq 0;
BA_ "EventCommandSignal" SG_ 351 ACU_PLGOpenReq 1;
BA_ "GenSigSendType" SG_ 351 ACU_PLGOpenReqVD 1;
BA_ "EventCommandSignal" SG_ 351 ACU_PLGOpenReqVD 0;
BA_ "GenSigSendType" SG_ 351 ACU_PLGCloseReq 0;
BA_ "EventCommandSignal" SG_ 351 ACU_PLGCloseReq 1;
BA_ "GenSigSendType" SG_ 351 ACU_PLGCloseReqVD 1;
BA_ "EventCommandSignal" SG_ 351 ACU_PLGCloseReqVD 0;
BA_ "GenSigSendType" SG_ 351 ACU_PLGSetPstClearReq 0;
BA_ "EventCommandSignal" SG_ 351 ACU_PLGSetPstClearReq 1;
BA_ "GenSigSendType" SG_ 351 ACU_PLGMaxPstReq 0;
BA_ "EventCommandSignal" SG_ 351 ACU_PLGMaxPstReq 1;
BA_ "GenSigSendType" SG_ 351 ACU_PLGTrunkReleaseReq 0;
BA_ "EventCommandSignal" SG_ 351 ACU_PLGTrunkReleaseReq 1;
BA_ "GenSigSendType" SG_ 351 ACU_PLGFuncCfg 0;
BA_ "EventCommandSignal" SG_ 351 ACU_PLGFuncCfg 1;
BA_ "GenSigSendType" SG_ 879 ACU_SteeringPrkgButton 1;
BA_ "GatewayedSignals" SG_ 879 ACU_SteeringPrkgButton 0;
BA_ "EventCommandSignal" SG_ 879 ACU_SteeringPrkgButton 0;
BA_ "Remark" SG_ 879 ACU_SteeringPrkgButton "<E2E_Group1>";
BA_ "GenSigSendType" SG_ 879 ACU_VR_APAControl 1;
BA_ "GatewayedSignals" SG_ 879 ACU_VR_APAControl 0;
BA_ "EventCommandSignal" SG_ 879 ACU_VR_APAControl 0;
BA_ "Remark" SG_ 879 ACU_VR_APAControl "<E2E_Group1>";
BA_ "GenSigSendType" SG_ 879 ACU_DVR_Switch 0;
BA_ "GatewayedSignals" SG_ 879 ACU_DVR_Switch 0;
BA_ "EventCommandSignal" SG_ 879 ACU_DVR_Switch 1;
BA_ "Remark" SG_ 879 ACU_DVR_Switch "<E2E_Group1>";
BA_ "GenSigSendType" SG_ 879 ACU_PCS_SVM_MODCmd 1;
BA_ "GatewayedSignals" SG_ 879 ACU_PCS_SVM_MODCmd 0;
BA_ "EventCommandSignal" SG_ 879 ACU_PCS_SVM_MODCmd 0;
BA_ "Remark" SG_ 879 ACU_PCS_SVM_MODCmd "<E2E_Group1>";
BA_ "GenSigSendType" SG_ 879 ACU_PAS_ButtonPress 0;
BA_ "EventCommandSignal" SG_ 879 ACU_PAS_ButtonPress 1;
BA_ "GenSigSendType" SG_ 879 ACU_ThemeType 1;
BA_ "EventCommandSignal" SG_ 879 ACU_ThemeType 0;
BA_ "Remark" SG_ 879 IDC_3_Checksum "Message ID will be changed in PT0";
BA_ "GenSigSendType" SG_ 879 IDC_3_Checksum 1;
BA_ "EventCommandSignal" SG_ 879 IDC_3_Checksum 0;
BA_ "GenSigSendType" SG_ 879 IDC_3_RollingCounter 1;
BA_ "EventCommandSignal" SG_ 879 IDC_3_RollingCounter 0;
BA_ "GenSigSendType" SG_ 879 ACU_HeadLightVirtualSwSt 1;
BA_ "EventCommandSignal" SG_ 879 ACU_HeadLightVirtualSwSt 0;
BA_ "GenSigSendType" SG_ 879 ACU_FrontFogLightVirtualSwSt 1;
BA_ "EventCommandSignal" SG_ 879 ACU_FrontFogLightVirtualSwSt 0;
BA_ "GenSigSendType" SG_ 879 ACU_RearFogLightVirtualSwSt 1;
BA_ "EventCommandSignal" SG_ 879 ACU_RearFogLightVirtualSwSt 0;
BA_ "GenSigSendType" SG_ 879 ACU_HighBeamVirtualSwSt 1;
BA_ "EventCommandSignal" SG_ 879 ACU_HighBeamVirtualSwSt 0;
BA_ "GenSigSendType" SG_ 879 ACU_Account_Uid 1;
BA_ "EventCommandSignal" SG_ 879 ACU_Account_Uid 0;
BA_ "GenSigSendType" SG_ 879 ACU_FCWWarnDistanceCfg 1;
BA_ "EventCommandSignal" SG_ 879 ACU_FCWWarnDistanceCfg 0;
BA_ "GenSigSendType" SG_ 879 ACU_FCWCfg 1;
BA_ "EventCommandSignal" SG_ 879 ACU_FCWCfg 0;
BA_ "GenSigSendType" SG_ 879 ACU_AEBOff 1;
BA_ "EventCommandSignal" SG_ 879 ACU_AEBOff 0;
BA_ "GenSigSendType" SG_ 879 ACU_LDW_LKACfg 1;
BA_ "EventCommandSignal" SG_ 879 ACU_LDW_LKACfg 0;
BA_ "GenSigSendType" SG_ 879 ACU_TSR_SwitchReq 1;
BA_ "EventCommandSignal" SG_ 879 ACU_TSR_SwitchReq 0;
BA_ "GenSigSendType" SG_ 879 ACU_IHBC_SwitchReq 1;
BA_ "EventCommandSignal" SG_ 879 ACU_IHBC_SwitchReq 0;
BA_ "GenSigSendType" SG_ 879 ACU_LDS_TypeReq 1;
BA_ "EventCommandSignal" SG_ 879 ACU_LDS_TypeReq 0;
BA_ "GenSigSendType" SG_ 879 ACU_BSDCfg 1;
BA_ "EventCommandSignal" SG_ 879 ACU_BSDCfg 0;
BA_ "GenSigSendType" SG_ 879 ACU_RCTACfg 1;
BA_ "EventCommandSignal" SG_ 879 ACU_RCTACfg 0;
BA_ "GenSigSendType" SG_ 879 ACU_DOWCfg 1;
BA_ "EventCommandSignal" SG_ 879 ACU_DOWCfg 0;
BA_ "GenSigSendType" SG_ 879 ACU_iACC_SwitchReq 1;
BA_ "EventCommandSignal" SG_ 879 ACU_iACC_SwitchReq 0;
BA_ "GenSigSendType" SG_ 879 ACU_TSR_AudioWarnReq 1;
BA_ "EventCommandSignal" SG_ 879 ACU_TSR_AudioWarnReq 0;
BA_ "GenSigSendType" SG_ 879 ACU_HWAHFCfg 1;
BA_ "EventCommandSignal" SG_ 879 ACU_HWAHFCfg 0;
BA_ "GenSigSendType" SG_ 879 ACU_HWAHF_AudioWarningTypeCfg 1;
BA_ "EventCommandSignal" SG_ 879 ACU_HWAHF_AudioWarningTypeCfg 0;
BA_ "GenSigSendType" SG_ 879 ACU_HWA_SwitchReq 1;
BA_ "EventCommandSignal" SG_ 879 ACU_HWA_SwitchReq 0;
BA_ "GenSigSendType" SG_ 879 ACU_ELKCfg 1;
BA_ "EventCommandSignal" SG_ 879 ACU_ELKCfg 0;
BA_ "GenSigSendType" SG_ 879 ACU_FCTACfg 1;
BA_ "EventCommandSignal" SG_ 879 ACU_FCTACfg 0;
BA_ "GenSigSendType" SG_ 879 ACU_RAWCfg 1;
BA_ "EventCommandSignal" SG_ 879 ACU_RAWCfg 0;
BA_ "GenSigSendType" SG_ 879 ACU_RCTA_TypeReqCfg 1;
BA_ "EventCommandSignal" SG_ 879 ACU_RCTA_TypeReqCfg 0;
BA_ "GenSigSendType" SG_ 879 ACU_FCTA_TypeReqCfg 1;
BA_ "EventCommandSignal" SG_ 879 ACU_FCTA_TypeReqCfg 0;
BA_ "GenSigSendType" SG_ 879 ACU_NDASwitchReq 1;
BA_ "EventCommandSignal" SG_ 879 ACU_NDASwitchReq 0;
BA_ "GenSigSendType" SG_ 879 ACU_NDALCConSwitchReq 1;
BA_ "EventCommandSignal" SG_ 879 ACU_NDALCConSwitchReq 0;
BA_ "GenSigSendType" SG_ 879 ACU_NDALCStySwitchReq 1;
BA_ "EventCommandSignal" SG_ 879 ACU_NDALCStySwitchReq 0;
BA_ "GenSigSendType" SG_ 879 ACU_ADASWarnTypeSwitch 1;
BA_ "EventCommandSignal" SG_ 879 ACU_ADASWarnTypeSwitch 0;
BA_ "GenSigStartValue" SG_ 879 ACU_ESACfg 1;
BA_ "GenSigSendType" SG_ 879 ACU_ESACfg 1;
BA_ "EventCommandSignal" SG_ 879 ACU_ESACfg 0;
BA_ "GenSigStartValue" SG_ 879 ACU_ILCCfg 2;
BA_ "GenSigSendType" SG_ 879 ACU_ILCCfg 1;
BA_ "EventCommandSignal" SG_ 879 ACU_ILCCfg 0;
BA_ "GenSigStartValue" SG_ 879 ACU_AESCfg 3;
BA_ "GenSigSendType" SG_ 879 ACU_AESCfg 1;
BA_ "EventCommandSignal" SG_ 879 ACU_AESCfg 0;
BA_ "GenSigStartValue" SG_ 879 ACU_ILOACfg 3;
BA_ "GenSigSendType" SG_ 879 ACU_ILOACfg 1;
BA_ "EventCommandSignal" SG_ 879 ACU_ILOACfg 0;
BA_ "GenSigStartValue" SG_ 879 ACU_iACC_StyleConfirmSwitchReq 3;
BA_ "GenSigSendType" SG_ 879 ACU_iACC_StyleConfirmSwitchReq 1;
BA_ "EventCommandSignal" SG_ 879 ACU_iACC_StyleConfirmSwitchReq 0;
BA_ "GenSigSendType" SG_ 879 ACU_IFC_SpeedLimit 1;
BA_ "EventCommandSignal" SG_ 879 ACU_IFC_SpeedLimit 0;
BA_ "GenSigSendType" SG_ 879 ACU_IFC_ISDRestOfdis 1;
BA_ "EventCommandSignal" SG_ 879 ACU_IFC_ISDRestOfdis 0;
BA_ "GenSigSendType" SG_ 879 ACU_IFC_OfframpDis 1;
BA_ "EventCommandSignal" SG_ 879 ACU_IFC_OfframpDis 0;
BA_ "GenSigSendType" SG_ 879 ACU_IFC_SpeedLimitUnit 1;
BA_ "EventCommandSignal" SG_ 879 ACU_IFC_SpeedLimitUnit 0;
BA_ "GenSigTimeoutValue" SG_ 879 ACU_IFC_SpeedLimitUnit 1;
BA_ "GenSigSendType" SG_ 879 ACU_IFC_SpeedLimtType 1;
BA_ "EventCommandSignal" SG_ 879 ACU_IFC_SpeedLimtType 0;
BA_ "GenSigSendType" SG_ 879 ACU_IFC_RoadType 1;
BA_ "EventCommandSignal" SG_ 879 ACU_IFC_RoadType 0;
BA_ "GenSigSendType" SG_ 879 ACU_IFC_ZoneCode 1;
BA_ "EventCommandSignal" SG_ 879 ACU_IFC_ZoneCode 0;
BA_ "GenSigTimeoutValue" SG_ 879 ACU_IFC_ZoneCode 1;
BA_ "GenSigSendType" SG_ 879 ACU_IFC_NaviSt 1;
BA_ "EventCommandSignal" SG_ 879 ACU_IFC_NaviSt 0;
BA_ "GenSigSendType" SG_ 879 ACU_IFC_NaviCorp 1;
BA_ "EventCommandSignal" SG_ 879 ACU_IFC_NaviCorp 0;
BA_ "GenSigSendType" SG_ 879 ACU_IFC_NaviNewIconDis 1;
BA_ "EventCommandSignal" SG_ 879 ACU_IFC_NaviNewIconDis 0;
BA_ "GenSigSendType" SG_ 879 ACU_IFC_OfframpSt 1;
BA_ "EventCommandSignal" SG_ 879 ACU_IFC_OfframpSt 0;
BA_ "GenSigSendType" SG_ 879 ACU_IFC_NaviNewIcon 1;
BA_ "EventCommandSignal" SG_ 879 ACU_IFC_NaviNewIcon 0;
BA_ "GenSigSendType" SG_ 879 ACU_IFC_SLCAheadDis 1;
BA_ "EventCommandSignal" SG_ 879 ACU_IFC_SLCAheadDis 0;
BA_ "GenSigSendType" SG_ 879 ACU_ActiveNDAMessageSt 1;
BA_ "EventCommandSignal" SG_ 879 ACU_ActiveNDAMessageSt 0;
BA_ "GenSigSendType" SG_ 879 ACU_ActiveAVPMessageSt 1;
BA_ "EventCommandSignal" SG_ 879 ACU_ActiveAVPMessageSt 0;
BA_ "GenSigSendType" SG_ 879 ACU_LeftLaneChangeMessageSt 1;
BA_ "EventCommandSignal" SG_ 879 ACU_LeftLaneChangeMessageSt 0;
BA_ "GenSigSendType" SG_ 879 ACU_RigthLaneChangeMessageSt 1;
BA_ "EventCommandSignal" SG_ 879 ACU_RigthLaneChangeMessageSt 0;
BA_ "GenSigSendType" SG_ 879 ACU_ICANDAIconMessageSt 1;
BA_ "EventCommandSignal" SG_ 879 ACU_ICANDAIconMessageSt 0;
SIG_GROUP_ 363 EPS_1_C_E2E 1 : EPS_1_C_Dummy10 EPS_1_C_Dummy9 EPS_1_C_Dummy8 EPS_1_C_Dummy7 EPS_1_C_Dummy6 EPS_1_C_Dummy5 EPS_1_C_Dummy4 EPS_1_C_Dummy3 EPS_1_C_Dummy2 EPS_1_Counter EPS_SteeringAngle EPS_SteeringAngleVD EPS_FunctionStyleSt EPS_SteeringModeSt EPS_AssistRatio EPS_WarnLamp EPS_1_CRC;
SIG_GROUP_ 944 BMC_3_E2E 1 : BMS_ErrNoticeOperationFlag BMS_Err2NoticeFlag BMC_LvPwrSysMsgOperationFlag BMC_3_Dummy2 BMC_3_Dummy3 BMC_3_Dummy4 BMC_3_Dummy5 BMC_3_Dummy6 BMC_3_Dummy7 BMC_3_Dummy8 BMS_ErrNotice BMC_3_Counter BMC_3_CRC;
SIG_GROUP_ 739 IDC_ICM_2_E2E 1 : IDC_ICM_2_Dummy4 SID IDC_ICM_2_Dummy6 IDC_ICM_2_Dummy5 IDC_ICM_2_Dummy3 IDC_ICM_2_Dummy2 Reserve ICM_VehicleSpeed ICM_Theme ICM_SRSLamp ICM_PlugConnectLamp ICM_HandsOffLamp ICM_GearInfo ICM_FS_Enable ICM_ESPOFFLamp ICM_ESPLamp ICM_EPSLamp ICM_EPBLamp ICM_EPBFailLamp ICM_DynamicalsystemFailLamp ICM_DCDCFailLamp ICM_BrakeLamp ICM_ADAS4Lamp ICM_ADAS3Lamp ICM_ADAS2Lamp ICM_ADAS1Lamp ICM_ABSLamp IDC_IID_1_CRC IDC_IID_1_Counter DataLength;
SIG_GROUP_ 351 IDC_2_E2E 1 : ACU_PLGFuncCfg ACU_PLGTrunkReleaseReq ACU_PLGMaxPstReq ACU_LightShowTimeFlag ACU_PLGSetPstClearReq ACU_IALFunctionCfg ACU_PLGCloseReqVD ACU_HVAC_SolarFeaturesCfg ACU_PLGCloseReq ACU_PLGOpenReqVD ACU_PLGOpenReq ACU_HVACF_CirculationChangeReqFb ACU_AutoDomeLightCfg ACU_PLGCtrl ACU_SteeringHeatReq ACU_HVACF_TimedVentilationCfg ACU_DoorLookHornCfg ACU_HVACF_AutoDefCfg ACU_HVACFR_WindSpeedSetting ACU_FRSeatHeatModeReq ACU_FLSeatHeatModeReq ACU_FRSeatVentModeReq ACU_IALVoiceModeCfg ACU_IALMusicModeCfg ACU_ALSCfg ACU_VRPLGOpenReqVD ACU_IALColorSetReq ACU_IALBrightnessSetReq ACU_IALDriverModeCfg ACU_HeadLightDelayCfg ACU_PLGControlReq ACU_VRPLGCloseReqVD ACU_VRPLGCloseReq ACU_ClearSetPositionReq ACU_VRPLGOpenReq ACU_WelcomeLightMode ACU_LockAutoWinCloseFunCfgReq ACU_PosSaveRecallCmd ACU_FoldUnfoldCtlReq ACU_FRSeatAutoModeCfgReq ACU_FLSeatAutoModeCfgReq ACU_FRSeatVentLevelReq ACU_FRSeatHeatLevelReq ACU_FLSeatVentLevelReq ACU_FRSeatHeatVentModeReq ACU_FLSeatHeatLevelReq ACU_FLSeatVentModeReq ACU_LightShowFunCmd ACU_LightShowMode ACU_HeadLightLevelingVirtualSwSt ACU_VirtualPowerKeepReq ACU_RearWasherVRReq ACU_RWPServiceModeVRReq ACU_FrontAutoWiperEnableCfg ACU_RearWasherVKReq ACU_FWPServiceModeVRReq ACU_FWPServiceModeVKReq ACU_RWPServiceModeVKReq ACU_RearWiperVRReq ACU_FrontWiperVRReq ACU_FrontWiperVKReq ACU_FrontWiperAutoCfgVkReq ACU_HVACFR_PsnTempSetting ACU_FrontWasherVKReq ACU_FrontWasherVRReq ACU_Account_Delete ACU_FrontWiperIntCfgVkReq ACU_EasyEntryExitFuncCfg ACU_HVACF_VR_HVACONOFF ACU_SeatNapSettingSaveCmd ACU_ShortcutMode ACU_VehicleSearchHornCfg ACU_HVAC_RearWindSpdSet ACU_MirrorAngleDipFuncCfg ACU_MirrorAutoFoldFuncCfg ACU_HVAC_RearMODESetting ACU_HVACFR_ModeSetting ACU_WCM_SwitchStCfg ACU_HVACF_EvapratorSelfCleanCfg ACU_MultiIDManageReq ACU_HVACF_UnlockVentilationCfg ACU_HVAC_FraganceConcentrationSt ACU_HVACFR_DrTempSetting ACU_HVAC_ComfortCfg ACU_HVACF_FanspeedCfg ACU_Account_Uld ACU_HVACFR_RrTempSetting ACU_HVAC_FraganceTasteSt ACU_HVACF_PM25CleanReqFb ACU_HVAC_AirCirCfg ACU_APUCfg ACU_RRSeatAutoModeCfgReq ACU_HVACF_AQSCfg ACU_SATOCfg ACU_SeatNapPopUpReq ACU_WALCfg ACU_VirtualPowerOFFReqVd ACU_RLSeatVentLevelReq IDC_2_Dummy3 IDC_2_Dummy5 ACU_ETC_BLEenableCfg ACU_FRSeatSaveRecallPstReq ACU_ETC_SysCfg ACU_RearCamWasherVKReq ACU_RearCamWasherVRReq ACU_FRSeatSaveRecallReq ACU_HVACF_CO2CleanReqFb ACU_RLSeatAutoModeCfgReq ACU_VirtualPowerKeepReqVd ACU_HVACFInCarAutoVentilationCfg ACU_ETC_ICMDisplayCfg ACU_EEM_LoadControl ACU_VirtualPowerOFFReq ACU_FLLumbarReq ACU_HVACF_CO2LifeAlarmModeCfg IDC_2_Dummy16 ACU_RRSeatVentLevelReq IDC_2_Dummy7 ACU_RRSeatHeatLevelReq ACU_RLSeatHeatLevelReq IDC_2_CRC IDC_2_Dummy8 IDC_2_Dummy6 IDC_2_Counter IDC_2_Dummy2 IDC_2_Dummy4 IDC_2_Dummy1 IDC_2_Dummy15 IDC_2_Dummy14 IDC_2_Dummy13 IDC_2_Dummy10 IDC_2_Dummy9 IDC_2_Dummy12 IDC_2_Dummy11 IDC_2_Dummy17;
SIG_GROUP_ 879 IDC_3_E2E 1 : ACU_SteeringPrkgButton ACU_VR_APAControl ACU_PCS_SVM_MODCmd ACU_DVR_Switch IDC_3_Dummy11 ACU_PAS_ButtonPress ACU_ThemeType ACU_ICANDAIconMessageSt ACU_ActiveNDAMessageSt ACU_ActiveAVPMessageSt ACU_LeftLaneChangeMessageSt ACU_RigthLaneChangeMessageSt ACU_IFC_SLCAheadDis ACU_IFC_NaviNewIcon ACU_IFC_NaviNewIconDis ACU_IFC_OfframpSt ACU_IFC_ZoneCode ACU_IFC_NaviSt ACU_IFC_NaviCorp ACU_IFC_SpeedLimtType ACU_IFC_RoadType ACU_IFC_OfframpDis ACU_IFC_SpeedLimitUnit ACU_IFC_ISDRestOfdis ACU_IFC_SpeedLimit ACU_iACC_StyleConfirmSwitchReq ACU_ESACfg ACU_ILCCfg ACU_AESCfg ACU_ILOACfg ACU_NDASwitchReq ACU_NDALCConSwitchReq ACU_NDALCStySwitchReq ACU_ADASWarnTypeSwitch ACU_FCTACfg ACU_RAWCfg ACU_RCTA_TypeReqCfg ACU_FCTA_TypeReqCfg ACU_HWAHFCfg ACU_HWAHF_AudioWarningTypeCfg ACU_HWA_SwitchReq ACU_ELKCfg ACU_RCTACfg ACU_DOWCfg ACU_iACC_SwitchReq ACU_TSR_AudioWarnReq ACU_TSR_SwitchReq ACU_IHBC_SwitchReq ACU_LDS_TypeReq ACU_BSDCfg ACU_FCWWarnDistanceCfg ACU_FCWCfg ACU_AEBOff ACU_LDW_LKACfg ACU_Account_Uid ACU_HeadLightVirtualSwSt ACU_FrontFogLightVirtualSwSt ACU_RearFogLightVirtualSwSt ACU_HighBeamVirtualSwSt IDC_3_RollingCounter IDC_3_Checksum IDC_3_Dummy10 IDC_3_Dummy9 IDC_3_Dummy7 IDC_3_Dummy6 IDC_3_Dummy5 IDC_3_Dummy3 IDC_3_Dummy4 IDC_3_Dummy2 IDC_3_Dummy1;
